VERSION ""

NS_ :

BS_:

BU_: GW BMS PDU EDS_F VCU EAC EVCC
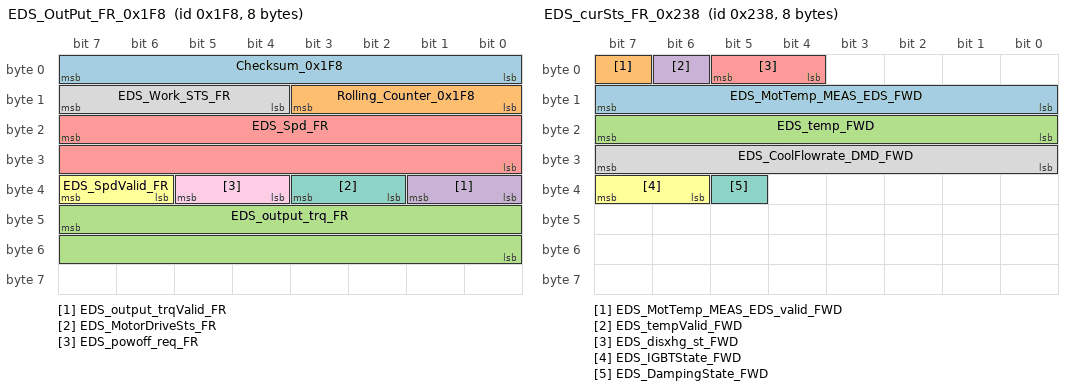
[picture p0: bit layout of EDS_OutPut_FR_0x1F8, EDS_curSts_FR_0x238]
BO_ 504 EDS_OutPut_FR_0x1F8: 8 EDS_F
 SG_ Checksum_0x1F8 : 7|8@0+ (1,0) [0|255] "" GW,BMS,VCU
 SG_ Rolling_Counter_0x1F8 : 11|4@0+ (1,0) [0|15] "" GW,BMS,VCU
 SG_ EDS_output_trq_FR : 47|16@0+ (1,-2000) [-2000|2000] "Nm" GW,BMS,VCU
 SG_ EDS_output_trqValid_FR : 33|2@0+ (1,0) [0|1] "" GW,BMS,VCU
 SG_ EDS_Spd_FR : 23|16@0+ (1,-20000) [-20000|20000] "rpm" GW,BMS,VCU
 SG_ EDS_SpdValid_FR : 39|2@0+ (1,0) [0|1] "" GW,BMS,VCU
 SG_ EDS_MotorDriveSts_FR : 35|2@0+ (1,0) [0|3] "" GW,BMS,VCU
 SG_ EDS_Work_STS_FR : 15|4@0+ (1,0) [0|15] "" GW,BMS,VCU
 SG_ EDS_powoff_req_FR : 37|2@0+ (1,0) [0|1] "" GW,BMS,VCU

BO_ 680 EDS_Power_FR_0x2A8: 8 EDS_F
 SG_ Checksum_0x2A8 : 7|8@0+ (1,0) [0|255] "" VCU
 SG_ Rolling_Counter_0x2A8 : 11|4@0+ (1,0) [0|15] "" VCU
 SG_ EDS_MotorSerialNum_FWD : 15|1@0+ (1,0) [0|1] "" VCU
 SG_ EDS_MinTrq_FWD : 39|16@0+ (1,-2000) [-2000|2000] "Nm" VCU
 SG_ EDS_MaxTrq_FWD : 23|16@0+ (1,-2000) [-2000|2000] "Nm" VCU

BO_ 568 EDS_curSts_FR_0x238: 8 EDS_F
 SG_ EDS_MotTemp_MEAS_EDS_FWD : 15|8@0+ (1,-40) [-40|215] "degree" VCU
 SG_ EDS_MotTemp_MEAS_EDS_valid_FWD : 7|1@0+ (1,0) [0|1] "" VCU
 SG_ EDS_temp_FWD : 23|8@0+ (1,-40) [-40|215] "degree" VCU
 SG_ EDS_tempValid_FWD : 6|1@0+ (1,0) [0|1] "" VCU
 SG_ EDS_disxhg_st_FWD : 5|2@0+ (1,0) [0|3] "" VCU
 SG_ EDS_IGBTState_FWD : 39|2@0+ (1,0) [0|3] "" VCU
 SG_ EDS_DampingState_FWD : 37|1@0+ (1,0) [0|1] "" VCU
 SG_ EDS_CoolFlowrate_DMD_FWD : 31|8@0+ (0.1,0) [0|25.4] "L/min" VCU

BO_ 1080 EDS_Error_FR_0x438: 8 EDS_F
 SG_ EDS_FailNum_ERR_FWD : 7|8@0+ (1,0) [0|255] "" BMS,VCU
 SG_ EDS_FailGrade_ERR_FWD : 10|3@0+ (1,0) [0|7] "" BMS,VCU
 SG_ EDS_MotOverTempAlarm_FWD : 11|1@0+ (1,0) [0|1] "" BMS,VCU
 SG_ EDS_MotOverTempFault_FWD : 12|1@0+ (1,0) [0|1] "" BMS,VCU
 SG_ EDS_MotTempSenFault_FWD : 13|1@0+ (1,0) [0|1] "" BMS,VCU
 SG_ EDS_EDSOverTempUFault_FWD : 14|1@0+ (1,0) [0|1] "" BMS,VCU
 SG_ EDS_EDSOverTempVFault_FWD : 15|1@0+ (1,0) [0|1] "" BMS,VCU
 SG_ EDS_EDSOverTempWFault_FWD : 16|1@0+ (1,0) [0|1] "" BMS,VCU
 SG_ EDS_EDSOverTempAlarm_FWD : 17|1@0+ (1,0) [0|1] "" BMS,VCU
 SG_ EDS_TCoolantOvHi_FWD : 18|1@0+ (1,0) [0|1] "" BMS,VCU
 SG_ EDS_EDSTempCmpAlarm_FWD : 19|1@0+ (1,0) [0|1] "" BMS,VCU
 SG_ EDS_EDSPhaOvCurentHWFault_FWD : 20|1@0+ (1,0) [0|1] "" BMS,VCU
 SG_ EDS_EDSphaOffCalFault_FWD : 21|1@0+ (1,0) [0|1] "" BMS,VCU
 SG_ EDS_EDSOverIdcLnkAlarm_FWD : 22|1@0+ (1,0) [0|1] "" BMS,VCU
 SG_ EDS_EDSHVOverVoltageAlarm_FWD : 23|1@0+ (1,0) [0|1] "" BMS,VCU
 SG_ EDS_EDSHVOverVoltageFault_FWD : 24|1@0+ (1,0) [0|1] "" BMS,VCU
 SG_ EDS_EDSHVUnderVoltageAlarm_FWD : 25|1@0+ (1,0) [0|1] "" BMS,VCU
 SG_ EDS_EDSHVUnderVoltageFault_FWD : 26|1@0+ (1,0) [0|1] "" BMS,VCU
 SG_ EDS_RunToDischaErr_FWD : 27|1@0+ (1,0) [0|1] "" BMS,VCU
 SG_ EDS_12VOverVoltageAlarm_FWD : 28|1@0+ (1,0) [0|1] "" BMS,VCU
 SG_ EDS_12VUnderVoltageAlarm_FWD : 29|1@0+ (1,0) [0|1] "" BMS,VCU
 SG_ EDS_MotOverAlarm_FWD : 30|1@0+ (1,0) [0|1] "" BMS,VCU
 SG_ EDS_MotOverFault_FWD : 31|1@0+ (1,0) [0|1] "" BMS,VCU
 SG_ EDS_iDcLnkOvCLimFail_FWD : 32|1@0+ (1,0) [0|1] "" BMS,VCU
 SG_ EDS_MotBlockedFault_FWD : 33|1@0+ (1,0) [0|1] "" BMS,VCU
 SG_ EDS_RSLErr_FWD : 34|1@0+ (1,0) [0|1] "" BMS,VCU
 SG_ EDS_MotTrqLimFault_FWD : 35|1@0+ (1,0) [0|1] "" BMS,VCU
 SG_ EDS_ResolverOffsetAngle_FWD : 36|1@0+ (1,0) [0|1] "" BMS,VCU
 SG_ EDS_EDSDisChgFault_FWD : 37|1@0+ (1,0) [0|1] "" BMS,VCU
 SG_ EDS_IGBTFault_FWD : 38|1@0+ (1,0) [0|1] "" BMS,VCU
 SG_ EDS_CANBusoffFault_FWD : 39|1@0+ (1,0) [0|1] "" BMS,VCU
 SG_ EDS_TDrvBoardOvHiWarn_FWD : 40|1@0+ (1,0) [0|1] "" BMS,VCU
 SG_ EDS_TIGBTOvHiFault_FWD : 41|1@0+ (1,0) [0|1] "" BMS,VCU
 SG_ EDS_TIGBTOvHiWarn_FWD : 42|1@0+ (1,0) [0|1] "" BMS,VCU
 SG_ EDS_IOHWABSampFail_FWD : 43|1@0+ (1,0) [0|1] "" BMS,VCU
 SG_ EDS_EDSOpenFault_FWD : 44|1@0+ (1,0) [0|1] "" BMS,VCU
 SG_ EDS_MotorOpenFault_FWD : 45|1@0+ (1,0) [0|1] "" BMS,VCU
 SG_ EDS_EmacBlkdWarn_FWD : 47|1@0+ (1,0) [0|1] "" BMS,VCU
 SG_ EDS_VerMatchFailureErr_FWD : 48|1@0+ (1,0) [0|1] "" BMS,VCU
 SG_ EDS_DiashCirNoPsblErr_FWD : 49|1@0+ (1,0) [0|1] "" BMS,VCU
 SG_ EDS_OperOutdRngErr_FWD : 50|1@0+ (1,0) [0|1] "" BMS,VCU
 SG_ EDS_PhaseLossFaultErr_FWD : 51|1@0+ (1,0) [0|1] "" BMS,VCU
 SG_ EDS_CPLDFault_FWD : 52|1@0+ (1,0) [0|1] "" BMS,VCU
 SG_ EDS_CPLDFaultBaseSpd_FWD : 53|1@0+ (1,0) [0|1] "" BMS,VCU
 SG_ EDS_IOHWABNen33Fail_FWD : 54|1@0+ (1,0) [0|1] "" BMS,VCU
 SG_ EDS_HvMcuSlightFault_RWD : 55|1@0+ (1,0) [0|1] "" BMS,VCU
 SG_ EDS_HvMcuSevFault_FWD : 56|1@0+ (1,0) [0|1] "" BMS,VCU
 SG_ EDS_EDSPhaSampHWFault_FWD : 57|1@0+ (1,0) [0|1] "" BMS,VCU
 SG_ EDS_IsOvHiErr_FWD : 58|1@0+ (1,0) [0|1] "" BMS,VCU
 SG_ EDS_CanRollingCounterErr_FWD : 59|1@0+ (1,0) [0|1] "" BMS,VCU
 SG_ EDS_CanTimeoutErr_FWD : 60|1@0+ (1,0) [0|1] "" BMS,VCU
 SG_ EDS_CrashFault_FWD : 61|1@0+ (1,0) [0|1] "" BMS,VCU

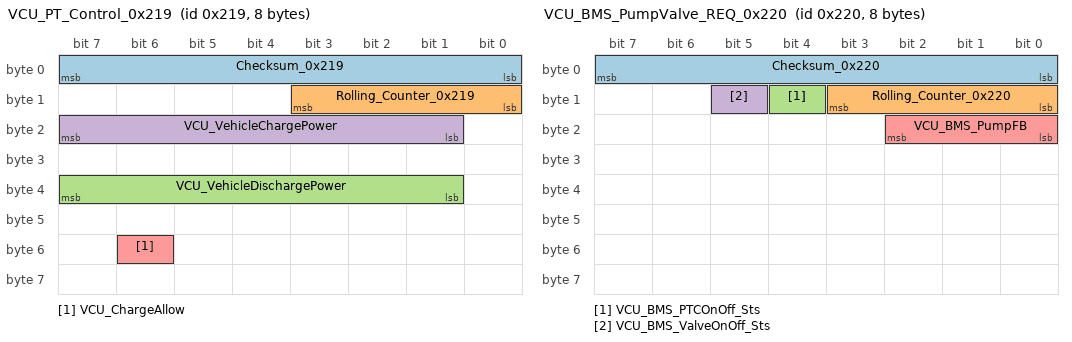
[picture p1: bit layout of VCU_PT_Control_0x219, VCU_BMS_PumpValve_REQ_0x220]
BO_ 537 VCU_PT_Control_0x219: 8 VCU
 SG_ Checksum_0x219 : 7|8@0+ (1,0) [0|255] "" GW,BMS
 SG_ Rolling_Counter_0x219 : 11|4@0+ (1,0) [0|15] "" GW,BMS
 SG_ VCU_VehicleDischargePower : 39|7@0+ (1,0) [0|100] "%" GW
 SG_ VCU_VehicleChargePower : 23|7@0+ (1,0) [0|100] "%" GW
 SG_ VCU_ChargeAllow : 54|1@0+ (1,0) [0|1] "" BMS

BO_ 544 VCU_BMS_PumpValve_REQ_0x220: 8 VCU
 SG_ Checksum_0x220 : 7|8@0+ (1,0) [0|255] "" BMS
 SG_ Rolling_Counter_0x220 : 11|4@0+ (1,0) [0|15] "" BMS
 SG_ VCU_BMS_PTCOnOff_Sts : 12|1@0+ (1,0) [0|1] "" BMS
 SG_ VCU_BMS_ValveOnOff_Sts : 13|1@0+ (1,0) [0|1] "" BMS
 SG_ VCU_BMS_PumpFB : 18|3@0+ (1,0) [0|7] "" BMS

BO_ 757 VCU_Chgcontrol_0x2F5: 8 VCU
 SG_ VCU_Charge_Control : 23|2@0+ (1,0) [0|3] "" BMS,PDU,EVCC
 SG_ VCU_AC_chargeSock_temp1 : 18|11@0+ (0.1,-50) [-50|100] "degree" BMS,EVCC
 SG_ VCU_DC_chargeSock_temp1 : 34|11@0+ (0.1,-50) [-50|100] "degree" BMS,EVCC
 SG_ VCU_DC_chargeSock_temp2 : 50|11@0+ (0.1,-50) [-50|100] "degree" BMS,EVCC

BO_ 725 VCU_DCDCcontrol_0x2D5: 8 VCU
 SG_ VCU_DCDC_Output_REQ : 55|1@0+ (1,0) [0|1] "" GW,PDU
 SG_ VCU_DCDC_OutVoltage_REQ : 32|9@0+ (0.1,0) [0|50] "V" GW,PDU
 SG_ VCU_DCDCAllowedPower : 16|9@0+ (0.1,0) [0|50] "KW" GW,PDU

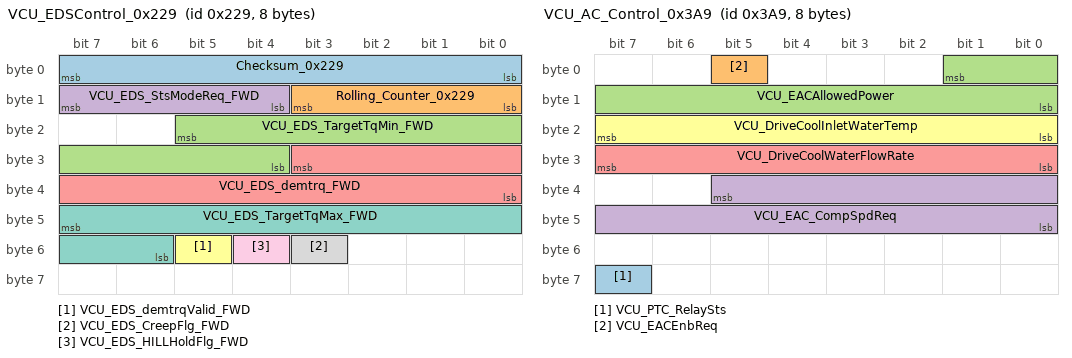
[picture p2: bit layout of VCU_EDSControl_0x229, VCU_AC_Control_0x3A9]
BO_ 553 VCU_EDSControl_0x229: 8 VCU
 SG_ Checksum_0x229 : 7|8@0+ (1,0) [0|255] "" EDS_F
 SG_ Rolling_Counter_0x229 : 11|4@0+ (1,0) [0|15] "" EDS_F
 SG_ VCU_EDS_TargetTqMin_FWD : 21|10@0+ (1,-500) [-500|0] "Nm" EDS_F
 SG_ VCU_EDS_StsModeReq_FWD : 15|4@0+ (1,0) [0|15] "" EDS_F
 SG_ VCU_EDS_demtrq_FWD : 27|12@0+ (0.5,-500) [-500|500] "Nm" EDS_F
 SG_ VCU_EDS_demtrqValid_FWD : 53|1@0+ (1,0) [0|1] "" EDS_F
 SG_ VCU_EDS_TargetTqMax_FWD : 47|10@0+ (1,0) [0|500] "Nm" EDS_F
 SG_ VCU_EDS_CreepFlg_FWD : 51|1@0+ (1,0) [0|1] "" Vector__XXX
 SG_ VCU_EDS_HILLHoldFlg_FWD : 52|1@0+ (1,0) [0|1] "" Vector__XXX

BO_ 937 VCU_AC_Control_0x3A9: 8 VCU
 SG_ VCU_PTC_RelaySts : 63|1@0+ (1,0) [0|1] "" GW,BMS,EAC
 SG_ VCU_EACEnbReq : 5|1@0+ (1,0) [0|1] "" GW,EAC
 SG_ VCU_EACAllowedPower : 1|10@0+ (0.1,0) [0|100] "KW" GW,EAC
 SG_ VCU_EAC_CompSpdReq : 37|14@0+ (1,0) [0|16383] "rpm" GW,EAC
 SG_ VCU_DriveCoolWaterFlowRate : 31|8@0+ (0.1,0) [0|25.4] "L/min" GW,EDS_F,EAC
 SG_ VCU_DriveCoolInletWaterTemp : 23|8@0+ (1,-40) [-40|215] "degree" GW,EDS_F,EAC

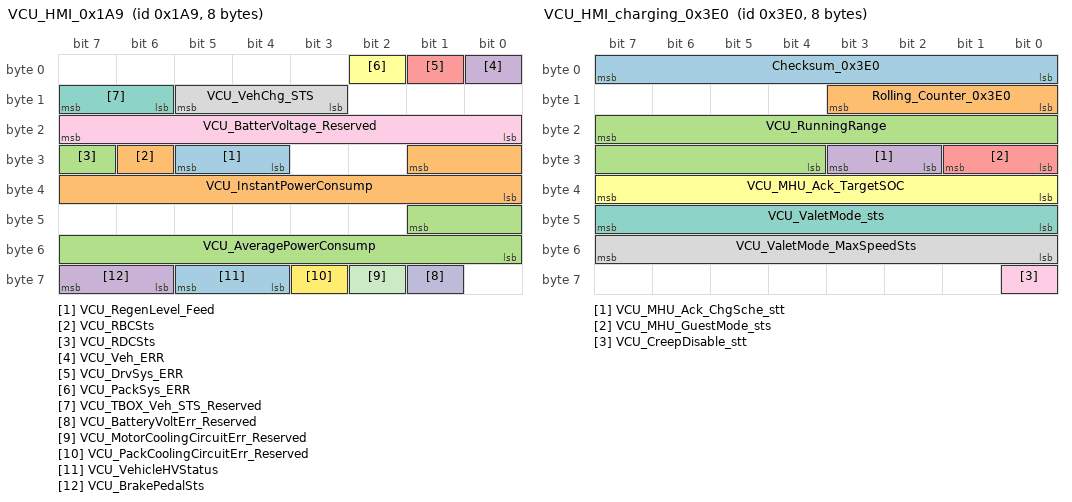
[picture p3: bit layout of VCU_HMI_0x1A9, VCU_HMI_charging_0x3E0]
BO_ 425 VCU_HMI_0x1A9: 8 VCU
 SG_ VCU_RegenLevel_Feed : 29|2@0+ (1,0) [0|3] "" GW
 SG_ VCU_RBCSts : 30|1@0+ (1,0) [0|1] "" GW
 SG_ VCU_RDCSts : 31|1@0+ (1,0) [0|1] "" GW
 SG_ VCU_Veh_ERR : 0|1@0+ (1,0) [0|1] "" GW,BMS
 SG_ VCU_DrvSys_ERR : 1|1@0+ (1,0) [0|1] "" GW,BMS
 SG_ VCU_PackSys_ERR : 2|1@0+ (1,0) [0|1] "" GW,BMS
 SG_ VCU_TBOX_Veh_STS_Reserved : 15|2@0+ (1,0) [0|3] "" GW,BMS
 SG_ VCU_VehChg_STS : 13|3@0+ (1,0) [0|7] "" GW,BMS
 SG_ VCU_BatterVoltage_Reserved : 23|8@0+ (0.07,0) [0|17.85] "V" GW,BMS
 SG_ VCU_BatteryVoltErr_Reserved : 57|1@0+ (1,0) [0|1] "" GW,BMS
 SG_ VCU_MotorCoolingCircuitErr_Reserved : 58|1@0+ (1,0) [0|1] "" GW,BMS
 SG_ VCU_PackCoolingCircuitErr_Reserved : 59|1@0+ (1,0) [0|1] "" GW,BMS
 SG_ VCU_VehicleHVStatus : 61|2@0+ (1,0) [0|3] "" GW,BMS,EVCC
 SG_ VCU_InstantPowerConsump : 25|10@0+ (0.1,0) [0|100] "kwh/100km" GW,BMS
 SG_ VCU_AveragePowerConsump : 41|10@0+ (0.1,0) [0|100] "kwh/100km" GW,BMS
 SG_ VCU_BrakePedalSts : 63|2@0+ (1,0) [0|3] "" GW,BMS

BO_ 441 VCU_HMI2_0x1B9: 8 VCU
 SG_ VCU_MCUConsumepower : 15|9@0+ (0.1,0) [0|50] "kw" GW
 SG_ VCU_EACConsumepower : 16|9@0+ (0.1,0) [0|50] "kw" GW
 SG_ VCU_DCDCConsumepower : 32|9@0+ (0.1,0) [0|50] "kw" GW
 SG_ VCU_PTCConsumepower : 48|9@0+ (0.1,0) [0|50] "kw" GW

BO_ 992 VCU_HMI_charging_0x3E0: 8 VCU
 SG_ Checksum_0x3E0 : 7|8@0+ (1,0) [0|255] "" GW
 SG_ Rolling_Counter_0x3E0 : 11|4@0+ (1,0) [0|15] "" GW
 SG_ VCU_RunningRange : 23|12@0+ (0.5,0) [0|2047] "km" GW
 SG_ VCU_MHU_Ack_ChgSche_stt : 27|2@0+ (1,0) [0|3] "" GW
 SG_ VCU_MHU_GuestMode_sts : 25|2@0+ (1,0) [0|3] "" GW
 SG_ VCU_MHU_Ack_TargetSOC : 39|8@0+ (1,0) [0|100] "%" GW,BMS
 SG_ VCU_ValetMode_sts : 47|8@0+ (1,0) [0|255] "" GW
 SG_ VCU_ValetMode_MaxSpeedSts : 55|8@0+ (1,0) [0|255] "kph" GW
 SG_ VCU_CreepDisable_stt : 56|1@0+ (1,0) [0|1] "" GW

BO_ 409 VCU_Sts_0x199: 8 VCU
 SG_ Checksum_0x199 : 7|8@0+ (1,0) [0|255] "" BMS,EVCC
 SG_ Rolling_Counter_0x199 : 11|4@0+ (1,0) [0|15] "" BMS,EVCC
 SG_ VCU_VehFailGrade_ERR : 22|3@0+ (1,0) [0|7] "" Vector__XXX
 SG_ VCU_BMS_HVOnOff_REQ : 19|2@0+ (1,0) [0|1] "" BMS,EVCC
 SG_ VCU_Vehicle_Mode : 31|4@0+ (1,0) [0|15] "" BMS,EVCC

BO_ 889 VCU_Sts2_0x379: 8 VCU
 SG_ VCU_DriveCoolWaterPumpSts : 2|3@0+ (1,0) [0|5] "" GW
 SG_ VCU_DriveCoolWaterDuty : 14|7@0+ (1,0) [0|100] "%" GW
 SG_ VCU_BatteryWaterPumpSts_reserved : 30|3@0+ (1,0) [0|7] "" GW
 SG_ VCU_BatteryWaterPumpDuty_reserved : 22|7@0+ (1,0) [0|100] "%" GW
 SG_ VCU_DriveMode : 5|3@0+ (1,0) [0|7] "" GW
 SG_ VCU_ActualGear : 26|3@0+ (1,0) [0|7] "" GW
 SG_ VCU_ACTGearValid : 27|1@0+ (1,0) [0|1] "" GW
 SG_ VCU_AccPedal1OutRange : 31|1@0+ (1,0) [0|1] "" GW
 SG_ VCU_AccPedal2OutRange : 33|1@0+ (1,0) [0|1] "" GW
 SG_ VCU_BrkPedal1OutRange : 35|1@0+ (1,0) [0|1] "" GW
 SG_ VCU_BrkPedal2OutRange : 37|1@0+ (1,0) [0|1] "" GW
 SG_ VCU_BrkPedalPct : 47|8@0+ (0.4,0) [0|100] "%" GW
 SG_ VCU_AccPedalPosition : 55|8@0+ (0.4,0) [0|100] "%" GW
 SG_ VCU_AccPedalPositionValid : 63|1@0+ (1,0) [0|1] "" GW
 SG_ VCU_SocDisplay_EST : 62|7@0+ (1,0) [0|100] "%" GW,EVCC
 SG_ VCU_PowerLimit : 15|1@0+ (1,0) [0|1] "" GW
 SG_ VCU_CruiseCtrlSts : 39|2@0+ (1,0) [0|3] "" GW
 SG_ VCU_LowSOC_ERR : 23|1@0+ (1,0) [0|1] "" GW

BO_ 905 VCU_Sts3_0x389: 8 VCU
 SG_ VCU_FanControl_Sts : 1|2@0+ (1,0) [0|3] "" GW
 SG_ VCU_HVACInletWateTemp : 55|8@0+ (1,-40) [-40|215] "degree" GW
 SG_ VCU_IMMO_Sts : 35|2@0+ (1,0) [0|2] "" GW
 SG_ VCU_VacuumSts_reserved : 39|2@0+ (1,0) [0|3] "" GW
 SG_ VCU_VacuumPresWrn : 37|2@0+ (1,0) [0|3] "" GW

BO_ 273 VCU_Sts4_0x111: 8 VCU
 SG_ VCU_Sts : 7|8@0+ (1,0) [0|254] "" Vector__XXX

BO_ 1145 VCU_Error_0x479: 8 VCU
 SG_ VCU_OtherFaultNum_Reserved : 7|8@0+ (1,0) [0|255] "" Vector__XXX
 SG_ VCU_EDSCAN_ERR : 32|1@0+ (1,0) [0|1] "" Vector__XXX
 SG_ VCU_BmsCAN_ERR : 33|1@0+ (1,0) [0|1] "" Vector__XXX
 SG_ VCU_DcdcCAN_ERR : 34|1@0+ (1,0) [0|1] "" Vector__XXX
 SG_ VCU_AbsCAN_ERR : 35|1@0+ (1,0) [0|1] "" Vector__XXX
 SG_ VCU_AcmCAN_ERR : 36|1@0+ (1,0) [0|1] "" Vector__XXX
 SG_ VCU_XgwCAN_ERR : 37|1@0+ (1,0) [0|1] "" Vector__XXX
 SG_ VCU_ObcCAN_ERR : 38|1@0+ (1,0) [0|1] "" Vector__XXX
 SG_ VCU_BcmCAN_ERR_reserved : 39|1@0+ (1,0) [0|1] "" Vector__XXX
 SG_ VCU_WaterPump_ERR : 40|1@0+ (1,0) [0|1] "" Vector__XXX
 SG_ VCU_BrakeSys_Err : 41|1@0+ (1,0) [0|1] "" Vector__XXX
 SG_ VCU_PreChgFail_ERR_Reserved : 42|1@0+ (1,0) [0|1] "" Vector__XXX
 SG_ VCU_LowBattery_ERR : 43|1@0+ (1,0) [0|1] "" Vector__XXX
 SG_ VCU_AccPed_ERR : 44|1@0+ (1,0) [0|1] "" Vector__XXX
 SG_ VCU_BrkPed_ERR : 45|1@0+ (1,0) [0|1] "" Vector__XXX
 SG_ VCU_EPSCAN_ERR : 46|1@0+ (1,0) [0|1] "" Vector__XXX
 SG_ VCU_PtcModu_ERR_Reserved : 47|1@0+ (1,0) [0|1] "" Vector__XXX
 SG_ VCU_Shift_ERR : 48|1@0+ (1,0) [0|1] "" GW
 SG_ VCU_FlgHVIL_ERR : 49|1@0+ (1,0) [0|1] "" Vector__XXX
 SG_ VCU_EKSCAN_ERR : 50|1@0+ (1,0) [0|1] "" Vector__XXX
 SG_ VCU_VehLvInit_ERR_Reserved : 51|1@0+ (1,0) [0|1] "" Vector__XXX
 SG_ VCU_EacCAN_ERR : 52|1@0+ (1,0) [0|1] "" Vector__XXX
 SG_ VCU_EAC_CompFltStat_ERR : 53|1@0+ (1,0) [0|1] "" Vector__XXX

BO_ 745 VCU_Mileage_0x2E9: 8 VCU
 SG_ Checksum_0x2E9 : 7|8@0+ (1,0) [0|255] "" GW
 SG_ Rolling_Counter_0x2E9 : 11|4@0+ (1,0) [0|15] "" GW
 SG_ VCU_RemainingMileage : 23|32@0+ (0.1,0) [0|1000] "KM" GW
 SG_ VCU_SetCruiseSpd : 55|8@0+ (1,0) [0|200] "km/h" GW

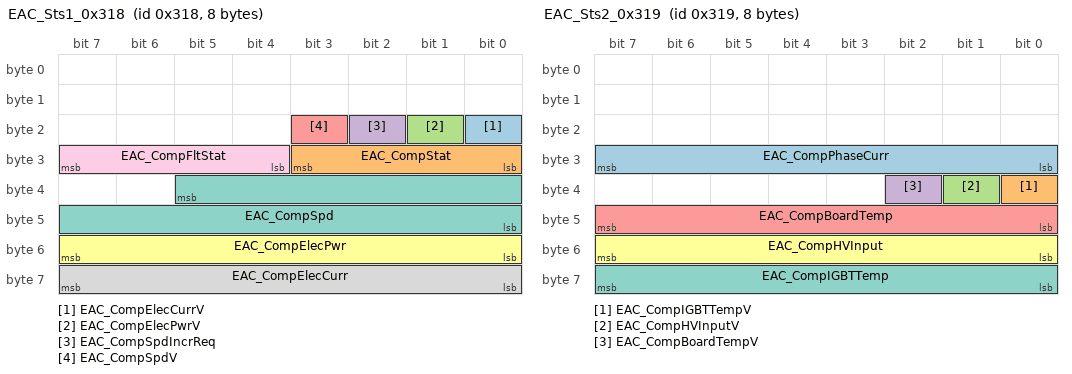
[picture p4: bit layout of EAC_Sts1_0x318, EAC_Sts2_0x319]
BO_ 792 EAC_Sts1_0x318: 8 EAC
 SG_ EAC_CompElecCurrV : 16|1@0+ (1,0) [0|1] "" GW,BMS,VCU
 SG_ EAC_CompStat : 27|4@0+ (1,0) [0|15] "" GW,VCU
 SG_ EAC_CompElecPwrV : 17|1@0+ (1,0) [0|1] "" GW,BMS,VCU
 SG_ EAC_CompSpdIncrReq : 18|1@0+ (1,0) [0|1] "" GW,VCU
 SG_ EAC_CompSpdV : 19|1@0+ (1,0) [0|1] "" GW,VCU
 SG_ EAC_CompElecPwr : 55|8@0+ (40,0) [0|10200] "W" GW,BMS,VCU
 SG_ EAC_CompSpd : 37|14@0+ (1,0) [0|16383] "rpm" GW,VCU
 SG_ EAC_CompElecCurr : 63|8@0+ (0.2,0) [0|51] "A" GW,VCU
 SG_ EAC_CompFltStat : 31|4@0+ (1,0) [0|15] "" GW,VCU

BO_ 793 EAC_Sts2_0x319: 8 EAC
 SG_ EAC_CompPhaseCurr : 31|8@0+ (0.2,0) [0|51] "A" Vector__XXX
 SG_ EAC_CompIGBTTempV : 32|1@0+ (1,0) [0|1] "" VCU
 SG_ EAC_CompHVInputV : 33|1@0+ (1,0) [0|1] "" VCU
 SG_ EAC_CompBoardTempV : 34|1@0+ (1,0) [0|1] "" VCU
 SG_ EAC_CompBoardTemp : 47|8@0+ (1,-40) [-40|215] "deg C" VCU
 SG_ EAC_CompHVInput : 55|8@0+ (4,0) [0|1020] "V" VCU
 SG_ EAC_CompIGBTTemp : 63|8@0+ (1,-40) [-40|215] "deg C" VCU

BO_ 524 GW_IPC_ODO_0x20C: 8 GW
 SG_ Checksum_0x20C : 7|8@0+ (1,0) [0|255] "" BMS,PDU,EDS_F,VCU,EAC,EVCC
 SG_ Rolling_Counter_0x20C : 11|4@0+ (1,0) [0|15] "" BMS,PDU,EDS_F,VCU,EAC,EVCC
 SG_ IPC_ODO : 31|20@0+ (1,0) [0|999999] "km" BMS,PDU,EDS_F,VCU,EAC,EVCC

BO_ 703 GW_IPC_Information_0x2BF: 8 GW
 SG_ IPC_TripA : 7|16@0+ (0.1,0) [0|999.9] "km" Vector__XXX
 SG_ IPC_AverageSpeedTripA : 27|12@0+ (0.0625,0) [0|250] "km/h" Vector__XXX
 SG_ IPC_AverageConsumptionTripA : 23|10@0+ (0.1,0) [0|100] "kwh/100km" Vector__XXX
 SG_ IPC_ParkBrakeSts : 29|2@0+ (1,0) [0|3] "" VCU,EVCC
 SG_ IPC_VehSpd : 54|15@0+ (0.01,0) [0|327.66] "kph" BMS,PDU,EDS_F,VCU,EAC,EVCC

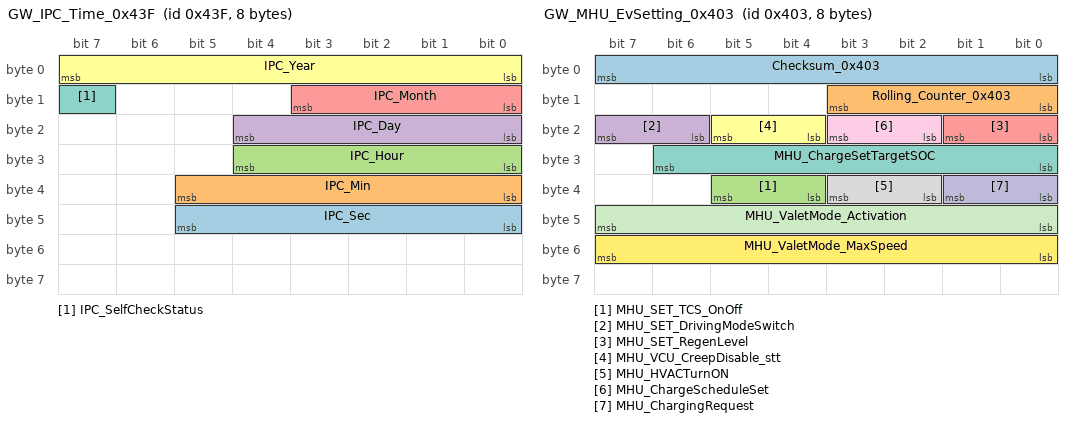
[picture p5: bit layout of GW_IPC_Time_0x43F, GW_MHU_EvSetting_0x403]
BO_ 1087 GW_IPC_Time_0x43F: 8 GW
 SG_ IPC_Sec : 45|6@0+ (1,0) [0|59] "second" BMS,PDU,EDS_F,VCU,EAC,EVCC
 SG_ IPC_Min : 37|6@0+ (1,0) [0|59] "min" BMS,PDU,EDS_F,VCU,EAC,EVCC
 SG_ IPC_Hour : 28|5@0+ (1,0) [0|23] "hour" BMS,PDU,EDS_F,VCU,EAC,EVCC
 SG_ IPC_Day : 20|5@0+ (1,0) [1|31] "" BMS,PDU,EDS_F,VCU,EAC,EVCC
 SG_ IPC_Month : 11|4@0+ (1,0) [1|12] "" BMS,PDU,EDS_F,VCU,EAC,EVCC
 SG_ IPC_Year : 7|8@0+ (1,2000) [2000|2255] "" BMS,PDU,EDS_F,VCU,EAC,EVCC
 SG_ IPC_SelfCheckStatus : 15|1@0+ (1,0) [0|1] "" BMS,PDU,EDS_F,VCU,EAC,EVCC

BO_ 1074 GW_TELEMATICS_SERVICES_0x432: 8 GW
 SG_ Checksum_0x432 : 7|8@0+ (1,0) [0|255] "" BMS,PDU,EDS_F,VCU,EAC
 SG_ Rolling_Counter_0x432 : 11|4@0+ (1,0) [0|14] "" BMS,PDU,EDS_F,VCU,EAC
 SG_ MHU_FOTA_State : 15|4@0+ (1,0) [0|14] "" BMS,PDU,EDS_F,VCU,EAC
 SG_ MHU_FOTA_Error_Code : 23|8@0+ (1,0) [0|255] "" BMS,PDU,EDS_F,VCU,EAC

BO_ 1027 GW_MHU_EvSetting_0x403: 8 GW
 SG_ Checksum_0x403 : 7|8@0+ (1,0) [0|255] "" BMS,VCU,EVCC
 SG_ Rolling_Counter_0x403 : 11|4@0+ (1,0) [0|15] "" BMS,VCU,EVCC
 SG_ MHU_SET_TCS_OnOff : 37|2@0+ (1,0) [0|3] "" BMS,VCU
 SG_ MHU_SET_DrivingModeSwitch : 23|2@0+ (1,0) [0|3] "" BMS,VCU
 SG_ MHU_SET_RegenLevel : 17|2@0+ (1,0) [0|3] "" BMS,VCU
 SG_ MHU_VCU_CreepDisable_stt : 21|2@0+ (1,0) [0|3] "" BMS,VCU
 SG_ MHU_ChargeSetTargetSOC : 30|7@0+ (1,0) [10|100] "Percentage" BMS,VCU,EVCC
 SG_ MHU_HVACTurnON : 35|2@0+ (1,0) [0|3] "" BMS,VCU
 SG_ MHU_ChargeScheduleSet : 19|2@0+ (1,0) [0|3] "" BMS,VCU,EVCC
 SG_ MHU_ChargingRequest : 33|2@0+ (1,0) [0|3] "" BMS,VCU,EVCC
 SG_ MHU_ValetMode_Activation : 47|8@0+ (1,0) [0|254] "" BMS,VCU
 SG_ MHU_ValetMode_MaxSpeed : 55|8@0+ (1,0) [0|254] "kph" BMS,VCU

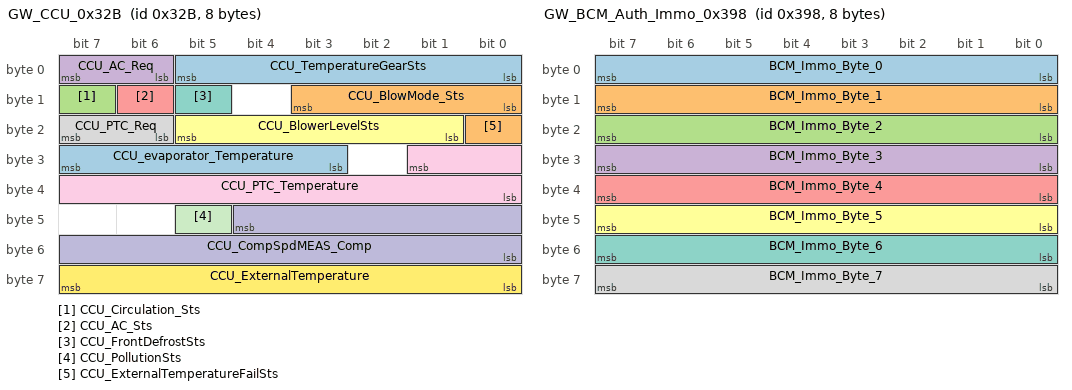
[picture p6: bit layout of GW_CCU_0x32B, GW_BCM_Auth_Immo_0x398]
BO_ 811 GW_CCU_0x32B: 8 GW
 SG_ CCU_TemperatureGearSts : 5|6@0+ (1,0) [0|63] "" VCU
 SG_ CCU_BlowMode_Sts : 11|4@0+ (1,0) [0|15] "" VCU
 SG_ CCU_Circulation_Sts : 15|1@0+ (1,0) [0|1] "" VCU
 SG_ CCU_AC_Req : 7|2@0+ (1,0) [0|3] "" VCU
 SG_ CCU_AC_Sts : 14|1@0+ (1,0) [0|1] "" VCU
 SG_ CCU_BlowerLevelSts : 21|5@0+ (1,0) [0|9] "" VCU
 SG_ CCU_FrontDefrostSts : 13|1@0+ (1,0) [0|1] "" VCU
 SG_ CCU_PTC_Req : 23|2@0+ (1,0) [0|3] "" VCU
 SG_ CCU_PTC_Temperature : 25|10@0+ (0.1,0) [0|100] "°C" VCU
 SG_ CCU_CompSpdMEAS_Comp : 44|13@0+ (1,0) [0|8191] "rpm" VCU
 SG_ CCU_PollutionSts : 45|1@0+ (1,0) [0|1] "" VCU
 SG_ CCU_ExternalTemperature : 63|8@0+ (0.5,-40) [-40|87] "°C" BMS,PDU,EDS_F,VCU,EAC,EVCC
 SG_ CCU_evaporator_Temperature : 31|5@0+ (1,-10) [-10|20] "°C" Vector__XXX
 SG_ CCU_ExternalTemperatureFailSts : 16|1@0+ (1,0) [0|1] "" BMS,PDU,EDS_F,VCU,EAC,EVCC

BO_ 1015 GW_MFS_Control_Button_0x3F7: 8 GW
 SG_ MFS_OK_Control : 7|3@0+ (1,0) [0|7] "Bit" Vector__XXX
 SG_ MFS_SourseControl : 4|3@0+ (1,0) [0|7] "Bit" Vector__XXX
 SG_ MFS_VoiceRecognitionOn_Off : 15|3@0+ (1,0) [0|7] "Bit" Vector__XXX
 SG_ MFS_TelephoneCall_EndCall : 12|3@0+ (1,0) [0|7] "Bit" Vector__XXX
 SG_ MFS_DownControl : 23|3@0+ (1,0) [0|7] "Bit" Vector__XXX
 SG_ MFS_UpControl : 20|3@0+ (1,0) [0|7] "Bit" Vector__XXX
 SG_ MFS_RightControl : 31|3@0+ (1,0) [0|7] "Bit" Vector__XXX
 SG_ MFS_LeftControl : 28|3@0+ (1,0) [0|7] "Bit" Vector__XXX
 SG_ MFS_CruiseOn_Off : 39|3@0+ (1,0) [0|7] "Bit" VCU
 SG_ MFS_Failure : 36|1@0+ (1,0) [0|1] "Bit" Vector__XXX
 SG_ MFS_ISAControl : 35|2@0+ (1,0) [0|3] "Bit" Vector__XXX
 SG_ MFS_LKAControl : 33|2@0+ (1,0) [0|3] "Bit" Vector__XXX
 SG_ MFS_CruiseGapDecrease : 47|3@0+ (1,0) [0|7] "Bit" VCU
 SG_ MFS_CruiseSpeedDecrease : 44|3@0+ (1,0) [0|7] "Bit" VCU
 SG_ MFS_CruiseSpeedIncrease : 55|3@0+ (1,0) [0|7] "Bit" VCU
 SG_ MFS_CruiseCancel : 52|2@0+ (1,0) [0|3] "Bit" VCU
 SG_ MFS_CruiseGapIncrease : 50|3@0+ (1,0) [0|7] "Bit" VCU

BO_ 920 GW_BCM_Auth_Immo_0x398: 8 GW
 SG_ BCM_Immo_Byte_0 : 7|8@0+ (1,0) [0|255] "" VCU
 SG_ BCM_Immo_Byte_1 : 15|8@0+ (1,0) [0|255] "" VCU
 SG_ BCM_Immo_Byte_2 : 23|8@0+ (1,0) [0|255] "" VCU
 SG_ BCM_Immo_Byte_3 : 31|8@0+ (1,0) [0|255] "" VCU
 SG_ BCM_Immo_Byte_4 : 39|8@0+ (1,0) [0|255] "" VCU
 SG_ BCM_Immo_Byte_5 : 47|8@0+ (1,0) [0|255] "" VCU
 SG_ BCM_Immo_Byte_6 : 55|8@0+ (1,0) [0|255] "" VCU
 SG_ BCM_Immo_Byte_7 : 63|8@0+ (1,0) [0|255] "" VCU

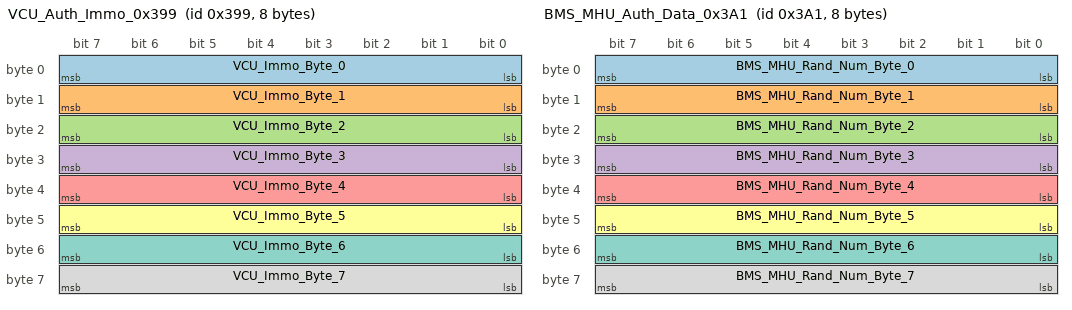
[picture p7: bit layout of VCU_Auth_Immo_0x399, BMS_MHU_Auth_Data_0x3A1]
BO_ 921 VCU_Auth_Immo_0x399: 8 VCU
 SG_ VCU_Immo_Byte_0 : 7|8@0+ (1,0) [0|255] "" GW
 SG_ VCU_Immo_Byte_1 : 15|8@0+ (1,0) [0|255] "" GW
 SG_ VCU_Immo_Byte_2 : 23|8@0+ (1,0) [0|255] "" GW
 SG_ VCU_Immo_Byte_3 : 31|8@0+ (1,0) [0|255] "" GW
 SG_ VCU_Immo_Byte_4 : 39|8@0+ (1,0) [0|255] "" GW
 SG_ VCU_Immo_Byte_5 : 47|8@0+ (1,0) [0|255] "" GW
 SG_ VCU_Immo_Byte_6 : 55|8@0+ (1,0) [0|255] "" GW
 SG_ VCU_Immo_Byte_7 : 63|8@0+ (1,0) [0|255] "" GW

BO_ 929  BMS_MHU_Auth_Data_0x3A1: 8 BMS
 SG_ BMS_MHU_Rand_Num_Byte_0 : 7|8@0+ (1,0) [0|255] "" GW
 SG_ BMS_MHU_Rand_Num_Byte_1 : 15|8@0+ (1,0) [0|255] "" GW
 SG_ BMS_MHU_Rand_Num_Byte_2 : 23|8@0+ (1,0) [0|255] "" GW
 SG_ BMS_MHU_Rand_Num_Byte_3 : 31|8@0+ (1,0) [0|255] "" GW
 SG_ BMS_MHU_Rand_Num_Byte_4 : 39|8@0+ (1,0) [0|255] "" GW
 SG_ BMS_MHU_Rand_Num_Byte_5 : 47|8@0+ (1,0) [0|255] "" GW
 SG_ BMS_MHU_Rand_Num_Byte_6 : 55|8@0+ (1,0) [0|255] "" GW
 SG_ BMS_MHU_Rand_Num_Byte_7 : 63|8@0+ (1,0) [0|255] "" GW

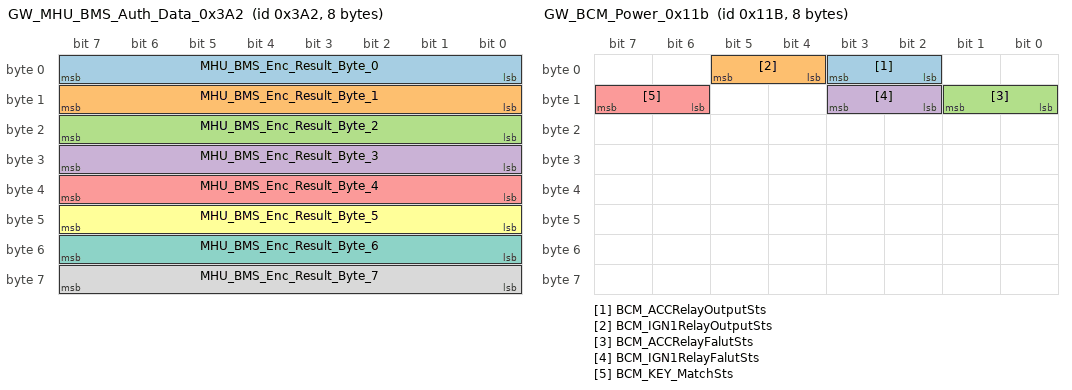
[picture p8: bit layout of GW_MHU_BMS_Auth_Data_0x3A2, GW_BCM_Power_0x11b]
BO_ 930 GW_MHU_BMS_Auth_Data_0x3A2: 8 GW
 SG_ MHU_BMS_Enc_Result_Byte_0 : 7|8@0+ (1,0) [0|255] "" BMS
 SG_ MHU_BMS_Enc_Result_Byte_1 : 15|8@0+ (1,0) [0|255] "" BMS
 SG_ MHU_BMS_Enc_Result_Byte_2 : 23|8@0+ (1,0) [0|255] "" BMS
 SG_ MHU_BMS_Enc_Result_Byte_3 : 31|8@0+ (1,0) [0|255] "" BMS
 SG_ MHU_BMS_Enc_Result_Byte_4 : 39|8@0+ (1,0) [0|255] "" BMS
 SG_ MHU_BMS_Enc_Result_Byte_5 : 47|8@0+ (1,0) [0|255] "" BMS
 SG_ MHU_BMS_Enc_Result_Byte_6 : 55|8@0+ (1,0) [0|255] "" BMS
 SG_ MHU_BMS_Enc_Result_Byte_7 : 63|8@0+ (1,0) [0|255] "" BMS

BO_ 274 GW_BCM_CLAMP_STAT_0x112: 8 GW
 SG_ Checksum_0x112 : 7|8@0+ (1,0) [0|255] "" BMS,PDU,EDS_F,VCU,EAC,EVCC
 SG_ Rolling_Counter_0x112 : 11|4@0+ (1,0) [0|15] "" BMS,PDU,EDS_F,VCU,EAC,EVCC
 SG_ STAT_Terminal : 34|3@0+ (1,0) [0|7] "Bit" BMS,PDU,EDS_F,VCU,EAC,EVCC
 SG_ STAT_CL30s_L_Reserved : 41|2@0+ (1,0) [0|3] "Bit" VCU

BO_ 976 GW_BCM_DoorSts_0x3D0: 8 GW
 SG_ BCM_STAT_DoorAjarDriver : 11|2@0+ (1,0) [0|3] "Bit" VCU,EVCC
 SG_ STAT_DoorLockDriver : 23|2@0+ (1,0) [0|3] "Bit" VCU,EVCC

BO_ 283 GW_BCM_Power_0x11b: 8 GW
 SG_ BCM_ACCRelayOutputSts : 3|2@0+ (1,0) [0|3] "" VCU
 SG_ BCM_IGN1RelayOutputSts : 5|2@0+ (1,0) [0|3] "" VCU
 SG_ BCM_ACCRelayFalutSts : 9|2@0+ (1,0) [0|3] "" VCU
 SG_ BCM_IGN1RelayFalutSts : 11|2@0+ (1,0) [0|3] "" VCU
 SG_ BCM_KEY_MatchSts : 15|2@0+ (1,0) [0|3] "" VCU

BO_ 266 GW_BCM_VOLTAGE_0x10a: 8 GW
 SG_ Checksum_0x10a : 7|8@0+ (1,0) [0|255] "" BMS,PDU,EDS_F,VCU,EAC,EVCC
 SG_ Rolling_Counter_0x10a : 11|4@0+ (1,0) [0|15] "" BMS,PDU,EDS_F,VCU,EAC,EVCC
 SG_ BCM_LVTop_up : 24|1@0+ (1,0) [0|1] "" VCU
 SG_ Ubatt_Reserved : 23|14@0+ (0.001,3) [3|18] "V" BMS,PDU,EDS_F,VCU,EAC,EVCC

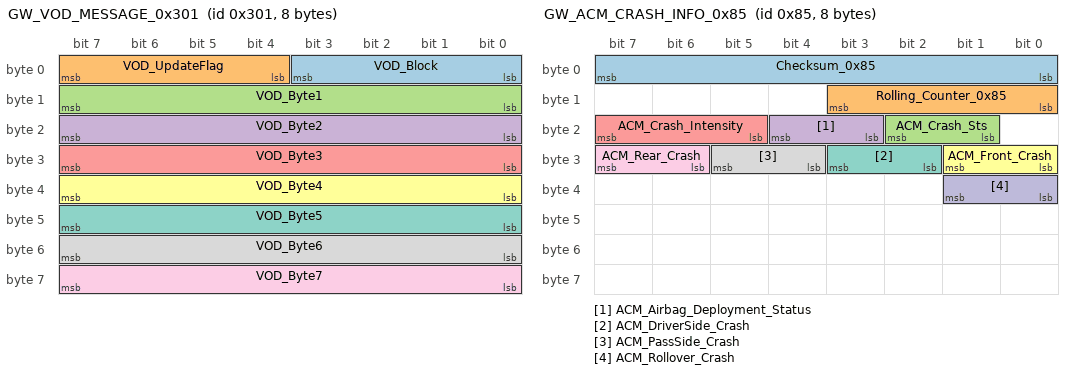
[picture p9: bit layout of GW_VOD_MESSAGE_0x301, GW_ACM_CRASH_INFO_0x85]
BO_ 769 GW_VOD_MESSAGE_0x301: 8 GW
 SG_ VOD_Block : 3|4@0+ (1,0) [0|7] "" VCU
 SG_ VOD_UpdateFlag : 7|4@0+ (1,0) [0|7] "" VCU
 SG_ VOD_Byte1 : 15|8@0+ (1,0) [0|255] "" VCU
 SG_ VOD_Byte2 : 23|8@0+ (1,0) [0|255] "" VCU
 SG_ VOD_Byte3 : 31|8@0+ (1,0) [0|255] "" VCU
 SG_ VOD_Byte4 : 39|8@0+ (1,0) [0|255] "" VCU
 SG_ VOD_Byte5 : 47|8@0+ (1,0) [0|255] "" VCU
 SG_ VOD_Byte6 : 55|8@0+ (1,0) [0|255] "" VCU
 SG_ VOD_Byte7 : 63|8@0+ (1,0) [0|255] "" VCU

BO_ 133 GW_ACM_CRASH_INFO_0x85: 8 GW
 SG_ Checksum_0x85 : 7|8@0+ (1,0) [0|255] "" BMS,EDS_F
 SG_ Rolling_Counter_0x85 : 11|4@0+ (1,0) [0|15] "" BMS,EDS_F
 SG_ ACM_Crash_Sts : 18|2@0+ (1,0) [0|3] "" BMS,EDS_F
 SG_ ACM_Airbag_Deployment_Status : 20|2@0+ (1,0) [0|3] "" Vector__XXX
 SG_ ACM_Crash_Intensity : 23|3@0+ (1,0) [0|7] "" BMS,EDS_F
 SG_ ACM_Front_Crash : 25|2@0+ (1,0) [0|3] "" Vector__XXX
 SG_ ACM_DriverSide_Crash : 27|2@0+ (1,0) [0|3] "" Vector__XXX
 SG_ ACM_PassSide_Crash : 29|2@0+ (1,0) [0|3] "" Vector__XXX
 SG_ ACM_Rear_Crash : 31|2@0+ (1,0) [0|3] "" Vector__XXX
 SG_ ACM_Rollover_Crash : 33|2@0+ (1,0) [0|3] "" Vector__XXX

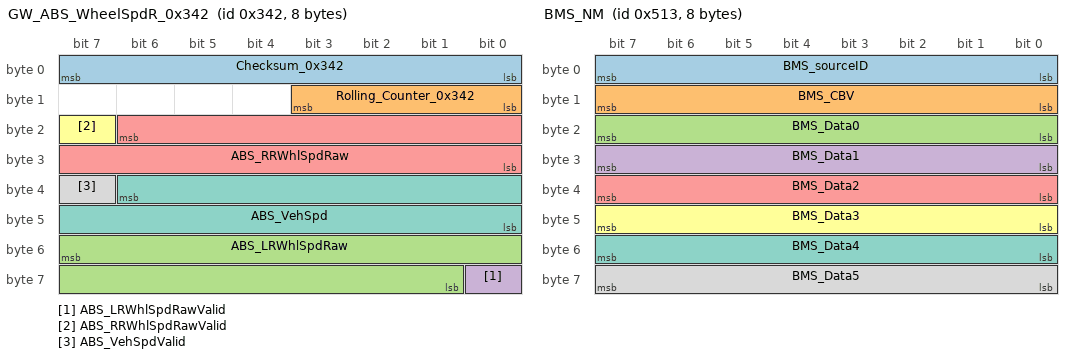
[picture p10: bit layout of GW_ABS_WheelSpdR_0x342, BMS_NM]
BO_ 834 GW_ABS_WheelSpdR_0x342: 8 GW
 SG_ Checksum_0x342 : 7|8@0+ (1,0) [0|255] "" BMS,PDU,EDS_F,EAC,EVCC
 SG_ Rolling_Counter_0x342 : 11|4@0+ (1,0) [0|15] "" BMS,PDU,EDS_F,EAC,EVCC
 SG_ ABS_LRWhlSpdRaw : 55|15@0+ (0.01,0) [0|327.66] "kph" EVCC
 SG_ ABS_LRWhlSpdRawValid : 56|1@0+ (1,0) [0|1] "" EVCC
 SG_ ABS_RRWhlSpdRaw : 22|15@0+ (0.01,0) [0|327.66] "kph" EVCC
 SG_ ABS_RRWhlSpdRawValid : 23|1@0+ (1,0) [0|1] "" EVCC
 SG_ ABS_VehSpd : 38|15@0+ (0.01,0) [0|327.66] "kph" BMS,PDU,EDS_F,EAC,EVCC
 SG_ ABS_VehSpdValid : 39|1@0+ (1,0) [0|1] "" BMS,PDU,EDS_F,EAC,EVCC

BO_ 149 GW_ABS_ASR_0x95: 8 GW
 SG_ Checksum_0x95 : 7|8@0+ (1,0) [0|255] "" EDS_F
 SG_ RollingCounter_0x95 : 11|4@0+ (1,0) [0|14] "" EDS_F
 SG_ ABS_Active : 15|2@0+ (1,0) [0|3] "" EDS_F
 SG_ ASR_Active : 19|2@0+ (1,0) [0|3] "" EDS_F

BO_ 1299 BMS_NM: 8 BMS
 SG_ BMS_sourceID : 7|8@0+ (1,0) [0|255] "" GW,PDU,EDS_F,VCU,EAC,EVCC
 SG_ BMS_CBV : 15|8@0+ (1,0) [0|255] "" GW,PDU,EDS_F,VCU,EAC,EVCC
 SG_ BMS_Data0 : 23|8@0+ (1,0) [0|255] "" GW,PDU,EDS_F,VCU,EAC,EVCC
 SG_ BMS_Data1 : 31|8@0+ (1,0) [0|255] "" GW,PDU,EDS_F,VCU,EAC,EVCC
 SG_ BMS_Data2 : 39|8@0+ (1,0) [0|255] "" GW,PDU,EDS_F,VCU,EAC,EVCC
 SG_ BMS_Data3 : 47|8@0+ (1,0) [0|255] "" GW,PDU,EDS_F,VCU,EAC,EVCC
 SG_ BMS_Data4 : 55|8@0+ (1,0) [0|255] "" GW,PDU,EDS_F,VCU,EAC,EVCC
 SG_ BMS_Data5 : 63|8@0+ (1,0) [0|255] "" GW,PDU,EDS_F,VCU,EAC,EVCC

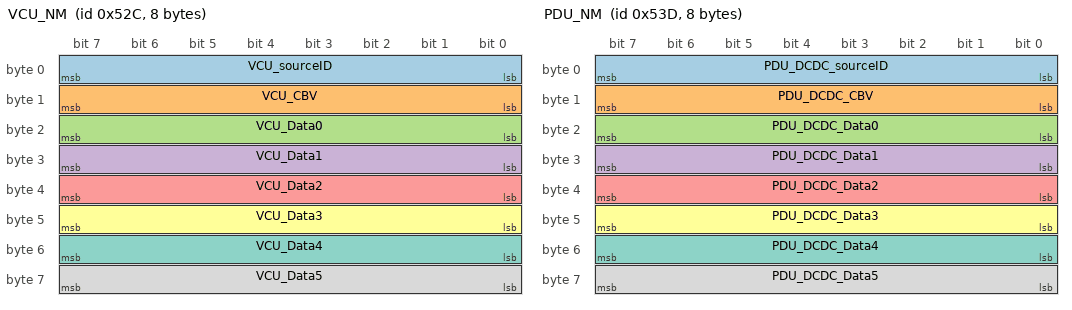
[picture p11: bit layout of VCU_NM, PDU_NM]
BO_ 1324 VCU_NM: 8 VCU
 SG_ VCU_sourceID : 7|8@0+ (1,0) [0|255] "" GW,BMS,PDU,EDS_F,EAC,EVCC
 SG_ VCU_CBV : 15|8@0+ (1,0) [0|255] "" GW,BMS,PDU,EDS_F,EAC,EVCC
 SG_ VCU_Data0 : 23|8@0+ (1,0) [0|255] "" GW,BMS,PDU,EDS_F,EAC,EVCC
 SG_ VCU_Data1 : 31|8@0+ (1,0) [0|255] "" GW,BMS,PDU,EDS_F,EAC,EVCC
 SG_ VCU_Data2 : 39|8@0+ (1,0) [0|255] "" GW,BMS,PDU,EDS_F,EAC,EVCC
 SG_ VCU_Data3 : 47|8@0+ (1,0) [0|255] "" GW,BMS,PDU,EDS_F,EAC,EVCC
 SG_ VCU_Data4 : 55|8@0+ (1,0) [0|255] "" GW,BMS,PDU,EDS_F,EAC,EVCC
 SG_ VCU_Data5 : 63|8@0+ (1,0) [0|255] "" GW,BMS,PDU,EDS_F,EAC,EVCC

BO_ 1341 PDU_NM: 8 PDU
 SG_ PDU_DCDC_sourceID : 7|8@0+ (1,0) [0|255] "" GW,BMS,EDS_F,VCU,EAC,EVCC
 SG_ PDU_DCDC_CBV : 15|8@0+ (1,0) [0|255] "" GW,BMS,EDS_F,VCU,EAC,EVCC
 SG_ PDU_DCDC_Data0 : 23|8@0+ (1,0) [0|255] "" GW,BMS,EDS_F,VCU,EAC,EVCC
 SG_ PDU_DCDC_Data1 : 31|8@0+ (1,0) [0|255] "" GW,BMS,EDS_F,VCU,EAC,EVCC
 SG_ PDU_DCDC_Data2 : 39|8@0+ (1,0) [0|255] "" GW,BMS,EDS_F,VCU,EAC,EVCC
 SG_ PDU_DCDC_Data3 : 47|8@0+ (1,0) [0|255] "" GW,BMS,EDS_F,VCU,EAC,EVCC
 SG_ PDU_DCDC_Data4 : 55|8@0+ (1,0) [0|255] "" GW,BMS,EDS_F,VCU,EAC,EVCC
 SG_ PDU_DCDC_Data5 : 63|8@0+ (1,0) [0|255] "" GW,BMS,EDS_F,VCU,EAC,EVCC

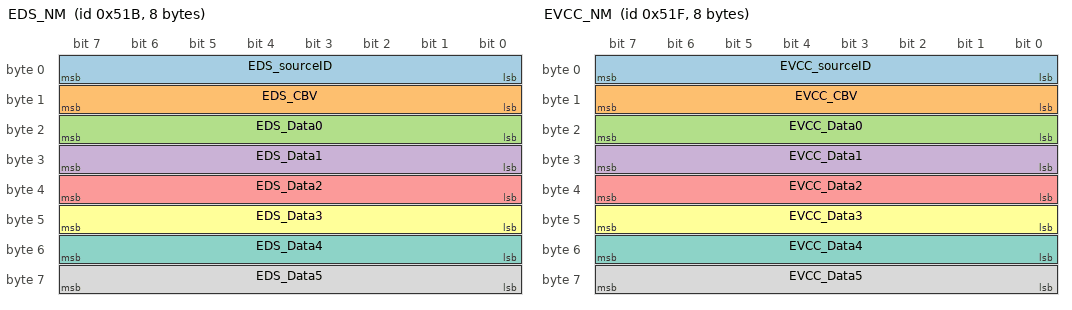
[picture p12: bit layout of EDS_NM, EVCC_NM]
BO_ 1307 EDS_NM: 8 EDS_F
 SG_ EDS_sourceID : 7|8@0+ (1,0) [0|255] "" GW,BMS,PDU,VCU,EAC,EVCC
 SG_ EDS_CBV : 15|8@0+ (1,0) [0|255] "" GW,BMS,PDU,VCU,EAC,EVCC
 SG_ EDS_Data0 : 23|8@0+ (1,0) [0|255] "" GW,BMS,PDU,VCU,EAC,EVCC
 SG_ EDS_Data1 : 31|8@0+ (1,0) [0|255] "" GW,BMS,PDU,VCU,EAC,EVCC
 SG_ EDS_Data2 : 39|8@0+ (1,0) [0|255] "" GW,BMS,PDU,VCU,EAC,EVCC
 SG_ EDS_Data3 : 47|8@0+ (1,0) [0|255] "" GW,BMS,PDU,VCU,EAC,EVCC
 SG_ EDS_Data4 : 55|8@0+ (1,0) [0|255] "" GW,BMS,PDU,VCU,EAC,EVCC
 SG_ EDS_Data5 : 63|8@0+ (1,0) [0|255] "" GW,BMS,PDU,VCU,EAC,EVCC

BO_ 1311 EVCC_NM: 8 EVCC
 SG_ EVCC_sourceID : 7|8@0+ (1,0) [0|255] "" GW,BMS,PDU,EDS_F,VCU,EAC
 SG_ EVCC_CBV : 15|8@0+ (1,0) [0|255] "" GW,BMS,PDU,EDS_F,VCU,EAC
 SG_ EVCC_Data0 : 23|8@0+ (1,0) [0|255] "" GW,BMS,PDU,EDS_F,VCU,EAC
 SG_ EVCC_Data1 : 31|8@0+ (1,0) [0|255] "" GW,BMS,PDU,EDS_F,VCU,EAC
 SG_ EVCC_Data2 : 39|8@0+ (1,0) [0|255] "" GW,BMS,PDU,EDS_F,VCU,EAC
 SG_ EVCC_Data3 : 47|8@0+ (1,0) [0|255] "" GW,BMS,PDU,EDS_F,VCU,EAC
 SG_ EVCC_Data4 : 55|8@0+ (1,0) [0|255] "" GW,BMS,PDU,EDS_F,VCU,EAC
 SG_ EVCC_Data5 : 63|8@0+ (1,0) [0|255] "" GW,BMS,PDU,EDS_F,VCU,EAC

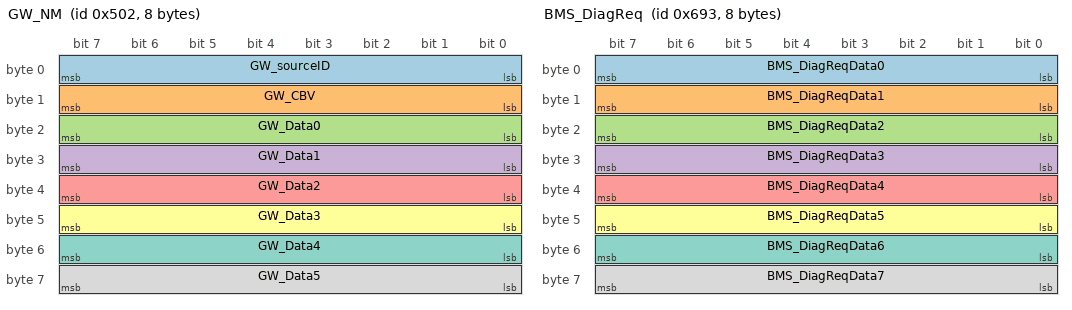
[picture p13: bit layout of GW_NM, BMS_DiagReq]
BO_ 1282 GW_NM: 8 GW
 SG_ GW_sourceID : 7|8@0+ (1,0) [0|255] "" BMS,PDU,EDS_F,VCU,EAC,EVCC
 SG_ GW_CBV : 15|8@0+ (1,0) [0|255] "" BMS,PDU,EDS_F,VCU,EAC,EVCC
 SG_ GW_Data0 : 23|8@0+ (1,0) [0|255] "" BMS,PDU,EDS_F,VCU,EAC,EVCC
 SG_ GW_Data1 : 31|8@0+ (1,0) [0|255] "" BMS,PDU,EDS_F,VCU,EAC,EVCC
 SG_ GW_Data2 : 39|8@0+ (1,0) [0|255] "" BMS,PDU,EDS_F,VCU,EAC,EVCC
 SG_ GW_Data3 : 47|8@0+ (1,0) [0|255] "" BMS,PDU,EDS_F,VCU,EAC,EVCC
 SG_ GW_Data4 : 55|8@0+ (1,0) [0|255] "" BMS,PDU,EDS_F,VCU,EAC,EVCC
 SG_ GW_Data5 : 63|8@0+ (1,0) [0|255] "" BMS,PDU,EDS_F,VCU,EAC,EVCC

BO_ 1683 BMS_DiagReq: 8 GW
 SG_ BMS_DiagReqData0 : 7|8@0+ (1,0) [0|255] "" BMS
 SG_ BMS_DiagReqData1 : 15|8@0+ (1,0) [0|255] "" BMS
 SG_ BMS_DiagReqData2 : 23|8@0+ (1,0) [0|255] "" BMS
 SG_ BMS_DiagReqData3 : 31|8@0+ (1,0) [0|255] "" BMS
 SG_ BMS_DiagReqData4 : 39|8@0+ (1,0) [0|255] "" BMS
 SG_ BMS_DiagReqData5 : 47|8@0+ (1,0) [0|255] "" BMS
 SG_ BMS_DiagReqData6 : 55|8@0+ (1,0) [0|255] "" BMS
 SG_ BMS_DiagReqData7 : 63|8@0+ (1,0) [0|255] "" BMS

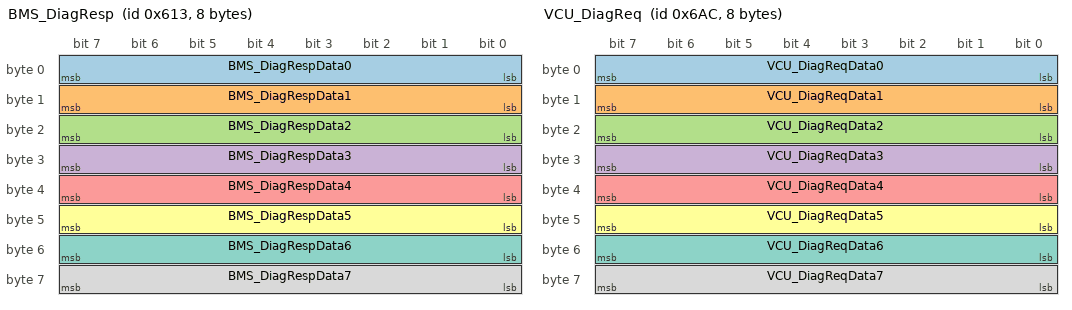
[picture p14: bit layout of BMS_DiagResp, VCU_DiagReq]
BO_ 1555 BMS_DiagResp: 8 BMS
 SG_ BMS_DiagRespData0 : 7|8@0+ (1,0) [0|255] "" GW
 SG_ BMS_DiagRespData1 : 15|8@0+ (1,0) [0|255] "" GW
 SG_ BMS_DiagRespData2 : 23|8@0+ (1,0) [0|255] "" GW
 SG_ BMS_DiagRespData3 : 31|8@0+ (1,0) [0|255] "" GW
 SG_ BMS_DiagRespData4 : 39|8@0+ (1,0) [0|255] "" GW
 SG_ BMS_DiagRespData5 : 47|8@0+ (1,0) [0|255] "" GW
 SG_ BMS_DiagRespData6 : 55|8@0+ (1,0) [0|255] "" GW
 SG_ BMS_DiagRespData7 : 63|8@0+ (1,0) [0|255] "" GW

BO_ 1708 VCU_DiagReq: 8 GW
 SG_ VCU_DiagReqData0 : 7|8@0+ (1,0) [0|255] "" VCU
 SG_ VCU_DiagReqData1 : 15|8@0+ (1,0) [0|255] "" VCU
 SG_ VCU_DiagReqData2 : 23|8@0+ (1,0) [0|255] "" VCU
 SG_ VCU_DiagReqData3 : 31|8@0+ (1,0) [0|255] "" VCU
 SG_ VCU_DiagReqData4 : 39|8@0+ (1,0) [0|255] "" VCU
 SG_ VCU_DiagReqData5 : 47|8@0+ (1,0) [0|255] "" VCU
 SG_ VCU_DiagReqData6 : 55|8@0+ (1,0) [0|255] "" VCU
 SG_ VCU_DiagReqData7 : 63|8@0+ (1,0) [0|255] "" VCU

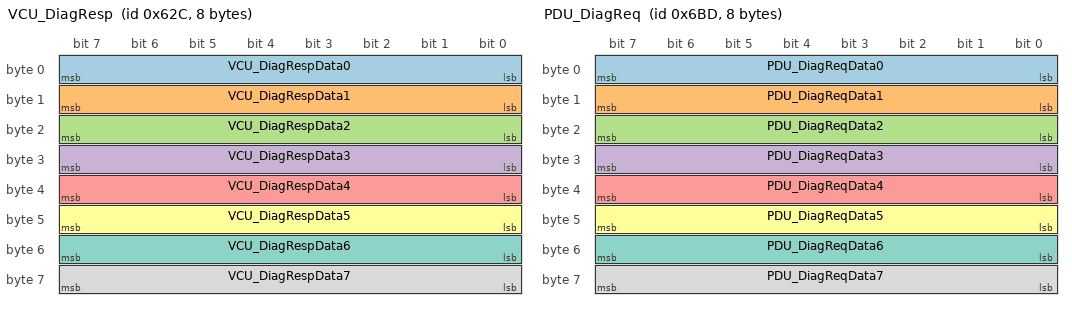
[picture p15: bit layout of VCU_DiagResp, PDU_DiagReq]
BO_ 1580 VCU_DiagResp: 8 VCU
 SG_ VCU_DiagRespData0 : 7|8@0+ (1,0) [0|255] "" GW
 SG_ VCU_DiagRespData1 : 15|8@0+ (1,0) [0|255] "" GW
 SG_ VCU_DiagRespData2 : 23|8@0+ (1,0) [0|255] "" GW
 SG_ VCU_DiagRespData3 : 31|8@0+ (1,0) [0|255] "" GW
 SG_ VCU_DiagRespData4 : 39|8@0+ (1,0) [0|255] "" GW
 SG_ VCU_DiagRespData5 : 47|8@0+ (1,0) [0|255] "" GW
 SG_ VCU_DiagRespData6 : 55|8@0+ (1,0) [0|255] "" GW
 SG_ VCU_DiagRespData7 : 63|8@0+ (1,0) [0|255] "" GW

BO_ 1725 PDU_DiagReq: 8 GW
 SG_ PDU_DiagReqData0 : 7|8@0+ (1,0) [0|255] "" PDU
 SG_ PDU_DiagReqData1 : 15|8@0+ (1,0) [0|255] "" PDU
 SG_ PDU_DiagReqData2 : 23|8@0+ (1,0) [0|255] "" PDU
 SG_ PDU_DiagReqData3 : 31|8@0+ (1,0) [0|255] "" PDU
 SG_ PDU_DiagReqData4 : 39|8@0+ (1,0) [0|255] "" PDU
 SG_ PDU_DiagReqData5 : 47|8@0+ (1,0) [0|255] "" PDU
 SG_ PDU_DiagReqData6 : 55|8@0+ (1,0) [0|255] "" PDU
 SG_ PDU_DiagReqData7 : 63|8@0+ (1,0) [0|255] "" PDU

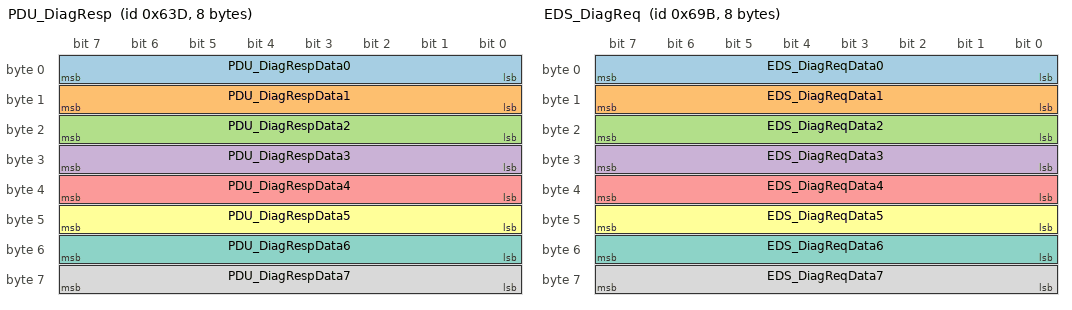
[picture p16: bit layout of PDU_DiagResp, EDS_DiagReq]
BO_ 1597 PDU_DiagResp: 8 PDU
 SG_ PDU_DiagRespData0 : 7|8@0+ (1,0) [0|255] "" GW
 SG_ PDU_DiagRespData1 : 15|8@0+ (1,0) [0|255] "" GW
 SG_ PDU_DiagRespData2 : 23|8@0+ (1,0) [0|255] "" GW
 SG_ PDU_DiagRespData3 : 31|8@0+ (1,0) [0|255] "" GW
 SG_ PDU_DiagRespData4 : 39|8@0+ (1,0) [0|255] "" GW
 SG_ PDU_DiagRespData5 : 47|8@0+ (1,0) [0|255] "" GW
 SG_ PDU_DiagRespData6 : 55|8@0+ (1,0) [0|255] "" GW
 SG_ PDU_DiagRespData7 : 63|8@0+ (1,0) [0|255] "" GW

BO_ 1691 EDS_DiagReq: 8 GW
 SG_ EDS_DiagReqData0 : 7|8@0+ (1,0) [0|255] "" EDS_F
 SG_ EDS_DiagReqData1 : 15|8@0+ (1,0) [0|255] "" EDS_F
 SG_ EDS_DiagReqData2 : 23|8@0+ (1,0) [0|255] "" EDS_F
 SG_ EDS_DiagReqData3 : 31|8@0+ (1,0) [0|255] "" EDS_F
 SG_ EDS_DiagReqData4 : 39|8@0+ (1,0) [0|255] "" EDS_F
 SG_ EDS_DiagReqData5 : 47|8@0+ (1,0) [0|255] "" EDS_F
 SG_ EDS_DiagReqData6 : 55|8@0+ (1,0) [0|255] "" EDS_F
 SG_ EDS_DiagReqData7 : 63|8@0+ (1,0) [0|255] "" EDS_F

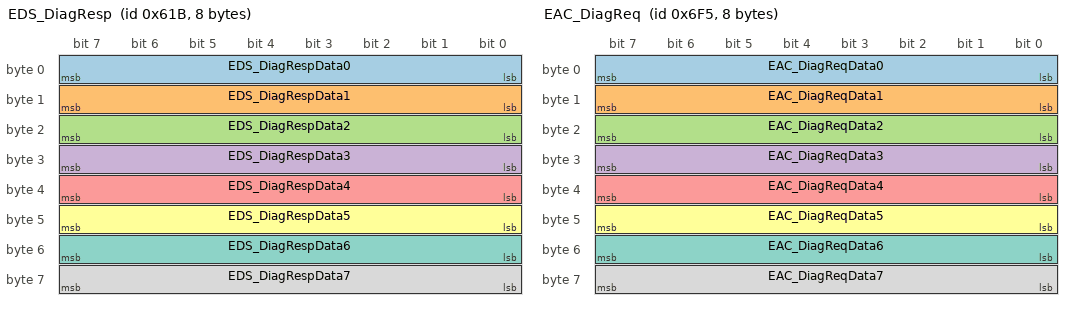
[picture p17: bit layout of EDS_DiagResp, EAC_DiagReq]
BO_ 1563 EDS_DiagResp: 8 EDS_F
 SG_ EDS_DiagRespData0 : 7|8@0+ (1,0) [0|255] "" GW
 SG_ EDS_DiagRespData1 : 15|8@0+ (1,0) [0|255] "" GW
 SG_ EDS_DiagRespData2 : 23|8@0+ (1,0) [0|255] "" GW
 SG_ EDS_DiagRespData3 : 31|8@0+ (1,0) [0|255] "" GW
 SG_ EDS_DiagRespData4 : 39|8@0+ (1,0) [0|255] "" GW
 SG_ EDS_DiagRespData5 : 47|8@0+ (1,0) [0|255] "" GW
 SG_ EDS_DiagRespData6 : 55|8@0+ (1,0) [0|255] "" GW
 SG_ EDS_DiagRespData7 : 63|8@0+ (1,0) [0|255] "" GW

BO_ 1781 EAC_DiagReq: 8 GW
 SG_ EAC_DiagReqData0 : 7|8@0+ (1,0) [0|255] "" EAC
 SG_ EAC_DiagReqData1 : 15|8@0+ (1,0) [0|255] "" EAC
 SG_ EAC_DiagReqData2 : 23|8@0+ (1,0) [0|255] "" EAC
 SG_ EAC_DiagReqData3 : 31|8@0+ (1,0) [0|255] "" EAC
 SG_ EAC_DiagReqData4 : 39|8@0+ (1,0) [0|255] "" EAC
 SG_ EAC_DiagReqData5 : 47|8@0+ (1,0) [0|255] "" EAC
 SG_ EAC_DiagReqData6 : 55|8@0+ (1,0) [0|255] "" EAC
 SG_ EAC_DiagReqData7 : 63|8@0+ (1,0) [0|255] "" EAC

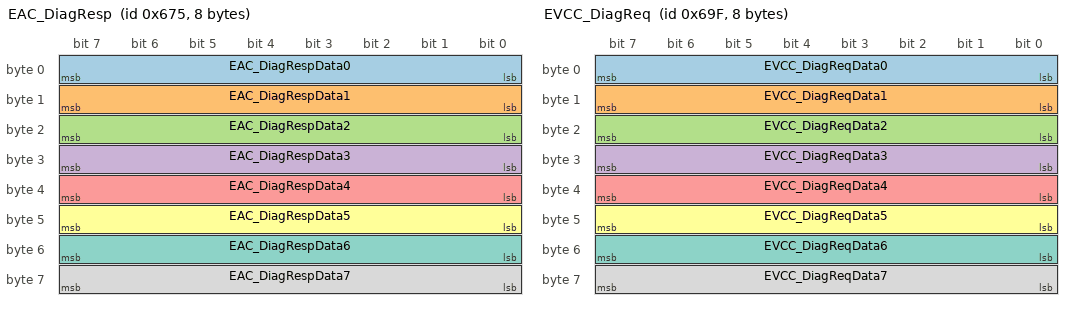
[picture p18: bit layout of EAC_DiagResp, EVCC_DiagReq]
BO_ 1653 EAC_DiagResp: 8 EAC
 SG_ EAC_DiagRespData0 : 7|8@0+ (1,0) [0|255] "" GW
 SG_ EAC_DiagRespData1 : 15|8@0+ (1,0) [0|255] "" GW
 SG_ EAC_DiagRespData2 : 23|8@0+ (1,0) [0|255] "" GW
 SG_ EAC_DiagRespData3 : 31|8@0+ (1,0) [0|255] "" GW
 SG_ EAC_DiagRespData4 : 39|8@0+ (1,0) [0|255] "" GW
 SG_ EAC_DiagRespData5 : 47|8@0+ (1,0) [0|255] "" GW
 SG_ EAC_DiagRespData6 : 55|8@0+ (1,0) [0|255] "" GW
 SG_ EAC_DiagRespData7 : 63|8@0+ (1,0) [0|255] "" GW

BO_ 1695 EVCC_DiagReq: 8 GW
 SG_ EVCC_DiagReqData0 : 7|8@0+ (1,0) [0|255] "" EVCC
 SG_ EVCC_DiagReqData1 : 15|8@0+ (1,0) [0|255] "" EVCC
 SG_ EVCC_DiagReqData2 : 23|8@0+ (1,0) [0|255] "" EVCC
 SG_ EVCC_DiagReqData3 : 31|8@0+ (1,0) [0|255] "" EVCC
 SG_ EVCC_DiagReqData4 : 39|8@0+ (1,0) [0|255] "" EVCC
 SG_ EVCC_DiagReqData5 : 47|8@0+ (1,0) [0|255] "" EVCC
 SG_ EVCC_DiagReqData6 : 55|8@0+ (1,0) [0|255] "" EVCC
 SG_ EVCC_DiagReqData7 : 63|8@0+ (1,0) [0|255] "" EVCC

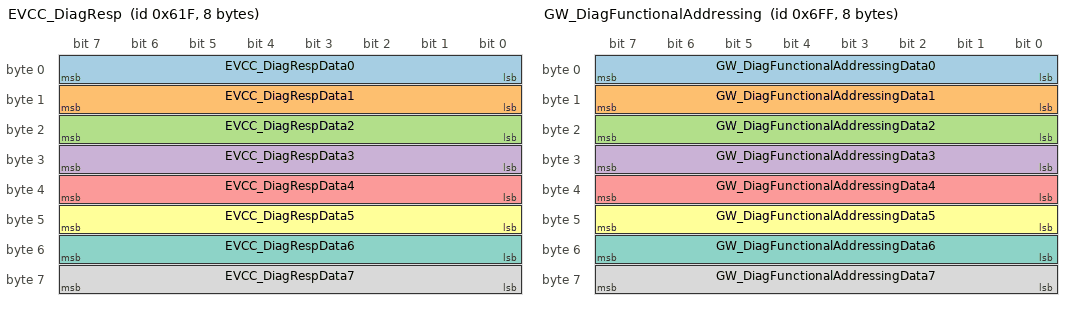
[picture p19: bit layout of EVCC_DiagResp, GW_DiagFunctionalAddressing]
BO_ 1567 EVCC_DiagResp: 8 EVCC
 SG_ EVCC_DiagRespData0 : 7|8@0+ (1,0) [0|255] "" GW
 SG_ EVCC_DiagRespData1 : 15|8@0+ (1,0) [0|255] "" GW
 SG_ EVCC_DiagRespData2 : 23|8@0+ (1,0) [0|255] "" GW
 SG_ EVCC_DiagRespData3 : 31|8@0+ (1,0) [0|255] "" GW
 SG_ EVCC_DiagRespData4 : 39|8@0+ (1,0) [0|255] "" GW
 SG_ EVCC_DiagRespData5 : 47|8@0+ (1,0) [0|255] "" GW
 SG_ EVCC_DiagRespData6 : 55|8@0+ (1,0) [0|255] "" GW
 SG_ EVCC_DiagRespData7 : 63|8@0+ (1,0) [0|255] "" GW

BO_ 1791 GW_DiagFunctionalAddressing: 8 GW
 SG_ GW_DiagFunctionalAddressingData0 : 7|8@0+ (1,0) [0|255] "" BMS,PDU,EDS_F,VCU,EAC,EVCC
 SG_ GW_DiagFunctionalAddressingData1 : 15|8@0+ (1,0) [0|255] "" BMS,PDU,EDS_F,VCU,EAC,EVCC
 SG_ GW_DiagFunctionalAddressingData2 : 23|8@0+ (1,0) [0|255] "" BMS,PDU,EDS_F,VCU,EAC,EVCC
 SG_ GW_DiagFunctionalAddressingData3 : 31|8@0+ (1,0) [0|255] "" BMS,PDU,EDS_F,VCU,EAC,EVCC
 SG_ GW_DiagFunctionalAddressingData4 : 39|8@0+ (1,0) [0|255] "" BMS,PDU,EDS_F,VCU,EAC,EVCC
 SG_ GW_DiagFunctionalAddressingData5 : 47|8@0+ (1,0) [0|255] "" BMS,PDU,EDS_F,VCU,EAC,EVCC
 SG_ GW_DiagFunctionalAddressingData6 : 55|8@0+ (1,0) [0|255] "" BMS,PDU,EDS_F,VCU,EAC,EVCC
 SG_ GW_DiagFunctionalAddressingData7 : 63|8@0+ (1,0) [0|255] "" BMS,PDU,EDS_F,VCU,EAC,EVCC

CM_ SG_ 504 Checksum_0x1F8 "Check sum";
CM_ SG_ 504 Rolling_Counter_0x1F8 "Rolling counter";
CM_ SG_ 504 EDS_output_trq_FR "Actual output torque of current EDS";
CM_ SG_ 504 EDS_output_trqValid_FR "Indicate the valid flag of current motor torque";
CM_ SG_ 504 EDS_Spd_FR "current motor speed";
CM_ SG_ 504 EDS_SpdValid_FR "Indicate the valid flag of current motor speed";
CM_ SG_ 504 EDS_MotorDriveSts_FR "The drive state of EDS";
CM_ SG_ 504 EDS_Work_STS_FR "EDS Work status";
CM_ SG_ 504 EDS_powoff_req_FR "If there is a serious failure in the running process of EDS, the high voltage of VCU will be requested";
CM_ SG_ 680 Checksum_0x2A8 "Checksum";
CM_ SG_ 680 Rolling_Counter_0x2A8 "Rolling counter";
CM_ SG_ 680 EDS_MotorSerialNum_FWD "FrontMotorSerialNumber";
CM_ SG_ 680 EDS_MinTrq_FWD "AllowMinTorque(long time min torque available)";
CM_ SG_ 680 EDS_MaxTrq_FWD "AllowMaxTorque(long time max torque available)";
CM_ SG_ 568 EDS_MotTemp_MEAS_EDS_FWD "Motor Temperature";
CM_ SG_ 568 EDS_MotTemp_MEAS_EDS_valid_FWD "Indicate the valid flag of MotorTemperature";
CM_ SG_ 568 EDS_temp_FWD "EDS current temperature";
CM_ SG_ 568 EDS_tempValid_FWD "Indicate the valid flag of EDS current temperature";
CM_ SG_ 568 EDS_disxhg_st_FWD "State of active discharge of EDS";
CM_ SG_ 568 EDS_IGBTState_FWD "FWD EDS IGBT State";
CM_ SG_ 568 EDS_DampingState_FWD "FWD EDS Damping state";
CM_ SG_ 568 EDS_CoolFlowrate_DMD_FWD "Coolant Florate demand from FWD EDS";
CM_ SG_ 1080 EDS_FailNum_ERR_FWD "FaultNumber";
CM_ SG_ 1080 EDS_FailGrade_ERR_FWD "Fault level of EDS system";
CM_ SG_ 1080 EDS_MotOverTempAlarm_FWD "Motor over temperture alarm";
CM_ SG_ 1080 EDS_MotOverTempFault_FWD "Motor over temperture fault";
CM_ SG_ 1080 EDS_MotTempSenFault_FWD "Motor temperature sensor fault";
CM_ SG_ 1080 EDS_EDSOverTempUFault_FWD "EDS Upha Over temperature fault";
CM_ SG_ 1080 EDS_EDSOverTempVFault_FWD "EDS Vpha Over temperature fault";
CM_ SG_ 1080 EDS_EDSOverTempWFault_FWD "EDS Wpha Over temperature fault";
CM_ SG_ 1080 EDS_EDSOverTempAlarm_FWD "EDS over temperture alarm";
CM_ SG_ 1080 EDS_TCoolantOvHi_FWD "Alarm  when Cooling water temperature is too high";
CM_ SG_ 1080 EDS_EDSTempCmpAlarm_FWD "EDS temp offset checkout alarm";
CM_ SG_ 1080 EDS_EDSPhaOvCurentHWFault_FWD "Phase Current Overcurrent hardware fault";
CM_ SG_ 1080 EDS_EDSphaOffCalFault_FWD "EDS phase Current Offset Calibration Fault";
CM_ SG_ 1080 EDS_EDSOverIdcLnkAlarm_FWD "EDS IdcLnk Overcurrent alarm";
CM_ SG_ 1080 EDS_EDSHVOverVoltageAlarm_FWD "EDS high voltage over voltage alarm";
CM_ SG_ 1080 EDS_EDSHVOverVoltageFault_FWD "EDS high voltage over voltage fault";
CM_ SG_ 1080 EDS_EDSHVUnderVoltageAlarm_FWD "EDS high voltage under voltage alarm";
CM_ SG_ 1080 EDS_EDSHVUnderVoltageFault_FWD "EDS high voltage under voltage fault";
CM_ SG_ 1080 EDS_RunToDischaErr_FWD "Stateflow fail to enter avtive discharge";
CM_ SG_ 1080 EDS_12VOverVoltageAlarm_FWD "12V Power over voltage alarm";
CM_ SG_ 1080 EDS_12VUnderVoltageAlarm_FWD "12V Power under voltage alarm";
CM_ SG_ 1080 EDS_MotOverAlarm_FWD "Motor overspeed fault alarm";
CM_ SG_ 1080 EDS_MotOverFault_FWD "Motor overspeed fault fault";
CM_ SG_ 1080 EDS_iDcLnkOvCLimFail_FWD "Bus current over-current fault";
CM_ SG_ 1080 EDS_MotBlockedFault_FWD "Motor blocked fault";
CM_ SG_ 1080 EDS_RSLErr_FWD "Rotary transformer signal fault";
CM_ SG_ 1080 EDS_MotTrqLimFault_FWD "Motor torque limit fault";
CM_ SG_ 1080 EDS_ResolverOffsetAngle_FWD "EDS offset angle check fault";
CM_ SG_ 1080 EDS_EDSDisChgFault_FWD "EDS Active discharge fault";
CM_ SG_ 1080 EDS_IGBTFault_FWD "IGBT fault";
CM_ SG_ 1080 EDS_CANBusoffFault_FWD "CAN busoff fault";
CM_ SG_ 1080 EDS_TDrvBoardOvHiWarn_FWD "Alarm when drive plate temperature is too high";
CM_ SG_ 1080 EDS_TIGBTOvHiFault_FWD "IGBT junction temperature over temperature fault";
CM_ SG_ 1080 EDS_TIGBTOvHiWarn_FWD "IGBT junction temperature over temperature alarm";
CM_ SG_ 1080 EDS_IOHWABSampFail_FWD "Chip control power sampling failure";
CM_ SG_ 1080 EDS_EDSOpenFault_FWD "EDS open plate fault";
CM_ SG_ 1080 EDS_MotorOpenFault_FWD "Motor open plate fault";
CM_ SG_ 1080 EDS_EmacBlkdWarn_FWD "Motor locked rotor warning";
CM_ SG_ 1080 EDS_VerMatchFailureErr_FWD "EDS Software Version match Failure Fault";
CM_ SG_ 1080 EDS_DiashCirNoPsblErr_FWD "Unable to active short circuit fault";
CM_ SG_ 1080 EDS_OperOutdRngErr_FWD "Short circuit over temperature operation diagnosis";
CM_ SG_ 1080 EDS_PhaseLossFaultErr_FWD "Missing phase fault";
CM_ SG_ 1080 EDS_CPLDFault_FWD "CPLD Fault";
CM_ SG_ 1080 EDS_CPLDFaultBaseSpd_FWD "CPLD enter ASC fault based on motor speed";
CM_ SG_ 1080 EDS_IOHWABNen33Fail_FWD "Feedback NEN33 fault";
CM_ SG_ 1080 EDS_HvMcuSlightFault_RWD "HvMcu Slight fault";
CM_ SG_ 1080 EDS_HvMcuSevFault_FWD "HvMcu serious fault";
CM_ SG_ 1080 EDS_EDSPhaSampHWFault_FWD "UVW phase current monitoring sampling hard wire fault";
CM_ SG_ 1080 EDS_IsOvHiErr_FWD "Phase current overcurrent diagnosis";
CM_ SG_ 1080 EDS_CanRollingCounterErr_FWD "Receive count error";
CM_ SG_ 1080 EDS_CanTimeoutErr_FWD "Receive timeout error";
CM_ SG_ 1080 EDS_CrashFault_FWD "Crash signal fault";
CM_ SG_ 537 Checksum_0x219 "Checksum";
CM_ SG_ 537 Rolling_Counter_0x219 "Rolling Counter";
CM_ SG_ 537 VCU_VehicleDischargePower "Discharge Power";
CM_ SG_ 537 VCU_VehicleChargePower "Charge Power";
CM_ SG_ 537 VCU_ChargeAllow "The flag of VCU allows BMS charging";
CM_ SG_ 544 Checksum_0x220 "Checksum";
CM_ SG_ 544 Rolling_Counter_0x220 "Rolling Counter";
CM_ SG_ 544 VCU_BMS_PTCOnOff_Sts "VCU sends the status of the PTC Heater(for C-Car)";
CM_ SG_ 544 VCU_BMS_ValveOnOff_Sts "VCU sends the status of the valve";
CM_ SG_ 544 VCU_BMS_PumpFB "VCU sends the PUMP feedback";
CM_ SG_ 757 VCU_Charge_Control "Charging allow or forbid";
CM_ SG_ 757 VCU_AC_chargeSock_temp1 "AC Charge SOCK temp";
CM_ SG_ 757 VCU_DC_chargeSock_temp1 "DC charge SOCK temp1";
CM_ SG_ 757 VCU_DC_chargeSock_temp2 "DC charge SOCK temp2";
CM_ SG_ 725 VCU_DCDC_Output_REQ "Control DCDC Output AbleEnable";
CM_ SG_ 725 VCU_DCDC_OutVoltage_REQ "DCDC OutputVoltage";
CM_ SG_ 725 VCU_DCDCAllowedPower "DCDCAllowedPower";
CM_ SG_ 553 Checksum_0x229 "Checksum";
CM_ SG_ 553 Rolling_Counter_0x229 "Rolling counter";
CM_ SG_ 553 VCU_EDS_TargetTqMin_FWD "Min Target torque";
CM_ SG_ 553 VCU_EDS_StsModeReq_FWD "MCU Status Request";
CM_ SG_ 553 VCU_EDS_demtrq_FWD "Driving Requirements Torque from VCU to EDS";
CM_ SG_ 553 VCU_EDS_demtrqValid_FWD "Driving Requirements Torque from VCU to EDS";
CM_ SG_ 553 VCU_EDS_TargetTqMax_FWD "Max Target torque";
CM_ SG_ 553 VCU_EDS_CreepFlg_FWD "Enable  or Disable  Front-Wheel Drive Creep Function";
CM_ SG_ 553 VCU_EDS_HILLHoldFlg_FWD "Enable  or Disable  Front-Wheel Drive HILL Hold Calibration";
CM_ SG_ 937 VCU_PTC_RelaySts "PTC Relayopen or close state";
CM_ SG_ 937 VCU_EACEnbReq "The command of compressor,AC enable signal";
CM_ SG_ 937 VCU_EACAllowedPower "EAC Allowed Power";
CM_ SG_ 937 VCU_EAC_CompSpdReq "Compressor Speed Request";
CM_ SG_ 937 VCU_DriveCoolWaterFlowRate "Actual drive cool water flow rate";
CM_ SG_ 937 VCU_DriveCoolInletWaterTemp "The temperature of inlet radiator";
CM_ SG_ 425 VCU_RegenLevel_Feed "VCU current Feedback Set power regenerative level";
CM_ SG_ 425 VCU_RBCSts "Regenerative Braking";
CM_ SG_ 425 VCU_RDCSts "Regenerative coasted";
CM_ SG_ 425 VCU_Veh_ERR "Vehicle System Error";
CM_ SG_ 425 VCU_DrvSys_ERR "DriveSystemError";
CM_ SG_ 425 VCU_PackSys_ERR "StoredEnergySystemError";
CM_ SG_ 425 VCU_TBOX_Veh_STS_Reserved "Vehicle Status";
CM_ SG_ 425 VCU_VehChg_STS "Vehicle Charge Status";
CM_ SG_ 425 VCU_BatterVoltage_Reserved "BetteryVoltage";
CM_ SG_ 425 VCU_BatteryVoltErr_Reserved "Indicate the generator is warning when Mechanical flag or Electrical flag is active (Reserved)（）";
CM_ SG_ 425 VCU_MotorCoolingCircuitErr_Reserved "Motor cooling loop failure state (Reserved)";
CM_ SG_ 425 VCU_PackCoolingCircuitErr_Reserved "Battery pack cooling loop failure state (Reserved)";
CM_ SG_ 425 VCU_VehicleHVStatus "Vehicle High voltage Ready State(VCU_VehicleHVStatus to be received by all modules,Used as a flash programming pre-condition (replacement for engine running)";
CM_ SG_ 425 VCU_InstantPowerConsump "Instant power consumption";
CM_ SG_ 425 VCU_AveragePowerConsump "Average power comsumption";
CM_ SG_ 425 VCU_BrakePedalSts "Brake Pedal Sts";
CM_ SG_ 441 VCU_MCUConsumepower "MCU Consume power";
CM_ SG_ 441 VCU_EACConsumepower "EAC Consume power";
CM_ SG_ 441 VCU_DCDCConsumepower "DCDC Consume power";
CM_ SG_ 441 VCU_PTCConsumepower "PTC Consume power";
CM_ SG_ 992 Checksum_0x3E0 "Checksum";
CM_ SG_ 992 Rolling_Counter_0x3E0 "Rolling counter";
CM_ SG_ 992 VCU_RunningRange "Estimated running range ( at present )";
CM_ SG_ 992 VCU_MHU_Ack_ChgSche_stt "Status Enabled/ Disabled of Schedule Charging acknowledged by VCU base on request from MHU 0x403 MHU_ChargeScheduleSet.When this signal value = Enabled, VCU to follow 0x403 MHU_ChargingRequest = Start / Stop to start/ stop charging or stop charging when reach target SOC / battery full / chag.error.";
CM_ SG_ 992 VCU_MHU_GuestMode_sts "Feedback from VCU of Guest Mode ON/ OFF.Refer to Guest Mode definition document for more detail.";
CM_ SG_ 992 VCU_MHU_Ack_TargetSOC "Target SOC acknowledged by VCU base on request from MHU";
CM_ SG_ 992 VCU_ValetMode_sts "Status indicate valet mode is effected to VCU";
CM_ SG_ 992 VCU_ValetMode_MaxSpeedSts "Max speed setting of Valet mode";
CM_ SG_ 992 VCU_CreepDisable_stt "Feedback for Creep disable request";
CM_ SG_ 409 Checksum_0x199 "Checksum";
CM_ SG_ 409 Rolling_Counter_0x199 "Rolling Counter";
CM_ SG_ 409 VCU_VehFailGrade_ERR "VehicleFaultLevel";
CM_ SG_ 409 VCU_BMS_HVOnOff_REQ "BMS decides whether to close or disconnect the primary and negative relays by judging this command";
CM_ SG_ 409 VCU_Vehicle_Mode "Vehicle Mode of EV";
CM_ SG_ 889 VCU_DriveCoolWaterPumpSts "Motor electronic pump state";
CM_ SG_ 889 VCU_DriveCoolWaterDuty "Motor electronic pump occupancy";
CM_ SG_ 889 VCU_BatteryWaterPumpSts_reserved "Battery electronic pump state";
CM_ SG_ 889 VCU_BatteryWaterPumpDuty_reserved "Battery electronic pump occupancy";
CM_ SG_ 889 VCU_DriveMode "Vehicle drive mode";
CM_ SG_ 889 VCU_ActualGear "actual gear,Provide gear shift signal";
CM_ SG_ 889 VCU_ACTGearValid "Indicate the current gear position";
CM_ SG_ 889 VCU_AccPedal1OutRange "The state of accelerator pedal1";
CM_ SG_ 889 VCU_AccPedal2OutRange "The state of accelerator pedal2";
CM_ SG_ 889 VCU_BrkPedal1OutRange "The synchronization state of brake pedal1";
CM_ SG_ 889 VCU_BrkPedal2OutRange "The state of barke pedal2";
CM_ SG_ 889 VCU_BrkPedalPct "The percent of brake pedal";
CM_ SG_ 889 VCU_AccPedalPosition "Indicate the acceleraton pedal position";
CM_ SG_ 889 VCU_AccPedalPositionValid "Indicate the acceleration pedal position valid flag";
CM_ SG_ 889 VCU_SocDisplay_EST "Battery SOC";
CM_ SG_ 889 VCU_PowerLimit "Vehicle power limit";
CM_ SG_ 889 VCU_CruiseCtrlSts "Cruise state";
CM_ SG_ 889 VCU_LowSOC_ERR "Battery SOC low";
CM_ SG_ 905 VCU_FanControl_Sts "Fan Control status";
CM_ SG_ 905 VCU_HVACInletWateTemp "HVAC inlet water temperature";
CM_ SG_ 905 VCU_IMMO_Sts "IMMO staus";
CM_ SG_ 905 VCU_VacuumSts_reserved "Vacuum Pressure status";
CM_ SG_ 905 VCU_VacuumPresWrn "Vacuum Pressure warning";
CM_ SG_ 273 VCU_Sts "VCU status";
CM_ SG_ 1145 VCU_OtherFaultNum_Reserved "Other Fault Number (Reserved)";
CM_ SG_ 1145 VCU_EDSCAN_ERR "EDS CAN Communication Error(lost EDS node)";
CM_ SG_ 1145 VCU_BmsCAN_ERR "BMS CAN Communication(LossBMSNote)";
CM_ SG_ 1145 VCU_DcdcCAN_ERR "DCDC communication failure(lost DCDC node)";
CM_ SG_ 1145 VCU_AbsCAN_ERR "ABS communication failure(lost ABS node)";
CM_ SG_ 1145 VCU_AcmCAN_ERR "ACM communication failure(lost ACM node)";
CM_ SG_ 1145 VCU_XgwCAN_ERR "SCU communication failure(loss of SCU node)  (Reserved)";
CM_ SG_ 1145 VCU_ObcCAN_ERR "Charging communication failure alarm  0 normal  (Reserved)";
CM_ SG_ 1145 VCU_BcmCAN_ERR_reserved "BCM communication failure(lost BCM node)";
CM_ SG_ 1145 VCU_WaterPump_ERR "Water pump failure";
CM_ SG_ 1145 VCU_BrakeSys_Err "Brake system failure (Reserved)";
CM_ SG_ 1145 VCU_PreChgFail_ERR_Reserved "Pre-charge failure";
CM_ SG_ 1145 VCU_LowBattery_ERR "12V battery failure  (Reserved)";
CM_ SG_ 1145 VCU_AccPed_ERR "Throttle pedal malfunction";
CM_ SG_ 1145 VCU_BrkPed_ERR "Brake pedal failure";
CM_ SG_ 1145 VCU_EPSCAN_ERR "EPS Module Failure";
CM_ SG_ 1145 VCU_PtcModu_ERR_Reserved "PTC module failure";
CM_ SG_ 1145 VCU_Shift_ERR "SCU file signal failure";
CM_ SG_ 1145 VCU_FlgHVIL_ERR "High pressure interlock failure (Reserved)";
CM_ SG_ 1145 VCU_EKSCAN_ERR "EKS communication failure(lost EKS node)";
CM_ SG_ 1145 VCU_VehLvInit_ERR_Reserved "Low voltage system self-inspection failure (Reserved)";
CM_ SG_ 1145 VCU_EacCAN_ERR "EAC Module failure";
CM_ SG_ 1145 VCU_EAC_CompFltStat_ERR "EAC Compressor Fault Status failure";
CM_ SG_ 745 Checksum_0x2E9 "Checksum";
CM_ SG_ 745 Rolling_Counter_0x2E9 "Rolling counter";
CM_ SG_ 745 VCU_RemainingMileage "The remaining mileage";
CM_ SG_ 745 VCU_SetCruiseSpd "Set Cruise Speed";
CM_ SG_ 792 EAC_CompElecCurrV "Compressor Electrical Current Validity";
CM_ SG_ 792 EAC_CompStat "Compressor status";
CM_ SG_ 792 EAC_CompElecPwrV "Compressor Electrical Power Validity";
CM_ SG_ 792 EAC_CompSpdIncrReq "Compressor Speed Increasing Request";
CM_ SG_ 792 EAC_CompSpdV "Compressor Actual Speed Validity";
CM_ SG_ 792 EAC_CompElecPwr "Compressor Electrical Power";
CM_ SG_ 792 EAC_CompSpd "Compressor Actual Speed";
CM_ SG_ 792 EAC_CompElecCurr "Compressor Electrical Current";
CM_ SG_ 792 EAC_CompFltStat "Compressor Fault Status";
CM_ SG_ 793 EAC_CompPhaseCurr "Compressor Electrical Current";
CM_ SG_ 793 EAC_CompIGBTTempV "Compressor IGBT Temperature Validity";
CM_ SG_ 793 EAC_CompHVInputV "Compressor High Voltage Input Validity";
CM_ SG_ 793 EAC_CompBoardTempV "Compressor Board Temperature Validity";
CM_ SG_ 793 EAC_CompBoardTemp "Compressor Board Temperature";
CM_ SG_ 793 EAC_CompHVInput "Compressor High Voltage Input";
CM_ SG_ 793 EAC_CompIGBTTemp "Compressor IGBT Temperature";
CM_ SG_ 524 Checksum_0x20C "Checksum";
CM_ SG_ 524 Rolling_Counter_0x20C "Rolling_Counter";
CM_ SG_ 524 IPC_ODO "odograph";
CM_ SG_ 703 IPC_TripA "Set Trip A";
CM_ SG_ 703 IPC_AverageSpeedTripA "Average Speed of TripA";
CM_ SG_ 703 IPC_AverageConsumptionTripA "Average Consumption of TripA";
CM_ SG_ 703 IPC_ParkBrakeSts "Park Brake Status";
CM_ SG_ 703 IPC_VehSpd "Current Displayed Longitudinal Vehicle Speed";
CM_ SG_ 1087 IPC_Sec "Represents the current second.60 - 63 = Invalid";
CM_ SG_ 1087 IPC_Min "Represents the current minute. 60 - 63 = Invalid";
CM_ SG_ 1087 IPC_Hour "Represents the current hour, 24 - 30 = not used";
CM_ SG_ 1087 IPC_Day "Represents the current dayInvalid value = 0";
CM_ SG_ 1087 IPC_Month "Represents the current month.0, 13 to 15 = Invalid";
CM_ SG_ 1087 IPC_Year "Represents the current year.";
CM_ SG_ 1087 IPC_SelfCheckStatus "Power on self check status";
CM_ SG_ 1074 Checksum_0x432 "Checksum";
CM_ SG_ 1074 Rolling_Counter_0x432 "Rolling_Counter";
CM_ SG_ 1074 MHU_FOTA_State "FOTA global status";
CM_ SG_ 1074 MHU_FOTA_Error_Code "FOTA Error Code";
CM_ SG_ 1027 Checksum_0x403 "Checksum";
CM_ SG_ 1027 Rolling_Counter_0x403 "Rolling_Counter";
CM_ SG_ 1027 MHU_SET_TCS_OnOff "Change TCS mode ON/OFF";
CM_ SG_ 1027 MHU_SET_DrivingModeSwitch "Change vehicle driving mode";
CM_ SG_ 1027 MHU_SET_RegenLevel "Set power regenerative level";
CM_ SG_ 1027 MHU_VCU_CreepDisable_stt "Request for VCU to disable creep function";
CM_ SG_ 1027 MHU_ChargeSetTargetSOC "Request for VCU to set target HV SOC";
CM_ SG_ 1027 MHU_HVACTurnON "Turning ON HVAC remotely";
CM_ SG_ 1027 MHU_ChargeScheduleSet "Request for VCU to enable/disable Charging Scheduling";
CM_ SG_ 1027 MHU_ChargingRequest "Request for VCU to ON/OFF Charging when schedule is reached";
CM_ SG_ 1027 MHU_ValetMode_Activation "Activate Valet mode from MHU";
CM_ SG_ 1027 MHU_ValetMode_MaxSpeed "Setting of maximum allowable in valet mode";
CM_ SG_ 811 CCU_TemperatureGearSts "Temperature Gear Status";
CM_ SG_ 811 CCU_BlowMode_Sts "Blow Mode_Status";
CM_ SG_ 811 CCU_Circulation_Sts "CCU intake cycle state";
CM_ SG_ 811 CCU_AC_Req "Compressor request switch signal";
CM_ SG_ 811 CCU_AC_Sts "AC Status";
CM_ SG_ 811 CCU_BlowerLevelSts "Blower_Level";
CM_ SG_ 811 CCU_FrontDefrostSts "Defrost_Status";
CM_ SG_ 811 CCU_PTC_Req "CCU request VCU to enable or disable PTC";
CM_ SG_ 811 CCU_PTC_Temperature "PTC Temperature";
CM_ SG_ 811 CCU_CompSpdMEAS_Comp "Compressor speed signal";
CM_ SG_ 811 CCU_PollutionSts "Pollution mode state";
CM_ SG_ 811 CCU_ExternalTemperature "External Temperature";
CM_ SG_ 811 CCU_evaporator_Temperature "evaporator Temperature";
CM_ SG_ 811 CCU_ExternalTemperatureFailSts "External Temperature Fail Sts";
CM_ SG_ 1015 MFS_OK_Control "OK Control";
CM_ SG_ 1015 MFS_SourseControl "Resourse Control";
CM_ SG_ 1015 MFS_VoiceRecognitionOn_Off "VoiceRecognition control";
CM_ SG_ 1015 MFS_TelephoneCall_EndCall "Telephone Call funtionality control";
CM_ SG_ 1015 MFS_DownControl "Down Control";
CM_ SG_ 1015 MFS_UpControl "Up Control";
CM_ SG_ 1015 MFS_RightControl "Right Control";
CM_ SG_ 1015 MFS_LeftControl "Left Control";
CM_ SG_ 1015 MFS_CruiseOn_Off "Cruise control On Off";
CM_ SG_ 1015 MFS_Failure "Multi-Funtion Switch Failure";
CM_ SG_ 1015 MFS_ISAControl "ISA Control";
CM_ SG_ 1015 MFS_LKAControl "LKA Control";
CM_ SG_ 1015 MFS_CruiseGapDecrease "Cruise Gap Decrease";
CM_ SG_ 1015 MFS_CruiseSpeedDecrease "Cruise Speed Decrease";
CM_ SG_ 1015 MFS_CruiseSpeedIncrease "Cruise Speed Increase";
CM_ SG_ 1015 MFS_CruiseCancel "Cruise funtionality Cancel";
CM_ SG_ 1015 MFS_CruiseGapIncrease "Cruise Gap Increase";
CM_ SG_ 920 BCM_Immo_Byte_0 "BCM Authentication signal byte 0";
CM_ SG_ 920 BCM_Immo_Byte_1 "BCM Authentication signal byte 1";
CM_ SG_ 920 BCM_Immo_Byte_2 "BCM Authentication signal byte 2";
CM_ SG_ 920 BCM_Immo_Byte_3 "BCM Authentication signal byte 3";
CM_ SG_ 920 BCM_Immo_Byte_4 "BCM Authentication signal byte 4";
CM_ SG_ 920 BCM_Immo_Byte_5 "BCM Authentication signal byte 5";
CM_ SG_ 920 BCM_Immo_Byte_6 "BCM Authentication signal byte 6";
CM_ SG_ 920 BCM_Immo_Byte_7 "BCM Authentication signal byte 7";
CM_ SG_ 921 VCU_Immo_Byte_0 "VCU Authentication signal byte 0";
CM_ SG_ 921 VCU_Immo_Byte_1 "VCU Authentication signal byte 1";
CM_ SG_ 921 VCU_Immo_Byte_2 "VCU Authentication signal byte 2";
CM_ SG_ 921 VCU_Immo_Byte_3 "VCU Authentication signal byte 3";
CM_ SG_ 921 VCU_Immo_Byte_4 "VCU Authentication signal byte 4";
CM_ SG_ 921 VCU_Immo_Byte_5 "VCU Authentication signal byte 5";
CM_ SG_ 921 VCU_Immo_Byte_6 "VCU Authentication signal byte 6";
CM_ SG_ 921 VCU_Immo_Byte_7 "VCU Authentication signal byte 7";
CM_ SG_ 929 BMS_MHU_Rand_Num_Byte_0 "Random number sent by BMS";
CM_ SG_ 929 BMS_MHU_Rand_Num_Byte_1 "Random number sent by BMS";
CM_ SG_ 929 BMS_MHU_Rand_Num_Byte_2 "Random number sent by BMS";
CM_ SG_ 929 BMS_MHU_Rand_Num_Byte_3 "Random number sent by BMS";
CM_ SG_ 929 BMS_MHU_Rand_Num_Byte_4 "Random number sent by BMS";
CM_ SG_ 929 BMS_MHU_Rand_Num_Byte_5 "Random number sent by BMS";
CM_ SG_ 929 BMS_MHU_Rand_Num_Byte_6 "Random number sent by BMS";
CM_ SG_ 929 BMS_MHU_Rand_Num_Byte_7 "Random number sent by BMS";
CM_ SG_ 930 MHU_BMS_Enc_Result_Byte_0 "MHU Encryption result";
CM_ SG_ 930 MHU_BMS_Enc_Result_Byte_1 "MHU Encryption result";
CM_ SG_ 930 MHU_BMS_Enc_Result_Byte_2 "MHU Encryption result";
CM_ SG_ 930 MHU_BMS_Enc_Result_Byte_3 "MHU Encryption result";
CM_ SG_ 930 MHU_BMS_Enc_Result_Byte_4 "MHU Encryption result";
CM_ SG_ 930 MHU_BMS_Enc_Result_Byte_5 "MHU Encryption result";
CM_ SG_ 930 MHU_BMS_Enc_Result_Byte_6 "MHU Encryption result";
CM_ SG_ 930 MHU_BMS_Enc_Result_Byte_7 "MHU Encryption result";
CM_ SG_ 274 Checksum_0x112 "Checksum";
CM_ SG_ 274 Rolling_Counter_0x112 "Rolling_Counter";
CM_ SG_ 274 STAT_Terminal "Represent the status of physical terminal(STAT_Terminal to be received by all modules,Required for DTC snapshots and for FOTA)";
CM_ SG_ 274 STAT_CL30s_L_Reserved "Status Clamp 30s Logical ON/OFF";
CM_ SG_ 976 BCM_STAT_DoorAjarDriver "Ajar Door Driver Status";
CM_ SG_ 976 STAT_DoorLockDriver "Lock Status Driver Door used as central lock information(lock/unlock the vehicle by the fob/PESW/CentralLock button)";
CM_ SG_ 283 BCM_ACCRelayOutputSts "ACCRelays Output Status";
CM_ SG_ 283 BCM_IGN1RelayOutputSts "IG1 Relays Output Status";
CM_ SG_ 283 BCM_ACCRelayFalutSts "ACCRelays Fault Status";
CM_ SG_ 283 BCM_IGN1RelayFalutSts "IG1 Relays Fault Status";
CM_ SG_ 283 BCM_KEY_MatchSts "Match status with Key";
CM_ SG_ 266 Checksum_0x10a "Checksum";
CM_ SG_ 266 Rolling_Counter_0x10a "Rolling_Counter";
CM_ SG_ 266 BCM_LVTop_up "LV  battery top up requice signal";
CM_ SG_ 266 Ubatt_Reserved "Battery Voltage(UBatt to be received by all modules,Required for DTC snapshots)";
CM_ SG_ 133 Checksum_0x85 "Checksum";
CM_ SG_ 133 Rolling_Counter_0x85 "Rolling Counter";
CM_ SG_ 133 ACM_Crash_Sts "Crash status";
CM_ SG_ 133 ACM_Airbag_Deployment_Status "Signal to indicate if airbag/pretensioner/pyrofuse is deployed";
CM_ SG_ 133 ACM_Crash_Intensity "Indicate crash intensity level";
CM_ SG_ 133 ACM_Front_Crash "Output information for direction of crash";
CM_ SG_ 133 ACM_DriverSide_Crash "Output information for direction of crash";
CM_ SG_ 133 ACM_PassSide_Crash "Output information for direction of crash";
CM_ SG_ 133 ACM_Rear_Crash "Output information for direction of crash";
CM_ SG_ 133 ACM_Rollover_Crash "Output information for direction of crash";
CM_ SG_ 834 Checksum_0x342 "Check sum";
CM_ SG_ 834 Rolling_Counter_0x342 "Rolling Counter";
CM_ SG_ 834 ABS_LRWhlSpdRaw "Current Raw wheel speed information of rear left wheel.";
CM_ SG_ 834 ABS_LRWhlSpdRawValid "Current Raw wheel speed information valid flag of rear left wheel.";
CM_ SG_ 834 ABS_RRWhlSpdRaw "Current Raw wheel speed information of rear right wheel.,";
CM_ SG_ 834 ABS_RRWhlSpdRawValid "Current Raw wheel speed information valid flag of rear right wheel";
CM_ SG_ 834 ABS_VehSpd "Current Longitudinal Vehicle Speed";
CM_ SG_ 834 ABS_VehSpdValid "Speed Valid Flag";
CM_ SG_ 149 Checksum_0x95 "Checksum";
CM_ SG_ 149 RollingCounter_0x95 "Alive counter";
CM_ SG_ 149 ABS_Active "ABS function active.";
CM_ SG_ 149 ASR_Active "ASR Traction Control active";
CM_ SG_ 1299 BMS_sourceID "source ID";
CM_ SG_ 1299 BMS_CBV "CBV";
CM_ SG_ 1299 BMS_Data0 "Data0";
CM_ SG_ 1299 BMS_Data1 "Data1";
CM_ SG_ 1299 BMS_Data2 "Data2";
CM_ SG_ 1299 BMS_Data3 "Data3";
CM_ SG_ 1299 BMS_Data4 "Data4";
CM_ SG_ 1299 BMS_Data5 "Data5";
CM_ SG_ 1324 VCU_sourceID "source ID";
CM_ SG_ 1324 VCU_CBV "CBV";
CM_ SG_ 1324 VCU_Data0 "Data0";
CM_ SG_ 1324 VCU_Data1 "Data1";
CM_ SG_ 1324 VCU_Data2 "Data2";
CM_ SG_ 1324 VCU_Data3 "Data3";
CM_ SG_ 1324 VCU_Data4 "Data4";
CM_ SG_ 1324 VCU_Data5 "Data5";
CM_ SG_ 1341 PDU_DCDC_sourceID "source ID";
CM_ SG_ 1341 PDU_DCDC_CBV "CBV";
CM_ SG_ 1341 PDU_DCDC_Data0 "Data0";
CM_ SG_ 1341 PDU_DCDC_Data1 "Data1";
CM_ SG_ 1341 PDU_DCDC_Data2 "Data2";
CM_ SG_ 1341 PDU_DCDC_Data3 "Data3";
CM_ SG_ 1341 PDU_DCDC_Data4 "Data4";
CM_ SG_ 1341 PDU_DCDC_Data5 "Data5";
CM_ SG_ 1307 EDS_sourceID "source ID";
CM_ SG_ 1307 EDS_CBV "CBV";
CM_ SG_ 1307 EDS_Data0 "Data0";
CM_ SG_ 1307 EDS_Data1 "Data1";
CM_ SG_ 1307 EDS_Data2 "Data2";
CM_ SG_ 1307 EDS_Data3 "Data3";
CM_ SG_ 1307 EDS_Data4 "Data4";
CM_ SG_ 1307 EDS_Data5 "Data5";
CM_ SG_ 1311 EVCC_sourceID "source ID";
CM_ SG_ 1311 EVCC_CBV "CBV";
CM_ SG_ 1311 EVCC_Data0 "Data0";
CM_ SG_ 1311 EVCC_Data1 "Data1";
CM_ SG_ 1311 EVCC_Data2 "Data2";
CM_ SG_ 1311 EVCC_Data3 "Data3";
CM_ SG_ 1311 EVCC_Data4 "Data4";
CM_ SG_ 1311 EVCC_Data5 "Data5";
CM_ SG_ 1282 GW_sourceID "source ID";
CM_ SG_ 1282 GW_CBV "CBV";
CM_ SG_ 1282 GW_Data0 "Data0";
CM_ SG_ 1282 GW_Data1 "Data1";
CM_ SG_ 1282 GW_Data2 "Data2";
CM_ SG_ 1282 GW_Data3 "Data3";
CM_ SG_ 1282 GW_Data4 "Data4";
CM_ SG_ 1282 GW_Data5 "Data5";
CM_ SG_ 1683 BMS_DiagReqData0 "Data0";
CM_ SG_ 1683 BMS_DiagReqData1 "Data1";
CM_ SG_ 1683 BMS_DiagReqData2 "Data2";
CM_ SG_ 1683 BMS_DiagReqData3 "Data3";
CM_ SG_ 1683 BMS_DiagReqData4 "Data4";
CM_ SG_ 1683 BMS_DiagReqData5 "Data5";
CM_ SG_ 1683 BMS_DiagReqData6 "Data6";
CM_ SG_ 1683 BMS_DiagReqData7 "Data7";
CM_ SG_ 1555 BMS_DiagRespData0 "Data0";
CM_ SG_ 1555 BMS_DiagRespData1 "Data1";
CM_ SG_ 1555 BMS_DiagRespData2 "Data2";
CM_ SG_ 1555 BMS_DiagRespData3 "Data3";
CM_ SG_ 1555 BMS_DiagRespData4 "Data4";
CM_ SG_ 1555 BMS_DiagRespData5 "Data5";
CM_ SG_ 1555 BMS_DiagRespData6 "Data6";
CM_ SG_ 1555 BMS_DiagRespData7 "Data7";
CM_ SG_ 1708 VCU_DiagReqData0 "Data0";
CM_ SG_ 1708 VCU_DiagReqData1 "Data1";
CM_ SG_ 1708 VCU_DiagReqData2 "Data2";
CM_ SG_ 1708 VCU_DiagReqData3 "Data3";
CM_ SG_ 1708 VCU_DiagReqData4 "Data4";
CM_ SG_ 1708 VCU_DiagReqData5 "Data5";
CM_ SG_ 1708 VCU_DiagReqData6 "Data6";
CM_ SG_ 1708 VCU_DiagReqData7 "Data7";
CM_ SG_ 1580 VCU_DiagRespData0 "Data0";
CM_ SG_ 1580 VCU_DiagRespData1 "Data1";
CM_ SG_ 1580 VCU_DiagRespData2 "Data2";
CM_ SG_ 1580 VCU_DiagRespData3 "Data3";
CM_ SG_ 1580 VCU_DiagRespData4 "Data4";
CM_ SG_ 1580 VCU_DiagRespData5 "Data5";
CM_ SG_ 1580 VCU_DiagRespData6 "Data6";
CM_ SG_ 1580 VCU_DiagRespData7 "Data7";
CM_ SG_ 1725 PDU_DiagReqData0 "Data0";
CM_ SG_ 1725 PDU_DiagReqData1 "Data1";
CM_ SG_ 1725 PDU_DiagReqData2 "Data2";
CM_ SG_ 1725 PDU_DiagReqData3 "Data3";
CM_ SG_ 1725 PDU_DiagReqData4 "Data4";
CM_ SG_ 1725 PDU_DiagReqData5 "Data5";
CM_ SG_ 1725 PDU_DiagReqData6 "Data6";
CM_ SG_ 1725 PDU_DiagReqData7 "Data7";
CM_ SG_ 1597 PDU_DiagRespData0 "Data0";
CM_ SG_ 1597 PDU_DiagRespData1 "Data1";
CM_ SG_ 1597 PDU_DiagRespData2 "Data2";
CM_ SG_ 1597 PDU_DiagRespData3 "Data3";
CM_ SG_ 1597 PDU_DiagRespData4 "Data4";
CM_ SG_ 1597 PDU_DiagRespData5 "Data5";
CM_ SG_ 1597 PDU_DiagRespData6 "Data6";
CM_ SG_ 1597 PDU_DiagRespData7 "Data7";
CM_ SG_ 1691 EDS_DiagReqData0 "Data0";
CM_ SG_ 1691 EDS_DiagReqData1 "Data1";
CM_ SG_ 1691 EDS_DiagReqData2 "Data2";
CM_ SG_ 1691 EDS_DiagReqData3 "Data3";
CM_ SG_ 1691 EDS_DiagReqData4 "Data4";
CM_ SG_ 1691 EDS_DiagReqData5 "Data5";
CM_ SG_ 1691 EDS_DiagReqData6 "Data6";
CM_ SG_ 1691 EDS_DiagReqData7 "Data7";
CM_ SG_ 1563 EDS_DiagRespData0 "Data0";
CM_ SG_ 1563 EDS_DiagRespData1 "Data1";
CM_ SG_ 1563 EDS_DiagRespData2 "Data2";
CM_ SG_ 1563 EDS_DiagRespData3 "Data3";
CM_ SG_ 1563 EDS_DiagRespData4 "Data4";
CM_ SG_ 1563 EDS_DiagRespData5 "Data5";
CM_ SG_ 1563 EDS_DiagRespData6 "Data6";
CM_ SG_ 1563 EDS_DiagRespData7 "Data7";
CM_ SG_ 1781 EAC_DiagReqData0 "Data0";
CM_ SG_ 1781 EAC_DiagReqData1 "Data1";
CM_ SG_ 1781 EAC_DiagReqData2 "Data2";
CM_ SG_ 1781 EAC_DiagReqData3 "Data3";
CM_ SG_ 1781 EAC_DiagReqData4 "Data4";
CM_ SG_ 1781 EAC_DiagReqData5 "Data5";
CM_ SG_ 1781 EAC_DiagReqData6 "Data6";
CM_ SG_ 1781 EAC_DiagReqData7 "Data7";
CM_ SG_ 1653 EAC_DiagRespData0 "Data0";
CM_ SG_ 1653 EAC_DiagRespData1 "Data1";
CM_ SG_ 1653 EAC_DiagRespData2 "Data2";
CM_ SG_ 1653 EAC_DiagRespData3 "Data3";
CM_ SG_ 1653 EAC_DiagRespData4 "Data4";
CM_ SG_ 1653 EAC_DiagRespData5 "Data5";
CM_ SG_ 1653 EAC_DiagRespData6 "Data6";
CM_ SG_ 1653 EAC_DiagRespData7 "Data7";
CM_ SG_ 1695 EVCC_DiagReqData0 "Data0";
CM_ SG_ 1695 EVCC_DiagReqData1 "Data1";
CM_ SG_ 1695 EVCC_DiagReqData2 "Data2";
CM_ SG_ 1695 EVCC_DiagReqData3 "Data3";
CM_ SG_ 1695 EVCC_DiagReqData4 "Data4";
CM_ SG_ 1695 EVCC_DiagReqData5 "Data5";
CM_ SG_ 1695 EVCC_DiagReqData6 "Data6";
CM_ SG_ 1695 EVCC_DiagReqData7 "Data7";
CM_ SG_ 1567 EVCC_DiagRespData0 "Data0";
CM_ SG_ 1567 EVCC_DiagRespData1 "Data1";
CM_ SG_ 1567 EVCC_DiagRespData2 "Data2";
CM_ SG_ 1567 EVCC_DiagRespData3 "Data3";
CM_ SG_ 1567 EVCC_DiagRespData4 "Data4";
CM_ SG_ 1567 EVCC_DiagRespData5 "Data5";
CM_ SG_ 1567 EVCC_DiagRespData6 "Data6";
CM_ SG_ 1567 EVCC_DiagRespData7 "Data7";
CM_ SG_ 1791 GW_DiagFunctionalAddressingData0 "Data0";
CM_ SG_ 1791 GW_DiagFunctionalAddressingData1 "Data1";
CM_ SG_ 1791 GW_DiagFunctionalAddressingData2 "Data2";
CM_ SG_ 1791 GW_DiagFunctionalAddressingData3 "Data3";
CM_ SG_ 1791 GW_DiagFunctionalAddressingData4 "Data4";
CM_ SG_ 1791 GW_DiagFunctionalAddressingData5 "Data5";
CM_ SG_ 1791 GW_DiagFunctionalAddressingData6 "Data6";
CM_ SG_ 1791 GW_DiagFunctionalAddressingData7 "Data7";
BA_DEF_ BO_ "DiagRequest" ENUM "No","Yes";
BA_DEF_ BO_ "DiagResponse" ENUM "No","Yes";
BA_DEF_ BO_ "DiagState" ENUM "No","Yes";
BA_DEF_ BO_ "GenMsgCycleTime" INT 0 65535;
BA_DEF_ BO_ "GenMsgCycleTimeFast" INT 0 65535;
BA_DEF_ BO_ "GenMsgDelayTime" INT 0 65535;
BA_DEF_ BO_ "GenMsgILSupport" ENUM "No","Yes";
BA_DEF_ BO_ "GenMsgNrOfRepetition" INT 0 65535;
BA_DEF_ BO_ "GenMsgSendType" ENUM  "Cycle","Event","IfActive","CE","CA";
BA_DEF_ BO_ "NmAsrMessage" ENUM "No","Yes";
BA_DEF_ BO_ "NmMessage" ENUM "No","Yes";
BA_DEF_ SG_ "GenSigSendType" ENUM  "Cycle","OnWrite","OnWriteWithRepetition","OnChange","OnChangeWithRepetition","IfActive","IfActiveWithRepetition";
BA_DEF_ SG_ "GenSigStartValue" INT 0 2147483647;
BA_DEF_ SG_ "GenSigInvalidValue" INT 0 2147483647;
BA_DEF_ SG_ "GenSigInactiveValue" INT 0 2147483647;
BA_DEF_DEF_ "DiagRequest" "No";
BA_DEF_DEF_ "DiagResponse" "No";
BA_DEF_DEF_ "DiagState" "No";
BA_DEF_DEF_ "GenMsgCycleTime" 0;
BA_DEF_DEF_ "GenMsgCycleTimeFast" 0;
BA_DEF_DEF_ "GenMsgDelayTime" 0;
BA_DEF_DEF_ "GenMsgILSupport" "Yes";
BA_DEF_DEF_ "GenMsgNrOfRepetition" 0;
BA_DEF_DEF_ "GenMsgSendType" "NoMsgSendType";
BA_DEF_DEF_ "GenSigSendType" "NoSigSendType";
BA_DEF_DEF_ "GenSigStartValue" 0;
BA_DEF_DEF_  "GenSigInvalidValue" 0;
BA_DEF_DEF_ "GenSigInactiveValue" 0;
BA_DEF_DEF_ "NmAsrMessage" "No";
BA_DEF_DEF_ "NmMessage" "No";
BA_ "GenMsgSendType" BO_ 504 0;
BA_ "GenMsgCycleTime" BO_ 504 10;
BA_ "GenMsgSendType" BO_ 680 0;
BA_ "GenMsgCycleTime" BO_ 680 20;
BA_ "GenMsgSendType" BO_ 568 0;
BA_ "GenMsgCycleTime" BO_ 568 20;
BA_ "GenMsgSendType" BO_ 1080 0;
BA_ "GenMsgCycleTime" BO_ 1080 100;
BA_ "GenMsgSendType" BO_ 537 0;
BA_ "GenMsgCycleTime" BO_ 537 20;
BA_ "GenMsgSendType" BO_ 544 0;
BA_ "GenMsgCycleTime" BO_ 544 100;
BA_ "GenMsgSendType" BO_ 757 0;
BA_ "GenMsgCycleTime" BO_ 757 50;
BA_ "GenMsgSendType" BO_ 725 0;
BA_ "GenMsgCycleTime" BO_ 725 50;
BA_ "GenMsgSendType" BO_ 553 0;
BA_ "GenMsgCycleTime" BO_ 553 10;
BA_ "GenMsgSendType" BO_ 937 0;
BA_ "GenMsgCycleTime" BO_ 937 20;
BA_ "GenMsgSendType" BO_ 425 0;
BA_ "GenMsgCycleTime" BO_ 425 20;
BA_ "GenMsgSendType" BO_ 441 0;
BA_ "GenMsgCycleTime" BO_ 441 50;
BA_ "GenMsgSendType" BO_ 992 0;
BA_ "GenMsgCycleTime" BO_ 992 100;
BA_ "GenMsgSendType" BO_ 409 0;
BA_ "GenMsgCycleTime" BO_ 409 50;
BA_ "GenMsgSendType" BO_ 889 0;
BA_ "GenMsgCycleTime" BO_ 889 50;
BA_ "GenMsgSendType" BO_ 905 0;
BA_ "GenMsgCycleTime" BO_ 905 50;
BA_ "GenMsgSendType" BO_ 273 0;
BA_ "GenMsgCycleTime" BO_ 273 20;
BA_ "GenMsgSendType" BO_ 1145 0;
BA_ "GenMsgCycleTime" BO_ 1145 100;
BA_ "GenMsgSendType" BO_ 745 0;
BA_ "GenMsgCycleTime" BO_ 745 50;
BA_ "GenMsgSendType" BO_ 792 0;
BA_ "GenMsgCycleTime" BO_ 792 50;
BA_ "GenMsgSendType" BO_ 793 0;
BA_ "GenMsgCycleTime" BO_ 793 50;
BA_ "GenMsgSendType" BO_ 524 0;
BA_ "GenMsgCycleTime" BO_ 524 100;
BA_ "GenMsgSendType" BO_ 703 0;
BA_ "GenMsgCycleTime" BO_ 703 50;
BA_ "GenMsgSendType" BO_ 1087 0;
BA_ "GenMsgCycleTime" BO_ 1087 1000;
BA_ "GenMsgSendType" BO_ 1074 0;
BA_ "GenMsgDelayTime" BO_ 1074 50;
BA_ "GenMsgCycleTime" BO_ 1074 100;
BA_ "GenMsgSendType" BO_ 1027 3;
BA_ "GenMsgNrOfRepetition" BO_ 1027 5;
BA_ "GenMsgCycleTimeFast" BO_ 1027 20;
BA_ "GenMsgCycleTime" BO_ 1027 100;
BA_ "GenMsgSendType" BO_ 811 0;
BA_ "GenMsgCycleTime" BO_ 811 50;
BA_ "GenMsgSendType" BO_ 1015 3;
BA_ "GenMsgNrOfRepetition" BO_ 1015 5;
BA_ "GenMsgCycleTimeFast" BO_ 1015 50;
BA_ "GenMsgCycleTime" BO_ 1015 1000;
BA_ "GenMsgSendType" BO_ 920 1;
BA_ "GenMsgSendType" BO_ 921 1;
BA_ "GenMsgSendType" BO_ 929 1;
BA_ "GenMsgDelayTime" BO_ 929 10;
BA_ "GenMsgSendType" BO_ 930 1;
BA_ "GenMsgDelayTime" BO_ 930 10;
BA_ "GenMsgSendType" BO_ 274 0;
BA_ "GenMsgCycleTime" BO_ 274 100;
BA_ "GenMsgSendType" BO_ 976 0;
BA_ "GenMsgCycleTime" BO_ 976 50;
BA_ "GenMsgSendType" BO_ 283 0;
BA_ "GenMsgCycleTime" BO_ 283 20;
BA_ "GenMsgSendType" BO_ 266 0;
BA_ "GenMsgCycleTime" BO_ 266 100;
BA_ "GenMsgSendType" BO_ 769 0;
BA_ "GenMsgCycleTime" BO_ 769 200;
BA_ "GenMsgSendType" BO_ 133 0;
BA_ "GenMsgCycleTime" BO_ 133 20;
BA_ "GenMsgSendType" BO_ 834 0;
BA_ "GenMsgCycleTime" BO_ 834 10;
BA_ "GenMsgSendType" BO_ 149 0;
BA_ "GenMsgCycleTime" BO_ 149 100;
BA_ "GenMsgSendType" BO_ 1299 2;
BA_ "GenMsgCycleTime" BO_ 1299 640;
BA_ "NmAsrMessage" BO_ 1299 1;
BA_ "NmMessage" BO_ 1299 1;
BA_ "GenMsgSendType" BO_ 1324 2;
BA_ "GenMsgCycleTime" BO_ 1324 640;
BA_ "NmAsrMessage" BO_ 1324 1;
BA_ "NmMessage" BO_ 1324 1;
BA_ "GenMsgSendType" BO_ 1341 2;
BA_ "GenMsgCycleTime" BO_ 1341 640;
BA_ "NmAsrMessage" BO_ 1341 1;
BA_ "NmMessage" BO_ 1341 1;
BA_ "GenMsgSendType" BO_ 1307 2;
BA_ "GenMsgCycleTime" BO_ 1307 640;
BA_ "NmAsrMessage" BO_ 1307 1;
BA_ "NmMessage" BO_ 1307 1;
BA_ "GenMsgSendType" BO_ 1311 2;
BA_ "GenMsgCycleTime" BO_ 1311 640;
BA_ "NmAsrMessage" BO_ 1311 1;
BA_ "NmMessage" BO_ 1311 1;
BA_ "GenMsgSendType" BO_ 1282 2;
BA_ "GenMsgCycleTime" BO_ 1282 640;
BA_ "NmAsrMessage" BO_ 1282 1;
BA_ "NmMessage" BO_ 1282 1;
BA_ "GenMsgSendType" BO_ 1683 1;
BA_ "DiagRequest" BO_ 1683 1;
BA_ "GenMsgSendType" BO_ 1555 1;
BA_ "DiagResponse" BO_ 1555 1;
BA_ "GenMsgSendType" BO_ 1708 1;
BA_ "DiagRequest" BO_ 1708 1;
BA_ "GenMsgSendType" BO_ 1580 1;
BA_ "DiagResponse" BO_ 1580 1;
BA_ "GenMsgSendType" BO_ 1725 1;
BA_ "DiagRequest" BO_ 1725 1;
BA_ "GenMsgSendType" BO_ 1597 1;
BA_ "DiagResponse" BO_ 1597 1;
BA_ "GenMsgSendType" BO_ 1691 1;
BA_ "DiagRequest" BO_ 1691 1;
BA_ "GenMsgSendType" BO_ 1563 1;
BA_ "DiagResponse" BO_ 1563 1;
BA_ "GenMsgSendType" BO_ 1781 1;
BA_ "DiagRequest" BO_ 1781 1;
BA_ "GenMsgSendType" BO_ 1653 1;
BA_ "DiagResponse" BO_ 1653 1;
BA_ "GenMsgSendType" BO_ 1695 1;
BA_ "DiagRequest" BO_ 1695 1;
BA_ "GenMsgSendType" BO_ 1567 1;
BA_ "DiagResponse" BO_ 1567 1;
BA_ "GenMsgSendType" BO_ 1791 1;
BA_ "DiagState" BO_ 1791 1;
BA_ "GenSigSendType" SG_ 504 Checksum_0x1F8 0;
BA_ "GenSigSendType" SG_ 504 Rolling_Counter_0x1F8 0;
BA_ "GenSigInvalidValue" SG_ 504 Rolling_Counter_0x1F8 15;
BA_ "GenSigSendType" SG_ 504 EDS_output_trq_FR 0;
BA_ "GenSigInvalidValue" SG_ 504 EDS_output_trq_FR 65535;
BA_ "GenSigStartValue" SG_ 504 EDS_output_trq_FR 2000;
BA_ "GenSigSendType" SG_ 504 EDS_output_trqValid_FR 0;
BA_ "GenSigSendType" SG_ 504 EDS_Spd_FR 0;
BA_ "GenSigInvalidValue" SG_ 504 EDS_Spd_FR 65535;
BA_ "GenSigStartValue" SG_ 504 EDS_Spd_FR 20000;
BA_ "GenSigSendType" SG_ 504 EDS_SpdValid_FR 0;
BA_ "GenSigSendType" SG_ 504 EDS_MotorDriveSts_FR 0;
BA_ "GenSigInvalidValue" SG_ 504 EDS_MotorDriveSts_FR 3;
BA_ "GenSigSendType" SG_ 504 EDS_Work_STS_FR 0;
BA_ "GenSigInvalidValue" SG_ 504 EDS_Work_STS_FR 15;
BA_ "GenSigSendType" SG_ 504 EDS_powoff_req_FR 0;
BA_ "GenSigSendType" SG_ 680 Checksum_0x2A8 0;
BA_ "GenSigSendType" SG_ 680 Rolling_Counter_0x2A8 0;
BA_ "GenSigInvalidValue" SG_ 680 Rolling_Counter_0x2A8 15;
BA_ "GenSigSendType" SG_ 680 EDS_MotorSerialNum_FWD 0;
BA_ "GenSigStartValue" SG_ 680 EDS_MotorSerialNum_FWD 1;
BA_ "GenSigSendType" SG_ 680 EDS_MinTrq_FWD 0;
BA_ "GenSigInvalidValue" SG_ 680 EDS_MinTrq_FWD 65535;
BA_ "GenSigStartValue" SG_ 680 EDS_MinTrq_FWD 4000;
BA_ "GenSigSendType" SG_ 680 EDS_MaxTrq_FWD 0;
BA_ "GenSigInvalidValue" SG_ 680 EDS_MaxTrq_FWD 65535;
BA_ "GenSigStartValue" SG_ 680 EDS_MaxTrq_FWD 4000;
BA_ "GenSigSendType" SG_ 568 EDS_MotTemp_MEAS_EDS_FWD 0;
BA_ "GenSigInvalidValue" SG_ 568 EDS_MotTemp_MEAS_EDS_FWD 255;
BA_ "GenSigStartValue" SG_ 568 EDS_MotTemp_MEAS_EDS_FWD 80;
BA_ "GenSigSendType" SG_ 568 EDS_MotTemp_MEAS_EDS_valid_FWD 0;
BA_ "GenSigSendType" SG_ 568 EDS_temp_FWD 0;
BA_ "GenSigInvalidValue" SG_ 568 EDS_temp_FWD 255;
BA_ "GenSigStartValue" SG_ 568 EDS_temp_FWD 80;
BA_ "GenSigSendType" SG_ 568 EDS_tempValid_FWD 0;
BA_ "GenSigSendType" SG_ 568 EDS_disxhg_st_FWD 0;
BA_ "GenSigSendType" SG_ 568 EDS_IGBTState_FWD 0;
BA_ "GenSigSendType" SG_ 568 EDS_DampingState_FWD 0;
BA_ "GenSigSendType" SG_ 568 EDS_CoolFlowrate_DMD_FWD 0;
BA_ "GenSigInvalidValue" SG_ 568 EDS_CoolFlowrate_DMD_FWD 255;
BA_ "GenSigSendType" SG_ 1080 EDS_FailNum_ERR_FWD 0;
BA_ "GenSigSendType" SG_ 1080 EDS_FailGrade_ERR_FWD 0;
BA_ "GenSigSendType" SG_ 1080 EDS_MotOverTempAlarm_FWD 0;
BA_ "GenSigSendType" SG_ 1080 EDS_MotOverTempFault_FWD 0;
BA_ "GenSigSendType" SG_ 1080 EDS_MotTempSenFault_FWD 0;
BA_ "GenSigSendType" SG_ 1080 EDS_EDSOverTempUFault_FWD 0;
BA_ "GenSigSendType" SG_ 1080 EDS_EDSOverTempVFault_FWD 0;
BA_ "GenSigSendType" SG_ 1080 EDS_EDSOverTempWFault_FWD 0;
BA_ "GenSigSendType" SG_ 1080 EDS_EDSOverTempAlarm_FWD 0;
BA_ "GenSigSendType" SG_ 1080 EDS_TCoolantOvHi_FWD 0;
BA_ "GenSigSendType" SG_ 1080 EDS_EDSTempCmpAlarm_FWD 0;
BA_ "GenSigSendType" SG_ 1080 EDS_EDSPhaOvCurentHWFault_FWD 0;
BA_ "GenSigSendType" SG_ 1080 EDS_EDSphaOffCalFault_FWD 0;
BA_ "GenSigSendType" SG_ 1080 EDS_EDSOverIdcLnkAlarm_FWD 0;
BA_ "GenSigSendType" SG_ 1080 EDS_EDSHVOverVoltageAlarm_FWD 0;
BA_ "GenSigSendType" SG_ 1080 EDS_EDSHVOverVoltageFault_FWD 0;
BA_ "GenSigSendType" SG_ 1080 EDS_EDSHVUnderVoltageAlarm_FWD 0;
BA_ "GenSigSendType" SG_ 1080 EDS_EDSHVUnderVoltageFault_FWD 0;
BA_ "GenSigSendType" SG_ 1080 EDS_RunToDischaErr_FWD 0;
BA_ "GenSigSendType" SG_ 1080 EDS_12VOverVoltageAlarm_FWD 0;
BA_ "GenSigSendType" SG_ 1080 EDS_12VUnderVoltageAlarm_FWD 0;
BA_ "GenSigSendType" SG_ 1080 EDS_MotOverAlarm_FWD 0;
BA_ "GenSigSendType" SG_ 1080 EDS_MotOverFault_FWD 0;
BA_ "GenSigSendType" SG_ 1080 EDS_iDcLnkOvCLimFail_FWD 0;
BA_ "GenSigSendType" SG_ 1080 EDS_MotBlockedFault_FWD 0;
BA_ "GenSigSendType" SG_ 1080 EDS_RSLErr_FWD 0;
BA_ "GenSigSendType" SG_ 1080 EDS_MotTrqLimFault_FWD 0;
BA_ "GenSigSendType" SG_ 1080 EDS_ResolverOffsetAngle_FWD 0;
BA_ "GenSigSendType" SG_ 1080 EDS_EDSDisChgFault_FWD 0;
BA_ "GenSigSendType" SG_ 1080 EDS_IGBTFault_FWD 0;
BA_ "GenSigSendType" SG_ 1080 EDS_CANBusoffFault_FWD 0;
BA_ "GenSigSendType" SG_ 1080 EDS_TDrvBoardOvHiWarn_FWD 0;
BA_ "GenSigSendType" SG_ 1080 EDS_TIGBTOvHiFault_FWD 0;
BA_ "GenSigSendType" SG_ 1080 EDS_TIGBTOvHiWarn_FWD 0;
BA_ "GenSigSendType" SG_ 1080 EDS_IOHWABSampFail_FWD 0;
BA_ "GenSigSendType" SG_ 1080 EDS_EDSOpenFault_FWD 0;
BA_ "GenSigSendType" SG_ 1080 EDS_MotorOpenFault_FWD 0;
BA_ "GenSigSendType" SG_ 1080 EDS_EmacBlkdWarn_FWD 0;
BA_ "GenSigSendType" SG_ 1080 EDS_VerMatchFailureErr_FWD 0;
BA_ "GenSigSendType" SG_ 1080 EDS_DiashCirNoPsblErr_FWD 0;
BA_ "GenSigSendType" SG_ 1080 EDS_OperOutdRngErr_FWD 0;
BA_ "GenSigSendType" SG_ 1080 EDS_PhaseLossFaultErr_FWD 0;
BA_ "GenSigSendType" SG_ 1080 EDS_CPLDFault_FWD 0;
BA_ "GenSigSendType" SG_ 1080 EDS_CPLDFaultBaseSpd_FWD 0;
BA_ "GenSigSendType" SG_ 1080 EDS_IOHWABNen33Fail_FWD 0;
BA_ "GenSigSendType" SG_ 1080 EDS_HvMcuSlightFault_RWD 0;
BA_ "GenSigSendType" SG_ 1080 EDS_HvMcuSevFault_FWD 0;
BA_ "GenSigSendType" SG_ 1080 EDS_EDSPhaSampHWFault_FWD 0;
BA_ "GenSigSendType" SG_ 1080 EDS_IsOvHiErr_FWD 0;
BA_ "GenSigSendType" SG_ 1080 EDS_CanRollingCounterErr_FWD 0;
BA_ "GenSigSendType" SG_ 1080 EDS_CanTimeoutErr_FWD 0;
BA_ "GenSigSendType" SG_ 1080 EDS_CrashFault_FWD 0;
BA_ "GenSigSendType" SG_ 537 Checksum_0x219 0;
BA_ "GenSigSendType" SG_ 537 Rolling_Counter_0x219 0;
BA_ "GenSigInvalidValue" SG_ 537 Rolling_Counter_0x219 15;
BA_ "GenSigSendType" SG_ 537 VCU_VehicleDischargePower 0;
BA_ "GenSigInvalidValue" SG_ 537 VCU_VehicleDischargePower 127;
BA_ "GenSigSendType" SG_ 537 VCU_VehicleChargePower 0;
BA_ "GenSigInvalidValue" SG_ 537 VCU_VehicleChargePower 127;
BA_ "GenSigSendType" SG_ 537 VCU_ChargeAllow 0;
BA_ "GenSigSendType" SG_ 544 Checksum_0x220 0;
BA_ "GenSigSendType" SG_ 544 Rolling_Counter_0x220 0;
BA_ "GenSigInvalidValue" SG_ 544 Rolling_Counter_0x220 15;
BA_ "GenSigSendType" SG_ 544 VCU_BMS_PTCOnOff_Sts 0;
BA_ "GenSigSendType" SG_ 544 VCU_BMS_ValveOnOff_Sts 0;
BA_ "GenSigSendType" SG_ 544 VCU_BMS_PumpFB 0;
BA_ "GenSigSendType" SG_ 757 VCU_Charge_Control 0;
BA_ "GenSigSendType" SG_ 757 VCU_AC_chargeSock_temp1 0;
BA_ "GenSigInvalidValue" SG_ 757 VCU_AC_chargeSock_temp1 2047;
BA_ "GenSigSendType" SG_ 757 VCU_DC_chargeSock_temp1 0;
BA_ "GenSigInvalidValue" SG_ 757 VCU_DC_chargeSock_temp1 2047;
BA_ "GenSigSendType" SG_ 757 VCU_DC_chargeSock_temp2 0;
BA_ "GenSigInvalidValue" SG_ 757 VCU_DC_chargeSock_temp2 2047;
BA_ "GenSigSendType" SG_ 725 VCU_DCDC_Output_REQ 0;
BA_ "GenSigSendType" SG_ 725 VCU_DCDC_OutVoltage_REQ 0;
BA_ "GenSigInvalidValue" SG_ 725 VCU_DCDC_OutVoltage_REQ 511;
BA_ "GenSigSendType" SG_ 725 VCU_DCDCAllowedPower 0;
BA_ "GenSigInvalidValue" SG_ 725 VCU_DCDCAllowedPower 511;
BA_ "GenSigSendType" SG_ 553 Checksum_0x229 0;
BA_ "GenSigSendType" SG_ 553 Rolling_Counter_0x229 0;
BA_ "GenSigInvalidValue" SG_ 553 Rolling_Counter_0x229 15;
BA_ "GenSigSendType" SG_ 553 VCU_EDS_TargetTqMin_FWD 0;
BA_ "GenSigInvalidValue" SG_ 553 VCU_EDS_TargetTqMin_FWD 1023;
BA_ "GenSigStartValue" SG_ 553 VCU_EDS_TargetTqMin_FWD 500;
BA_ "GenSigSendType" SG_ 553 VCU_EDS_StsModeReq_FWD 0;
BA_ "GenSigInvalidValue" SG_ 553 VCU_EDS_StsModeReq_FWD 15;
BA_ "GenSigSendType" SG_ 553 VCU_EDS_demtrq_FWD 0;
BA_ "GenSigInvalidValue" SG_ 553 VCU_EDS_demtrq_FWD 4095;
BA_ "GenSigStartValue" SG_ 553 VCU_EDS_demtrq_FWD 1000;
BA_ "GenSigSendType" SG_ 553 VCU_EDS_demtrqValid_FWD 0;
BA_ "GenSigSendType" SG_ 553 VCU_EDS_TargetTqMax_FWD 0;
BA_ "GenSigInvalidValue" SG_ 553 VCU_EDS_TargetTqMax_FWD 1023;
BA_ "GenSigSendType" SG_ 553 VCU_EDS_CreepFlg_FWD 0;
BA_ "GenSigSendType" SG_ 553 VCU_EDS_HILLHoldFlg_FWD 0;
BA_ "GenSigSendType" SG_ 937 VCU_PTC_RelaySts 0;
BA_ "GenSigSendType" SG_ 937 VCU_EACEnbReq 0;
BA_ "GenSigSendType" SG_ 937 VCU_EACAllowedPower 0;
BA_ "GenSigInvalidValue" SG_ 937 VCU_EACAllowedPower 1023;
BA_ "GenSigSendType" SG_ 937 VCU_EAC_CompSpdReq 0;
BA_ "GenSigInvalidValue" SG_ 937 VCU_EAC_CompSpdReq 16383;
BA_ "GenSigSendType" SG_ 937 VCU_DriveCoolWaterFlowRate 0;
BA_ "GenSigSendType" SG_ 937 VCU_DriveCoolInletWaterTemp 0;
BA_ "GenSigSendType" SG_ 425 VCU_RegenLevel_Feed 0;
BA_ "GenSigStartValue" SG_ 425 VCU_RegenLevel_Feed 2;
BA_ "GenSigSendType" SG_ 425 VCU_RBCSts 0;
BA_ "GenSigSendType" SG_ 425 VCU_RDCSts 0;
BA_ "GenSigSendType" SG_ 425 VCU_Veh_ERR 0;
BA_ "GenSigSendType" SG_ 425 VCU_DrvSys_ERR 0;
BA_ "GenSigSendType" SG_ 425 VCU_PackSys_ERR 0;
BA_ "GenSigSendType" SG_ 425 VCU_TBOX_Veh_STS_Reserved 0;
BA_ "GenSigSendType" SG_ 425 VCU_VehChg_STS 0;
BA_ "GenSigSendType" SG_ 425 VCU_BatterVoltage_Reserved 0;
BA_ "GenSigInvalidValue" SG_ 425 VCU_BatterVoltage_Reserved 255;
BA_ "GenSigStartValue" SG_ 425 VCU_BatterVoltage_Reserved 171;
BA_ "GenSigSendType" SG_ 425 VCU_BatteryVoltErr_Reserved 0;
BA_ "GenSigSendType" SG_ 425 VCU_MotorCoolingCircuitErr_Reserved 0;
BA_ "GenSigSendType" SG_ 425 VCU_PackCoolingCircuitErr_Reserved 0;
BA_ "GenSigSendType" SG_ 425 VCU_VehicleHVStatus 0;
BA_ "GenSigInvalidValue" SG_ 425 VCU_VehicleHVStatus 3;
BA_ "GenSigSendType" SG_ 425 VCU_InstantPowerConsump 0;
BA_ "GenSigInvalidValue" SG_ 425 VCU_InstantPowerConsump 1023;
BA_ "GenSigSendType" SG_ 425 VCU_AveragePowerConsump 0;
BA_ "GenSigInvalidValue" SG_ 425 VCU_AveragePowerConsump 1023;
BA_ "GenSigSendType" SG_ 425 VCU_BrakePedalSts 0;
BA_ "GenSigSendType" SG_ 441 VCU_MCUConsumepower 0;
BA_ "GenSigSendType" SG_ 441 VCU_EACConsumepower 0;
BA_ "GenSigSendType" SG_ 441 VCU_DCDCConsumepower 0;
BA_ "GenSigSendType" SG_ 441 VCU_PTCConsumepower 0;
BA_ "GenSigSendType" SG_ 992 Checksum_0x3E0 0;
BA_ "GenSigSendType" SG_ 992 Rolling_Counter_0x3E0 0;
BA_ "GenSigInvalidValue" SG_ 992 Rolling_Counter_0x3E0 15;
BA_ "GenSigSendType" SG_ 992 VCU_RunningRange 0;
BA_ "GenSigSendType" SG_ 992 VCU_MHU_Ack_ChgSche_stt 0;
BA_ "GenSigSendType" SG_ 992 VCU_MHU_GuestMode_sts 0;
BA_ "GenSigSendType" SG_ 992 VCU_MHU_Ack_TargetSOC 0;
BA_ "GenSigStartValue" SG_ 992 VCU_MHU_Ack_TargetSOC 100;
BA_ "GenSigSendType" SG_ 992 VCU_ValetMode_sts 0;
BA_ "GenSigSendType" SG_ 992 VCU_ValetMode_MaxSpeedSts 0;
BA_ "GenSigInvalidValue" SG_ 992 VCU_ValetMode_MaxSpeedSts 2;
BA_ "GenSigInactiveValue" SG_ 992 VCU_ValetMode_MaxSpeedSts 255;
BA_ "GenSigSendType" SG_ 992 VCU_CreepDisable_stt 0;
BA_ "GenSigSendType" SG_ 409 Checksum_0x199 0;
BA_ "GenSigSendType" SG_ 409 Rolling_Counter_0x199 0;
BA_ "GenSigInvalidValue" SG_ 409 Rolling_Counter_0x199 15;
BA_ "GenSigSendType" SG_ 409 VCU_VehFailGrade_ERR 0;
BA_ "GenSigSendType" SG_ 409 VCU_BMS_HVOnOff_REQ 0;
BA_ "GenSigSendType" SG_ 409 VCU_Vehicle_Mode 0;
BA_ "GenSigSendType" SG_ 889 VCU_DriveCoolWaterPumpSts 0;
BA_ "GenSigSendType" SG_ 889 VCU_DriveCoolWaterDuty 0;
BA_ "GenSigInvalidValue" SG_ 889 VCU_DriveCoolWaterDuty 127;
BA_ "GenSigSendType" SG_ 889 VCU_BatteryWaterPumpSts_reserved 0;
BA_ "GenSigSendType" SG_ 889 VCU_BatteryWaterPumpDuty_reserved 0;
BA_ "GenSigInvalidValue" SG_ 889 VCU_BatteryWaterPumpDuty_reserved 127;
BA_ "GenSigSendType" SG_ 889 VCU_DriveMode 0;
BA_ "GenSigInvalidValue" SG_ 889 VCU_DriveMode 7;
BA_ "GenSigStartValue" SG_ 889 VCU_DriveMode 1;
BA_ "GenSigSendType" SG_ 889 VCU_ActualGear 0;
BA_ "GenSigInvalidValue" SG_ 889 VCU_ActualGear 7;
BA_ "GenSigStartValue" SG_ 889 VCU_ActualGear 2;
BA_ "GenSigSendType" SG_ 889 VCU_ACTGearValid 0;
BA_ "GenSigInvalidValue" SG_ 889 VCU_ACTGearValid 1;
BA_ "GenSigSendType" SG_ 889 VCU_AccPedal1OutRange 0;
BA_ "GenSigSendType" SG_ 889 VCU_AccPedal2OutRange 0;
BA_ "GenSigSendType" SG_ 889 VCU_BrkPedal1OutRange 0;
BA_ "GenSigSendType" SG_ 889 VCU_BrkPedal2OutRange 0;
BA_ "GenSigSendType" SG_ 889 VCU_BrkPedalPct 0;
BA_ "GenSigInvalidValue" SG_ 889 VCU_BrkPedalPct 255;
BA_ "GenSigSendType" SG_ 889 VCU_AccPedalPosition 0;
BA_ "GenSigInvalidValue" SG_ 889 VCU_AccPedalPosition 255;
BA_ "GenSigSendType" SG_ 889 VCU_AccPedalPositionValid 0;
BA_ "GenSigInvalidValue" SG_ 889 VCU_AccPedalPositionValid 1;
BA_ "GenSigStartValue" SG_ 889 VCU_AccPedalPositionValid 1;
BA_ "GenSigSendType" SG_ 889 VCU_SocDisplay_EST 0;
BA_ "GenSigInvalidValue" SG_ 889 VCU_SocDisplay_EST 127;
BA_ "GenSigSendType" SG_ 889 VCU_PowerLimit 0;
BA_ "GenSigSendType" SG_ 889 VCU_CruiseCtrlSts 0;
BA_ "GenSigSendType" SG_ 889 VCU_LowSOC_ERR 0;
BA_ "GenSigSendType" SG_ 905 VCU_FanControl_Sts 0;
BA_ "GenSigSendType" SG_ 905 VCU_HVACInletWateTemp 0;
BA_ "GenSigInvalidValue" SG_ 905 VCU_HVACInletWateTemp 255;
BA_ "GenSigStartValue" SG_ 905 VCU_HVACInletWateTemp 40;
BA_ "GenSigSendType" SG_ 905 VCU_IMMO_Sts 0;
BA_ "GenSigInvalidValue" SG_ 905 VCU_IMMO_Sts 2;
BA_ "GenSigSendType" SG_ 905 VCU_VacuumSts_reserved 0;
BA_ "GenSigInvalidValue" SG_ 905 VCU_VacuumSts_reserved 3;
BA_ "GenSigSendType" SG_ 905 VCU_VacuumPresWrn 0;
BA_ "GenSigInvalidValue" SG_ 905 VCU_VacuumPresWrn 3;
BA_ "GenSigSendType" SG_ 273 VCU_Sts 0;
BA_ "GenSigSendType" SG_ 1145 VCU_OtherFaultNum_Reserved 0;
BA_ "GenSigSendType" SG_ 1145 VCU_EDSCAN_ERR 0;
BA_ "GenSigSendType" SG_ 1145 VCU_BmsCAN_ERR 0;
BA_ "GenSigSendType" SG_ 1145 VCU_DcdcCAN_ERR 0;
BA_ "GenSigSendType" SG_ 1145 VCU_AbsCAN_ERR 0;
BA_ "GenSigSendType" SG_ 1145 VCU_AcmCAN_ERR 0;
BA_ "GenSigSendType" SG_ 1145 VCU_XgwCAN_ERR 0;
BA_ "GenSigSendType" SG_ 1145 VCU_ObcCAN_ERR 0;
BA_ "GenSigSendType" SG_ 1145 VCU_BcmCAN_ERR_reserved 0;
BA_ "GenSigSendType" SG_ 1145 VCU_WaterPump_ERR 0;
BA_ "GenSigSendType" SG_ 1145 VCU_BrakeSys_Err 0;
BA_ "GenSigSendType" SG_ 1145 VCU_PreChgFail_ERR_Reserved 0;
BA_ "GenSigSendType" SG_ 1145 VCU_LowBattery_ERR 0;
BA_ "GenSigSendType" SG_ 1145 VCU_AccPed_ERR 0;
BA_ "GenSigSendType" SG_ 1145 VCU_BrkPed_ERR 0;
BA_ "GenSigSendType" SG_ 1145 VCU_EPSCAN_ERR 0;
BA_ "GenSigSendType" SG_ 1145 VCU_PtcModu_ERR_Reserved 0;
BA_ "GenSigSendType" SG_ 1145 VCU_Shift_ERR 0;
BA_ "GenSigSendType" SG_ 1145 VCU_FlgHVIL_ERR 0;
BA_ "GenSigSendType" SG_ 1145 VCU_EKSCAN_ERR 0;
BA_ "GenSigSendType" SG_ 1145 VCU_VehLvInit_ERR_Reserved 0;
BA_ "GenSigSendType" SG_ 1145 VCU_EacCAN_ERR 0;
BA_ "GenSigSendType" SG_ 1145 VCU_EAC_CompFltStat_ERR 0;
BA_ "GenSigSendType" SG_ 745 Checksum_0x2E9 0;
BA_ "GenSigSendType" SG_ 745 Rolling_Counter_0x2E9 0;
BA_ "GenSigInvalidValue" SG_ 745 Rolling_Counter_0x2E9 15;
BA_ "GenSigSendType" SG_ 745 VCU_RemainingMileage 0;
BA_ "GenSigInvalidValue" SG_ 745 VCU_RemainingMileage 4294967295;
BA_ "GenSigSendType" SG_ 745 VCU_SetCruiseSpd 0;
BA_ "GenSigInvalidValue" SG_ 745 VCU_SetCruiseSpd 255;
BA_ "GenSigSendType" SG_ 792 EAC_CompElecCurrV 0;
BA_ "GenSigInvalidValue" SG_ 792 EAC_CompElecCurrV 1;
BA_ "GenSigSendType" SG_ 792 EAC_CompStat 0;
BA_ "GenSigInvalidValue" SG_ 792 EAC_CompStat 15;
BA_ "GenSigStartValue" SG_ 792 EAC_CompStat 2;
BA_ "GenSigSendType" SG_ 792 EAC_CompElecPwrV 0;
BA_ "GenSigInvalidValue" SG_ 792 EAC_CompElecPwrV 1;
BA_ "GenSigSendType" SG_ 792 EAC_CompSpdIncrReq 0;
BA_ "GenSigSendType" SG_ 792 EAC_CompSpdV 0;
BA_ "GenSigInvalidValue" SG_ 792 EAC_CompSpdV 1;
BA_ "GenSigSendType" SG_ 792 EAC_CompElecPwr 0;
BA_ "GenSigInvalidValue" SG_ 792 EAC_CompElecPwr 255;
BA_ "GenSigSendType" SG_ 792 EAC_CompSpd 0;
BA_ "GenSigInvalidValue" SG_ 792 EAC_CompSpd 16383;
BA_ "GenSigSendType" SG_ 792 EAC_CompElecCurr 0;
BA_ "GenSigInvalidValue" SG_ 792 EAC_CompElecCurr 255;
BA_ "GenSigSendType" SG_ 792 EAC_CompFltStat 0;
BA_ "GenSigInvalidValue" SG_ 792 EAC_CompFltStat 15;
BA_ "GenSigSendType" SG_ 793 EAC_CompPhaseCurr 0;
BA_ "GenSigInvalidValue" SG_ 793 EAC_CompPhaseCurr 255;
BA_ "GenSigSendType" SG_ 793 EAC_CompIGBTTempV 0;
BA_ "GenSigInvalidValue" SG_ 793 EAC_CompIGBTTempV 1;
BA_ "GenSigStartValue" SG_ 793 EAC_CompIGBTTempV 1;
BA_ "GenSigSendType" SG_ 793 EAC_CompHVInputV 0;
BA_ "GenSigInvalidValue" SG_ 793 EAC_CompHVInputV 1;
BA_ "GenSigStartValue" SG_ 793 EAC_CompHVInputV 1;
BA_ "GenSigSendType" SG_ 793 EAC_CompBoardTempV 0;
BA_ "GenSigInvalidValue" SG_ 793 EAC_CompBoardTempV 1;
BA_ "GenSigStartValue" SG_ 793 EAC_CompBoardTempV 1;
BA_ "GenSigSendType" SG_ 793 EAC_CompBoardTemp 0;
BA_ "GenSigInvalidValue" SG_ 793 EAC_CompBoardTemp 40;
BA_ "GenSigSendType" SG_ 793 EAC_CompHVInput 0;
BA_ "GenSigSendType" SG_ 793 EAC_CompIGBTTemp 0;
BA_ "GenSigInvalidValue" SG_ 793 EAC_CompIGBTTemp 40;
BA_ "GenSigSendType" SG_ 524 Checksum_0x20C 0;
BA_ "GenSigSendType" SG_ 524 Rolling_Counter_0x20C 0;
BA_ "GenSigInvalidValue" SG_ 524 Rolling_Counter_0x20C 15;
BA_ "GenSigSendType" SG_ 524 IPC_ODO 0;
BA_ "GenSigInvalidValue" SG_ 524 IPC_ODO 1048575;
BA_ "GenSigSendType" SG_ 703 IPC_TripA 0;
BA_ "GenSigInvalidValue" SG_ 703 IPC_TripA 65535;
BA_ "GenSigSendType" SG_ 703 IPC_AverageSpeedTripA 0;
BA_ "GenSigInvalidValue" SG_ 703 IPC_AverageSpeedTripA 4095;
BA_ "GenSigSendType" SG_ 703 IPC_AverageConsumptionTripA 0;
BA_ "GenSigInvalidValue" SG_ 703 IPC_AverageConsumptionTripA 1023;
BA_ "GenSigSendType" SG_ 703 IPC_ParkBrakeSts 0;
BA_ "GenSigInvalidValue" SG_ 703 IPC_ParkBrakeSts 3;
BA_ "GenSigSendType" SG_ 703 IPC_VehSpd 0;
BA_ "GenSigInvalidValue" SG_ 703 IPC_VehSpd 32767;
BA_ "GenSigSendType" SG_ 1087 IPC_Sec 0;
BA_ "GenSigInvalidValue" SG_ 1087 IPC_Sec 63;
BA_ "GenSigSendType" SG_ 1087 IPC_Min 0;
BA_ "GenSigInvalidValue" SG_ 1087 IPC_Min 63;
BA_ "GenSigSendType" SG_ 1087 IPC_Hour 0;
BA_ "GenSigInvalidValue" SG_ 1087 IPC_Hour 31;
BA_ "GenSigSendType" SG_ 1087 IPC_Day 0;
BA_ "GenSigInvalidValue" SG_ 1087 IPC_Day 31;
BA_ "GenSigStartValue" SG_ 1087 IPC_Day 1;
BA_ "GenSigSendType" SG_ 1087 IPC_Month 0;
BA_ "GenSigInvalidValue" SG_ 1087 IPC_Month 15;
BA_ "GenSigStartValue" SG_ 1087 IPC_Month 1;
BA_ "GenSigSendType" SG_ 1087 IPC_Year 0;
BA_ "GenSigInvalidValue" SG_ 1087 IPC_Year 255;
BA_ "GenSigSendType" SG_ 1087 IPC_SelfCheckStatus 0;
BA_ "GenSigSendType" SG_ 1074 Checksum_0x432 0;
BA_ "GenSigSendType" SG_ 1074 Rolling_Counter_0x432 0;
BA_ "GenSigInvalidValue" SG_ 1074 Rolling_Counter_0x432 15;
BA_ "GenSigSendType" SG_ 1074 MHU_FOTA_State 0;
BA_ "GenSigSendType" SG_ 1074 MHU_FOTA_Error_Code 0;
BA_ "GenSigSendType" SG_ 1027 Checksum_0x403 0;
BA_ "GenSigSendType" SG_ 1027 Rolling_Counter_0x403 0;
BA_ "GenSigInvalidValue" SG_ 1027 Rolling_Counter_0x403 15;
BA_ "GenSigSendType" SG_ 1027 MHU_SET_TCS_OnOff 2;
BA_ "GenSigInvalidValue" SG_ 1027 MHU_SET_TCS_OnOff 3;
BA_ "GenSigStartValue" SG_ 1027 MHU_SET_TCS_OnOff 2;
BA_ "GenSigSendType" SG_ 1027 MHU_SET_DrivingModeSwitch 2;
BA_ "GenSigSendType" SG_ 1027 MHU_SET_RegenLevel 2;
BA_ "GenSigStartValue" SG_ 1027 MHU_SET_RegenLevel 3;
BA_ "GenSigSendType" SG_ 1027 MHU_VCU_CreepDisable_stt 2;
BA_ "GenSigInvalidValue" SG_ 1027 MHU_VCU_CreepDisable_stt 3;
BA_ "GenSigStartValue" SG_ 1027 MHU_VCU_CreepDisable_stt 2;
BA_ "GenSigSendType" SG_ 1027 MHU_ChargeSetTargetSOC 2;
BA_ "GenSigInvalidValue" SG_ 1027 MHU_ChargeSetTargetSOC 127;
BA_ "GenSigStartValue" SG_ 1027 MHU_ChargeSetTargetSOC 100;
BA_ "GenSigSendType" SG_ 1027 MHU_HVACTurnON 2;
BA_ "GenSigInvalidValue" SG_ 1027 MHU_HVACTurnON 3;
BA_ "GenSigSendType" SG_ 1027 MHU_ChargeScheduleSet 2;
BA_ "GenSigStartValue" SG_ 1027 MHU_ChargeScheduleSet 2;
BA_ "GenSigSendType" SG_ 1027 MHU_ChargingRequest 2;
BA_ "GenSigStartValue" SG_ 1027 MHU_ChargingRequest 3;
BA_ "GenSigSendType" SG_ 1027 MHU_ValetMode_Activation 2;
BA_ "GenSigInvalidValue" SG_ 1027 MHU_ValetMode_Activation 254;
BA_ "GenSigInactiveValue" SG_ 1027 MHU_ValetMode_Activation 255;
BA_ "GenSigSendType" SG_ 1027 MHU_ValetMode_MaxSpeed 2;
BA_ "GenSigInvalidValue" SG_ 1027 MHU_ValetMode_MaxSpeed 2;
BA_ "GenSigInactiveValue" SG_ 1027 MHU_ValetMode_MaxSpeed 255;
BA_ "GenSigSendType" SG_ 811 CCU_TemperatureGearSts 0;
BA_ "GenSigInvalidValue" SG_ 811 CCU_TemperatureGearSts 63;
BA_ "GenSigStartValue" SG_ 811 CCU_TemperatureGearSts 7;
BA_ "GenSigSendType" SG_ 811 CCU_BlowMode_Sts 0;
BA_ "GenSigInvalidValue" SG_ 811 CCU_BlowMode_Sts 7;
BA_ "GenSigStartValue" SG_ 811 CCU_BlowMode_Sts 2;
BA_ "GenSigSendType" SG_ 811 CCU_Circulation_Sts 0;
BA_ "GenSigSendType" SG_ 811 CCU_AC_Req 0;
BA_ "GenSigInvalidValue" SG_ 811 CCU_AC_Req 3;
BA_ "GenSigSendType" SG_ 811 CCU_AC_Sts 0;
BA_ "GenSigSendType" SG_ 811 CCU_BlowerLevelSts 0;
BA_ "GenSigStartValue" SG_ 811 CCU_BlowerLevelSts 1;
BA_ "GenSigSendType" SG_ 811 CCU_FrontDefrostSts 0;
BA_ "GenSigSendType" SG_ 811 CCU_PTC_Req 0;
BA_ "GenSigInvalidValue" SG_ 811 CCU_PTC_Req 3;
BA_ "GenSigSendType" SG_ 811 CCU_PTC_Temperature 0;
BA_ "GenSigInvalidValue" SG_ 811 CCU_PTC_Temperature 1023;
BA_ "GenSigSendType" SG_ 811 CCU_CompSpdMEAS_Comp 0;
BA_ "GenSigInvalidValue" SG_ 811 CCU_CompSpdMEAS_Comp 8191;
BA_ "GenSigSendType" SG_ 811 CCU_PollutionSts 0;
BA_ "GenSigSendType" SG_ 811 CCU_ExternalTemperature 0;
BA_ "GenSigInvalidValue" SG_ 811 CCU_ExternalTemperature 255;
BA_ "GenSigStartValue" SG_ 811 CCU_ExternalTemperature 80;
BA_ "GenSigSendType" SG_ 811 CCU_evaporator_Temperature 0;
BA_ "GenSigInvalidValue" SG_ 811 CCU_evaporator_Temperature 31;
BA_ "GenSigStartValue" SG_ 811 CCU_evaporator_Temperature 10;
BA_ "GenSigSendType" SG_ 811 CCU_ExternalTemperatureFailSts 0;
BA_ "GenSigInvalidValue" SG_ 811 CCU_ExternalTemperatureFailSts 1;
BA_ "GenSigStartValue" SG_ 811 CCU_ExternalTemperatureFailSts 1;
BA_ "GenSigSendType" SG_ 1015 MFS_OK_Control 4;
BA_ "GenSigSendType" SG_ 1015 MFS_SourseControl 4;
BA_ "GenSigSendType" SG_ 1015 MFS_VoiceRecognitionOn_Off 4;
BA_ "GenSigSendType" SG_ 1015 MFS_TelephoneCall_EndCall 4;
BA_ "GenSigSendType" SG_ 1015 MFS_DownControl 4;
BA_ "GenSigSendType" SG_ 1015 MFS_UpControl 4;
BA_ "GenSigSendType" SG_ 1015 MFS_RightControl 4;
BA_ "GenSigSendType" SG_ 1015 MFS_LeftControl 4;
BA_ "GenSigSendType" SG_ 1015 MFS_CruiseOn_Off 4;
BA_ "GenSigSendType" SG_ 1015 MFS_Failure 4;
BA_ "GenSigSendType" SG_ 1015 MFS_ISAControl 4;
BA_ "GenSigSendType" SG_ 1015 MFS_LKAControl 4;
BA_ "GenSigSendType" SG_ 1015 MFS_CruiseGapDecrease 4;
BA_ "GenSigSendType" SG_ 1015 MFS_CruiseSpeedDecrease 4;
BA_ "GenSigSendType" SG_ 1015 MFS_CruiseSpeedIncrease 4;
BA_ "GenSigSendType" SG_ 1015 MFS_CruiseCancel 4;
BA_ "GenSigSendType" SG_ 1015 MFS_CruiseGapIncrease 4;
BA_ "GenSigSendType" SG_ 920 BCM_Immo_Byte_0 1;
BA_ "GenSigSendType" SG_ 920 BCM_Immo_Byte_1 1;
BA_ "GenSigSendType" SG_ 920 BCM_Immo_Byte_2 1;
BA_ "GenSigSendType" SG_ 920 BCM_Immo_Byte_3 1;
BA_ "GenSigSendType" SG_ 920 BCM_Immo_Byte_4 1;
BA_ "GenSigSendType" SG_ 920 BCM_Immo_Byte_5 1;
BA_ "GenSigSendType" SG_ 920 BCM_Immo_Byte_6 1;
BA_ "GenSigSendType" SG_ 920 BCM_Immo_Byte_7 1;
BA_ "GenSigSendType" SG_ 921 VCU_Immo_Byte_0 1;
BA_ "GenSigSendType" SG_ 921 VCU_Immo_Byte_1 1;
BA_ "GenSigSendType" SG_ 921 VCU_Immo_Byte_2 1;
BA_ "GenSigSendType" SG_ 921 VCU_Immo_Byte_3 1;
BA_ "GenSigSendType" SG_ 921 VCU_Immo_Byte_4 1;
BA_ "GenSigSendType" SG_ 921 VCU_Immo_Byte_5 1;
BA_ "GenSigSendType" SG_ 921 VCU_Immo_Byte_6 1;
BA_ "GenSigSendType" SG_ 921 VCU_Immo_Byte_7 1;
BA_ "GenSigSendType" SG_ 929 BMS_MHU_Rand_Num_Byte_0 1;
BA_ "GenSigSendType" SG_ 929 BMS_MHU_Rand_Num_Byte_1 1;
BA_ "GenSigSendType" SG_ 929 BMS_MHU_Rand_Num_Byte_2 1;
BA_ "GenSigSendType" SG_ 929 BMS_MHU_Rand_Num_Byte_3 1;
BA_ "GenSigSendType" SG_ 929 BMS_MHU_Rand_Num_Byte_4 1;
BA_ "GenSigSendType" SG_ 929 BMS_MHU_Rand_Num_Byte_5 1;
BA_ "GenSigSendType" SG_ 929 BMS_MHU_Rand_Num_Byte_6 1;
BA_ "GenSigSendType" SG_ 929 BMS_MHU_Rand_Num_Byte_7 1;
BA_ "GenSigSendType" SG_ 930 MHU_BMS_Enc_Result_Byte_0 1;
BA_ "GenSigSendType" SG_ 930 MHU_BMS_Enc_Result_Byte_1 1;
BA_ "GenSigSendType" SG_ 930 MHU_BMS_Enc_Result_Byte_2 1;
BA_ "GenSigSendType" SG_ 930 MHU_BMS_Enc_Result_Byte_3 1;
BA_ "GenSigSendType" SG_ 930 MHU_BMS_Enc_Result_Byte_4 1;
BA_ "GenSigSendType" SG_ 930 MHU_BMS_Enc_Result_Byte_5 1;
BA_ "GenSigSendType" SG_ 930 MHU_BMS_Enc_Result_Byte_6 1;
BA_ "GenSigSendType" SG_ 930 MHU_BMS_Enc_Result_Byte_7 1;
BA_ "GenSigSendType" SG_ 274 Checksum_0x112 0;
BA_ "GenSigSendType" SG_ 274 Rolling_Counter_0x112 0;
BA_ "GenSigInvalidValue" SG_ 274 Rolling_Counter_0x112 15;
BA_ "GenSigSendType" SG_ 274 STAT_Terminal 0;
BA_ "GenSigSendType" SG_ 274 STAT_CL30s_L_Reserved 0;
BA_ "GenSigStartValue" SG_ 274 STAT_CL30s_L_Reserved 3;
BA_ "GenSigSendType" SG_ 976 BCM_STAT_DoorAjarDriver 0;
BA_ "GenSigSendType" SG_ 976 STAT_DoorLockDriver 0;
BA_ "GenSigSendType" SG_ 283 BCM_ACCRelayOutputSts 0;
BA_ "GenSigSendType" SG_ 283 BCM_IGN1RelayOutputSts 0;
BA_ "GenSigSendType" SG_ 283 BCM_ACCRelayFalutSts 0;
BA_ "GenSigSendType" SG_ 283 BCM_IGN1RelayFalutSts 0;
BA_ "GenSigSendType" SG_ 283 BCM_KEY_MatchSts 0;
BA_ "GenSigSendType" SG_ 266 Checksum_0x10a 0;
BA_ "GenSigSendType" SG_ 266 Rolling_Counter_0x10a 0;
BA_ "GenSigInvalidValue" SG_ 266 Rolling_Counter_0x10a 15;
BA_ "GenSigSendType" SG_ 266 BCM_LVTop_up 0;
BA_ "GenSigSendType" SG_ 266 Ubatt_Reserved 0;
BA_ "GenSigInvalidValue" SG_ 266 Ubatt_Reserved 16383;
BA_ "GenSigStartValue" SG_ 266 Ubatt_Reserved 9000;
BA_ "GenSigSendType" SG_ 769 VOD_Block 0;
BA_ "GenSigSendType" SG_ 769 VOD_UpdateFlag 0;
BA_ "GenSigSendType" SG_ 769 VOD_Byte1 0;
BA_ "GenSigStartValue" SG_ 769 VOD_Byte1 255;
BA_ "GenSigSendType" SG_ 769 VOD_Byte2 0;
BA_ "GenSigStartValue" SG_ 769 VOD_Byte2 255;
BA_ "GenSigSendType" SG_ 769 VOD_Byte3 0;
BA_ "GenSigStartValue" SG_ 769 VOD_Byte3 255;
BA_ "GenSigSendType" SG_ 769 VOD_Byte4 0;
BA_ "GenSigStartValue" SG_ 769 VOD_Byte4 255;
BA_ "GenSigSendType" SG_ 769 VOD_Byte5 0;
BA_ "GenSigStartValue" SG_ 769 VOD_Byte5 255;
BA_ "GenSigSendType" SG_ 769 VOD_Byte6 0;
BA_ "GenSigStartValue" SG_ 769 VOD_Byte6 255;
BA_ "GenSigSendType" SG_ 769 VOD_Byte7 0;
BA_ "GenSigStartValue" SG_ 769 VOD_Byte7 255;
BA_ "GenSigSendType" SG_ 133 Checksum_0x85 0;
BA_ "GenSigSendType" SG_ 133 Rolling_Counter_0x85 0;
BA_ "GenSigInvalidValue" SG_ 133 Rolling_Counter_0x85 15;
BA_ "GenSigSendType" SG_ 133 ACM_Crash_Sts 0;
BA_ "GenSigSendType" SG_ 133 ACM_Airbag_Deployment_Status 0;
BA_ "GenSigSendType" SG_ 133 ACM_Crash_Intensity 0;
BA_ "GenSigSendType" SG_ 133 ACM_Front_Crash 0;
BA_ "GenSigSendType" SG_ 133 ACM_DriverSide_Crash 0;
BA_ "GenSigSendType" SG_ 133 ACM_PassSide_Crash 0;
BA_ "GenSigSendType" SG_ 133 ACM_Rear_Crash 0;
BA_ "GenSigSendType" SG_ 133 ACM_Rollover_Crash 0;
BA_ "GenSigSendType" SG_ 834 Checksum_0x342 0;
BA_ "GenSigSendType" SG_ 834 Rolling_Counter_0x342 0;
BA_ "GenSigInvalidValue" SG_ 834 Rolling_Counter_0x342 15;
BA_ "GenSigSendType" SG_ 834 ABS_LRWhlSpdRaw 0;
BA_ "GenSigInvalidValue" SG_ 834 ABS_LRWhlSpdRaw 32767;
BA_ "GenSigSendType" SG_ 834 ABS_LRWhlSpdRawValid 0;
BA_ "GenSigSendType" SG_ 834 ABS_RRWhlSpdRaw 0;
BA_ "GenSigInvalidValue" SG_ 834 ABS_RRWhlSpdRaw 32767;
BA_ "GenSigSendType" SG_ 834 ABS_RRWhlSpdRawValid 0;
BA_ "GenSigSendType" SG_ 834 ABS_VehSpd 0;
BA_ "GenSigInvalidValue" SG_ 834 ABS_VehSpd 32767;
BA_ "GenSigSendType" SG_ 834 ABS_VehSpdValid 0;
BA_ "GenSigSendType" SG_ 149 Checksum_0x95 0;
BA_ "GenSigSendType" SG_ 149 RollingCounter_0x95 0;
BA_ "GenSigInvalidValue" SG_ 149 RollingCounter_0x95 15;
BA_ "GenSigSendType" SG_ 149 ABS_Active 0;
BA_ "GenSigInvalidValue" SG_ 149 ABS_Active 3;
BA_ "GenSigSendType" SG_ 149 ASR_Active 0;
BA_ "GenSigInvalidValue" SG_ 149 ASR_Active 3;
BA_ "GenSigSendType" SG_ 1299 BMS_sourceID 0;
BA_ "GenSigSendType" SG_ 1299 BMS_CBV 0;
BA_ "GenSigSendType" SG_ 1299 BMS_Data0 0;
BA_ "GenSigSendType" SG_ 1299 BMS_Data1 0;
BA_ "GenSigSendType" SG_ 1299 BMS_Data2 0;
BA_ "GenSigSendType" SG_ 1299 BMS_Data3 0;
BA_ "GenSigSendType" SG_ 1299 BMS_Data4 0;
BA_ "GenSigSendType" SG_ 1299 BMS_Data5 0;
BA_ "GenSigSendType" SG_ 1324 VCU_sourceID 0;
BA_ "GenSigSendType" SG_ 1324 VCU_CBV 0;
BA_ "GenSigSendType" SG_ 1324 VCU_Data0 0;
BA_ "GenSigSendType" SG_ 1324 VCU_Data1 0;
BA_ "GenSigSendType" SG_ 1324 VCU_Data2 0;
BA_ "GenSigSendType" SG_ 1324 VCU_Data3 0;
BA_ "GenSigSendType" SG_ 1324 VCU_Data4 0;
BA_ "GenSigSendType" SG_ 1324 VCU_Data5 0;
BA_ "GenSigSendType" SG_ 1341 PDU_DCDC_sourceID 0;
BA_ "GenSigSendType" SG_ 1341 PDU_DCDC_CBV 0;
BA_ "GenSigSendType" SG_ 1341 PDU_DCDC_Data0 0;
BA_ "GenSigSendType" SG_ 1341 PDU_DCDC_Data1 0;
BA_ "GenSigSendType" SG_ 1341 PDU_DCDC_Data2 0;
BA_ "GenSigSendType" SG_ 1341 PDU_DCDC_Data3 0;
BA_ "GenSigSendType" SG_ 1341 PDU_DCDC_Data4 0;
BA_ "GenSigSendType" SG_ 1341 PDU_DCDC_Data5 0;
BA_ "GenSigSendType" SG_ 1307 EDS_sourceID 0;
BA_ "GenSigSendType" SG_ 1307 EDS_CBV 0;
BA_ "GenSigSendType" SG_ 1307 EDS_Data0 0;
BA_ "GenSigSendType" SG_ 1307 EDS_Data1 0;
BA_ "GenSigSendType" SG_ 1307 EDS_Data2 0;
BA_ "GenSigSendType" SG_ 1307 EDS_Data3 0;
BA_ "GenSigSendType" SG_ 1307 EDS_Data4 0;
BA_ "GenSigSendType" SG_ 1307 EDS_Data5 0;
BA_ "GenSigSendType" SG_ 1311 EVCC_sourceID 0;
BA_ "GenSigSendType" SG_ 1311 EVCC_CBV 0;
BA_ "GenSigSendType" SG_ 1311 EVCC_Data0 0;
BA_ "GenSigSendType" SG_ 1311 EVCC_Data1 0;
BA_ "GenSigSendType" SG_ 1311 EVCC_Data2 0;
BA_ "GenSigSendType" SG_ 1311 EVCC_Data3 0;
BA_ "GenSigSendType" SG_ 1311 EVCC_Data4 0;
BA_ "GenSigSendType" SG_ 1311 EVCC_Data5 0;
BA_ "GenSigSendType" SG_ 1282 GW_sourceID 0;
BA_ "GenSigSendType" SG_ 1282 GW_CBV 0;
BA_ "GenSigSendType" SG_ 1282 GW_Data0 0;
BA_ "GenSigSendType" SG_ 1282 GW_Data1 0;
BA_ "GenSigSendType" SG_ 1282 GW_Data2 0;
BA_ "GenSigSendType" SG_ 1282 GW_Data3 0;
BA_ "GenSigSendType" SG_ 1282 GW_Data4 0;
BA_ "GenSigSendType" SG_ 1282 GW_Data5 0;
BA_ "GenSigSendType" SG_ 1683 BMS_DiagReqData0 0;
BA_ "GenSigSendType" SG_ 1683 BMS_DiagReqData1 0;
BA_ "GenSigSendType" SG_ 1683 BMS_DiagReqData2 0;
BA_ "GenSigSendType" SG_ 1683 BMS_DiagReqData3 0;
BA_ "GenSigSendType" SG_ 1683 BMS_DiagReqData4 0;
BA_ "GenSigSendType" SG_ 1683 BMS_DiagReqData5 0;
BA_ "GenSigSendType" SG_ 1683 BMS_DiagReqData6 0;
BA_ "GenSigSendType" SG_ 1683 BMS_DiagReqData7 0;
BA_ "GenSigSendType" SG_ 1555 BMS_DiagRespData0 0;
BA_ "GenSigSendType" SG_ 1555 BMS_DiagRespData1 0;
BA_ "GenSigSendType" SG_ 1555 BMS_DiagRespData2 0;
BA_ "GenSigSendType" SG_ 1555 BMS_DiagRespData3 0;
BA_ "GenSigSendType" SG_ 1555 BMS_DiagRespData4 0;
BA_ "GenSigSendType" SG_ 1555 BMS_DiagRespData5 0;
BA_ "GenSigSendType" SG_ 1555 BMS_DiagRespData6 0;
BA_ "GenSigSendType" SG_ 1555 BMS_DiagRespData7 0;
BA_ "GenSigSendType" SG_ 1708 VCU_DiagReqData0 0;
BA_ "GenSigSendType" SG_ 1708 VCU_DiagReqData1 0;
BA_ "GenSigSendType" SG_ 1708 VCU_DiagReqData2 0;
BA_ "GenSigSendType" SG_ 1708 VCU_DiagReqData3 0;
BA_ "GenSigSendType" SG_ 1708 VCU_DiagReqData4 0;
BA_ "GenSigSendType" SG_ 1708 VCU_DiagReqData5 0;
BA_ "GenSigSendType" SG_ 1708 VCU_DiagReqData6 0;
BA_ "GenSigSendType" SG_ 1708 VCU_DiagReqData7 0;
BA_ "GenSigSendType" SG_ 1580 VCU_DiagRespData0 0;
BA_ "GenSigSendType" SG_ 1580 VCU_DiagRespData1 0;
BA_ "GenSigSendType" SG_ 1580 VCU_DiagRespData2 0;
BA_ "GenSigSendType" SG_ 1580 VCU_DiagRespData3 0;
BA_ "GenSigSendType" SG_ 1580 VCU_DiagRespData4 0;
BA_ "GenSigSendType" SG_ 1580 VCU_DiagRespData5 0;
BA_ "GenSigSendType" SG_ 1580 VCU_DiagRespData6 0;
BA_ "GenSigSendType" SG_ 1580 VCU_DiagRespData7 0;
BA_ "GenSigSendType" SG_ 1725 PDU_DiagReqData0 0;
BA_ "GenSigSendType" SG_ 1725 PDU_DiagReqData1 0;
BA_ "GenSigSendType" SG_ 1725 PDU_DiagReqData2 0;
BA_ "GenSigSendType" SG_ 1725 PDU_DiagReqData3 0;
BA_ "GenSigSendType" SG_ 1725 PDU_DiagReqData4 0;
BA_ "GenSigSendType" SG_ 1725 PDU_DiagReqData5 0;
BA_ "GenSigSendType" SG_ 1725 PDU_DiagReqData6 0;
BA_ "GenSigSendType" SG_ 1725 PDU_DiagReqData7 0;
BA_ "GenSigSendType" SG_ 1597 PDU_DiagRespData0 0;
BA_ "GenSigSendType" SG_ 1597 PDU_DiagRespData1 0;
BA_ "GenSigSendType" SG_ 1597 PDU_DiagRespData2 0;
BA_ "GenSigSendType" SG_ 1597 PDU_DiagRespData3 0;
BA_ "GenSigSendType" SG_ 1597 PDU_DiagRespData4 0;
BA_ "GenSigSendType" SG_ 1597 PDU_DiagRespData5 0;
BA_ "GenSigSendType" SG_ 1597 PDU_DiagRespData6 0;
BA_ "GenSigSendType" SG_ 1597 PDU_DiagRespData7 0;
BA_ "GenSigSendType" SG_ 1691 EDS_DiagReqData0 0;
BA_ "GenSigSendType" SG_ 1691 EDS_DiagReqData1 0;
BA_ "GenSigSendType" SG_ 1691 EDS_DiagReqData2 0;
BA_ "GenSigSendType" SG_ 1691 EDS_DiagReqData3 0;
BA_ "GenSigSendType" SG_ 1691 EDS_DiagReqData4 0;
BA_ "GenSigSendType" SG_ 1691 EDS_DiagReqData5 0;
BA_ "GenSigSendType" SG_ 1691 EDS_DiagReqData6 0;
BA_ "GenSigSendType" SG_ 1691 EDS_DiagReqData7 0;
BA_ "GenSigSendType" SG_ 1563 EDS_DiagRespData0 0;
BA_ "GenSigSendType" SG_ 1563 EDS_DiagRespData1 0;
BA_ "GenSigSendType" SG_ 1563 EDS_DiagRespData2 0;
BA_ "GenSigSendType" SG_ 1563 EDS_DiagRespData3 0;
BA_ "GenSigSendType" SG_ 1563 EDS_DiagRespData4 0;
BA_ "GenSigSendType" SG_ 1563 EDS_DiagRespData5 0;
BA_ "GenSigSendType" SG_ 1563 EDS_DiagRespData6 0;
BA_ "GenSigSendType" SG_ 1563 EDS_DiagRespData7 0;
BA_ "GenSigSendType" SG_ 1781 EAC_DiagReqData0 0;
BA_ "GenSigSendType" SG_ 1781 EAC_DiagReqData1 0;
BA_ "GenSigSendType" SG_ 1781 EAC_DiagReqData2 0;
BA_ "GenSigSendType" SG_ 1781 EAC_DiagReqData3 0;
BA_ "GenSigSendType" SG_ 1781 EAC_DiagReqData4 0;
BA_ "GenSigSendType" SG_ 1781 EAC_DiagReqData5 0;
BA_ "GenSigSendType" SG_ 1781 EAC_DiagReqData6 0;
BA_ "GenSigSendType" SG_ 1781 EAC_DiagReqData7 0;
BA_ "GenSigSendType" SG_ 1653 EAC_DiagRespData0 0;
BA_ "GenSigSendType" SG_ 1653 EAC_DiagRespData1 0;
BA_ "GenSigSendType" SG_ 1653 EAC_DiagRespData2 0;
BA_ "GenSigSendType" SG_ 1653 EAC_DiagRespData3 0;
BA_ "GenSigSendType" SG_ 1653 EAC_DiagRespData4 0;
BA_ "GenSigSendType" SG_ 1653 EAC_DiagRespData5 0;
BA_ "GenSigSendType" SG_ 1653 EAC_DiagRespData6 0;
BA_ "GenSigSendType" SG_ 1653 EAC_DiagRespData7 0;
BA_ "GenSigSendType" SG_ 1695 EVCC_DiagReqData0 0;
BA_ "GenSigSendType" SG_ 1695 EVCC_DiagReqData1 0;
BA_ "GenSigSendType" SG_ 1695 EVCC_DiagReqData2 0;
BA_ "GenSigSendType" SG_ 1695 EVCC_DiagReqData3 0;
BA_ "GenSigSendType" SG_ 1695 EVCC_DiagReqData4 0;
BA_ "GenSigSendType" SG_ 1695 EVCC_DiagReqData5 0;
BA_ "GenSigSendType" SG_ 1695 EVCC_DiagReqData6 0;
BA_ "GenSigSendType" SG_ 1695 EVCC_DiagReqData7 0;
BA_ "GenSigSendType" SG_ 1567 EVCC_DiagRespData0 0;
BA_ "GenSigSendType" SG_ 1567 EVCC_DiagRespData1 0;
BA_ "GenSigSendType" SG_ 1567 EVCC_DiagRespData2 0;
BA_ "GenSigSendType" SG_ 1567 EVCC_DiagRespData3 0;
BA_ "GenSigSendType" SG_ 1567 EVCC_DiagRespData4 0;
BA_ "GenSigSendType" SG_ 1567 EVCC_DiagRespData5 0;
BA_ "GenSigSendType" SG_ 1567 EVCC_DiagRespData6 0;
BA_ "GenSigSendType" SG_ 1567 EVCC_DiagRespData7 0;
BA_ "GenSigSendType" SG_ 1791 GW_DiagFunctionalAddressingData0 0;
BA_ "GenSigSendType" SG_ 1791 GW_DiagFunctionalAddressingData1 0;
BA_ "GenSigSendType" SG_ 1791 GW_DiagFunctionalAddressingData2 0;
BA_ "GenSigSendType" SG_ 1791 GW_DiagFunctionalAddressingData3 0;
BA_ "GenSigSendType" SG_ 1791 GW_DiagFunctionalAddressingData4 0;
BA_ "GenSigSendType" SG_ 1791 GW_DiagFunctionalAddressingData5 0;
BA_ "GenSigSendType" SG_ 1791 GW_DiagFunctionalAddressingData6 0;
BA_ "GenSigSendType" SG_ 1791 GW_DiagFunctionalAddressingData7 0;
VAL_ 504 Rolling_Counter_0x1F8 15 "Invalid";
VAL_ 504 EDS_output_trq_FR 65535 "Invalid";
VAL_ 504 EDS_output_trqValid_FR 1 "valid" 0 "invalid";
VAL_ 504 EDS_Spd_FR 65535 "Invalid";
VAL_ 504 EDS_SpdValid_FR 1 "valid" 0 "invalid";
VAL_ 504 EDS_MotorDriveSts_FR 3 "Invaild" 2 "regen control" 1 "Drive control" 0 "Zero control";
VAL_ 504 EDS_Work_STS_FR 15 "invaild" 14 "power off" 13 "Failure" 12 "after run" 11 "shut down" 5 "HVReady" 4 "normal" 3 "precharge" 2 "standby" 1 "init" 0 "default";
VAL_ 504 EDS_powoff_req_FR 1 "(Request high voltage power down)" 0 "(No request)";
VAL_ 680 Rolling_Counter_0x2A8 15 "Invalid";
VAL_ 680 EDS_MotorSerialNum_FWD 0 "Invalid";
VAL_ 680 EDS_MinTrq_FWD 65535 "Invalid";
VAL_ 680 EDS_MaxTrq_FWD 65535 "Invalid";
VAL_ 568 EDS_MotTemp_MEAS_EDS_FWD 255 "Invalid";
VAL_ 568 EDS_MotTemp_MEAS_EDS_valid_FWD 1 "valid" 0 "invalid";
VAL_ 568 EDS_temp_FWD 255 "Invalid";
VAL_ 568 EDS_tempValid_FWD 1 "valid" 0 "invalid";
VAL_ 568 EDS_disxhg_st_FWD 3 "Finished Active Discharge" 2 "Failed Active Discharge" 1 "Active Discharge" 0 "No Active Discharge";
VAL_ 568 EDS_IGBTState_FWD 0 "FreeWheel" 1 "Up Bridge ASC" 2 "Down Bridge ASC" 3 "Normal Run";
VAL_ 568 EDS_DampingState_FWD 0 "Damping disable" 1 "Damping active";
VAL_ 568 EDS_CoolFlowrate_DMD_FWD 255 "Invalid";
VAL_ 1080 EDS_FailGrade_ERR_FWD 7 "Invaild" 6 "Invaild" 5 "Fifth Fault,Delayed power off" 4 "Forth Fault,ZeroTorque" 3 "Third Fault,Limp" 2 "Second Fault，Limited power" 1 "First-Level warning" 0 "No fault";
VAL_ 1080 EDS_MotOverTempAlarm_FWD 1 "Error" 0 "Normal";
VAL_ 1080 EDS_MotOverTempFault_FWD 1 "Error" 0 "Normal";
VAL_ 1080 EDS_MotTempSenFault_FWD 1 "Error" 0 "Normal";
VAL_ 1080 EDS_EDSOverTempUFault_FWD 1 "Error" 0 "Normal";
VAL_ 1080 EDS_EDSOverTempVFault_FWD 1 "Error" 0 "Normal";
VAL_ 1080 EDS_EDSOverTempWFault_FWD 1 "Error" 0 "Normal";
VAL_ 1080 EDS_EDSOverTempAlarm_FWD 1 "Error" 0 "Normal";
VAL_ 1080 EDS_TCoolantOvHi_FWD 1 "Error" 0 "Normal";
VAL_ 1080 EDS_EDSTempCmpAlarm_FWD 1 "Error" 0 "Normal";
VAL_ 1080 EDS_EDSPhaOvCurentHWFault_FWD 1 "Error" 0 "Normal";
VAL_ 1080 EDS_EDSphaOffCalFault_FWD 1 "Error" 0 "Normal";
VAL_ 1080 EDS_EDSOverIdcLnkAlarm_FWD 1 "Error" 0 "Normal";
VAL_ 1080 EDS_EDSHVOverVoltageAlarm_FWD 1 "Error" 0 "Normal";
VAL_ 1080 EDS_EDSHVOverVoltageFault_FWD 1 "Error" 0 "Normal";
VAL_ 1080 EDS_EDSHVUnderVoltageAlarm_FWD 1 "Error" 0 "Normal";
VAL_ 1080 EDS_EDSHVUnderVoltageFault_FWD 1 "Error" 0 "Normal";
VAL_ 1080 EDS_RunToDischaErr_FWD 1 "Error" 0 "Normal";
VAL_ 1080 EDS_12VOverVoltageAlarm_FWD 1 "Error" 0 "Normal";
VAL_ 1080 EDS_12VUnderVoltageAlarm_FWD 1 "Error" 0 "Normal";
VAL_ 1080 EDS_MotOverAlarm_FWD 1 "Error" 0 "Normal";
VAL_ 1080 EDS_MotOverFault_FWD 1 "Error" 0 "Normal";
VAL_ 1080 EDS_iDcLnkOvCLimFail_FWD 1 "Error" 0 "Normal";
VAL_ 1080 EDS_MotBlockedFault_FWD 1 "Error" 0 "Normal";
VAL_ 1080 EDS_RSLErr_FWD 1 "Error" 0 "Normal";
VAL_ 1080 EDS_MotTrqLimFault_FWD 1 "Error" 0 "Normal";
VAL_ 1080 EDS_ResolverOffsetAngle_FWD 1 "Error" 0 "Normal";
VAL_ 1080 EDS_EDSDisChgFault_FWD 1 "Error" 0 "Normal";
VAL_ 1080 EDS_IGBTFault_FWD 1 "Error" 0 "Normal";
VAL_ 1080 EDS_CANBusoffFault_FWD 1 "Error" 0 "Normal";
VAL_ 1080 EDS_TDrvBoardOvHiWarn_FWD 1 "Error" 0 "Normal";
VAL_ 1080 EDS_TIGBTOvHiFault_FWD 1 "Error" 0 "Normal";
VAL_ 1080 EDS_TIGBTOvHiWarn_FWD 1 "Error" 0 "Normal";
VAL_ 1080 EDS_IOHWABSampFail_FWD 1 "Error" 0 "Normal";
VAL_ 1080 EDS_EDSOpenFault_FWD 1 "Error" 0 "Normal";
VAL_ 1080 EDS_MotorOpenFault_FWD 1 "Error" 0 "Normal";
VAL_ 1080 EDS_EmacBlkdWarn_FWD 1 "Error" 0 "Normal";
VAL_ 1080 EDS_VerMatchFailureErr_FWD 1 "Error" 0 "Normal";
VAL_ 1080 EDS_DiashCirNoPsblErr_FWD 1 "Error" 0 "Normal";
VAL_ 1080 EDS_OperOutdRngErr_FWD 1 "Error" 0 "Normal";
VAL_ 1080 EDS_PhaseLossFaultErr_FWD 1 "Error" 0 "Normal";
VAL_ 1080 EDS_CPLDFault_FWD 1 "Error" 0 "Normal";
VAL_ 1080 EDS_CPLDFaultBaseSpd_FWD 1 "Error" 0 "Normal";
VAL_ 1080 EDS_IOHWABNen33Fail_FWD 1 "Error" 0 "Normal";
VAL_ 1080 EDS_HvMcuSlightFault_RWD 1 "Error" 0 "Normal";
VAL_ 1080 EDS_HvMcuSevFault_FWD 1 "Error" 0 "Normal";
VAL_ 1080 EDS_EDSPhaSampHWFault_FWD 1 "Error" 0 "Normal";
VAL_ 1080 EDS_IsOvHiErr_FWD 1 "Error" 0 "Normal";
VAL_ 1080 EDS_CanRollingCounterErr_FWD 1 "Error" 0 "Normal";
VAL_ 1080 EDS_CanTimeoutErr_FWD 1 "Error" 0 "Normal";
VAL_ 1080 EDS_CrashFault_FWD 1 "Error" 0 "Normal";
VAL_ 537 Rolling_Counter_0x219 15 "Invalid";
VAL_ 537 VCU_ChargeAllow 1 "Allow " 0 "Not allow";
VAL_ 544 Rolling_Counter_0x220 15 "Invalid";
VAL_ 544 VCU_BMS_PTCOnOff_Sts 1 "on " 0 "off";
VAL_ 544 VCU_BMS_ValveOnOff_Sts 1 "open " 0 "close";
VAL_ 544 VCU_BMS_PumpFB 3 "Reserve" 2 "Fault" 1 "ON" 0 "OFF";
VAL_ 757 VCU_Charge_Control 2 "Forbid" 1 "Allowed" 0 "Default";
VAL_ 757 VCU_AC_chargeSock_temp1 2047 "Invaild";
VAL_ 757 VCU_DC_chargeSock_temp1 2047 "Invaild";
VAL_ 757 VCU_DC_chargeSock_temp2 2047 "Invaild";
VAL_ 725 VCU_DCDC_Output_REQ 1 "enable" 0 "disable";
VAL_ 725 VCU_DCDC_OutVoltage_REQ 511 "Invalid";
VAL_ 725 VCU_DCDCAllowedPower 511 "Invalid";
VAL_ 553 Rolling_Counter_0x229 15 "Invalid";
VAL_ 553 VCU_EDS_TargetTqMin_FWD 1023 "Invalid";
VAL_ 553 VCU_EDS_StsModeReq_FWD 15 "invaild" 14 "power off" 13 "Failure" 12 "after run" 11 "shut down" 5 "HVReady" 4 "normal" 3 "precharge" 2 "standby" 1 "init" 0 "default";
VAL_ 553 VCU_EDS_demtrq_FWD 4095 "Invalid";
VAL_ 553 VCU_EDS_demtrqValid_FWD 0 "Valid" 1 "Invalid";
VAL_ 553 VCU_EDS_TargetTqMax_FWD 1023 "Invalid";
VAL_ 553 VCU_EDS_CreepFlg_FWD 1 "Enable" 0 "Disable";
VAL_ 553 VCU_EDS_HILLHoldFlg_FWD 1 "Enable" 0 "Disable";
VAL_ 937 VCU_PTC_RelaySts 1 "close" 0 "open";
VAL_ 937 VCU_EACEnbReq 1 "Enable" 0 "Disable";
VAL_ 937 VCU_EACAllowedPower 1023 "Invalid";
VAL_ 937 VCU_EAC_CompSpdReq 16383 "Invaild";
VAL_ 425 VCU_RegenLevel_Feed 3 "invalid" 2 "High" 1 "Low" 0 "none";
VAL_ 425 VCU_RBCSts 1 "active" 0 "incative";
VAL_ 425 VCU_RDCSts 1 "active" 0 "incative";
VAL_ 425 VCU_Veh_ERR 1 "Error" 0 "Normal";
VAL_ 425 VCU_DrvSys_ERR 1 "Error" 0 "Normal";
VAL_ 425 VCU_PackSys_ERR 1 "Error" 0 "Normal";
VAL_ 425 VCU_TBOX_Veh_STS_Reserved 3 "Other" 2 "Off" 1 "Start" 0 "Invalid";
VAL_ 425 VCU_VehChg_STS 3 "Charge fault" 2 "Charging complete" 1 "Charging in progress" 0 "Charging not in progress";
VAL_ 425 VCU_BatterVoltage_Reserved 255 "Invalid";
VAL_ 425 VCU_BatteryVoltErr_Reserved 1 "warning" 0 "no warning";
VAL_ 425 VCU_MotorCoolingCircuitErr_Reserved 1 "Error" 0 "Normal";
VAL_ 425 VCU_PackCoolingCircuitErr_Reserved 1 "Error" 0 "Normal";
VAL_ 425 VCU_VehicleHVStatus 3 "Reserved" 2 "ReadyToDrive" 1 "HV On" 0 "Not ready";
VAL_ 425 VCU_InstantPowerConsump 1023 "Invalid";
VAL_ 425 VCU_AveragePowerConsump 1023 "Invalid";
VAL_ 425 VCU_BrakePedalSts 3 "Invalid" 2 "Reserved" 1 "pressed" 0 "Not pressed";
VAL_ 992 Rolling_Counter_0x3E0 15 "Invalid";
VAL_ 992 VCU_MHU_Ack_ChgSche_stt 0 "Disabled" 1 "Enabled" 2 "Reserved" 3 "Invalid";
VAL_ 992 VCU_MHU_GuestMode_sts 0 "OFF" 1 "ON" 2 "Reserved" 3 "Reserved";
VAL_ 992 VCU_ValetMode_sts 0 "Inactive" 1 "Active" 255 "Invalid";
VAL_ 992 VCU_CreepDisable_stt 0 "Enable" 1"Disable";
VAL_ 409 Rolling_Counter_0x199 15 "Invalid";
VAL_ 409 VCU_VehFailGrade_ERR 5 "Level5" 4 "Level4" 3 "Level3" 2 "Level2" 1 "Level1" 0 "Normal";
VAL_ 409 VCU_BMS_HVOnOff_REQ 1 "allow" 0 "forbid";
VAL_ 409 VCU_Vehicle_Mode 9 "Reserved " 8 "Emer Driving Mode " 7 "Reserved" 6 "Charging Mode " 5 "HV-Termination Mode " 4 "Driving Mode " 3 "HV-Activation Mode" 2 "Vehicle Reset Mode " 1 "StandBy IG OFF Mode " 0 "Reserved";
VAL_ 889 VCU_DriveCoolWaterPumpSts 5 "Reserved" 4 "Other error" 3 "Overtemperature" 2 "Locked-rotor" 1 "Idle" 0 "Normal";
VAL_ 889 VCU_DriveCoolWaterDuty 127 "Invalid";
VAL_ 889 VCU_BatteryWaterPumpSts_reserved 5 "Reserved" 4 "Other error" 3 "Overtemperature" 2 "Locked-rotor" 1 "Idle" 0 "Normal";
VAL_ 889 VCU_BatteryWaterPumpDuty_reserved 127 "Invalid";
VAL_ 889 VCU_DriveMode 7 "Invalid" 6 "Reserved" 5 "Reserved" 4 "Reserved" 3 "Reserved" 2 "Sport mode" 1 "ECO mode" 0 "Normal mode";
VAL_ 889 VCU_ActualGear 7 "Fault" 6 "Reserved" 5 "Reserved" 4 "Reserved" 3 "D" 2 "N" 1 "R" 0 "P reserved";
VAL_ 889 VCU_ACTGearValid 1 "nvalid" 0 "Valid";
VAL_ 889 VCU_AccPedal1OutRange 1 "Error" 0 "Normal";
VAL_ 889 VCU_AccPedal2OutRange 1 "Error" 0 "Normal";
VAL_ 889 VCU_BrkPedal1OutRange 1 "Error" 0 "Normal";
VAL_ 889 VCU_BrkPedal2OutRange 1 "Error" 0 "Normal";
VAL_ 889 VCU_BrkPedalPct 255 "Invalid";
VAL_ 889 VCU_AccPedalPosition 255 "Invalid";
VAL_ 889 VCU_AccPedalPositionValid 1 "Invalid" 0 "Valid";
VAL_ 889 VCU_SocDisplay_EST 127 "Invalid";
VAL_ 889 VCU_PowerLimit 1 "Limit" 0 "No Limit";
VAL_ 889 VCU_CruiseCtrlSts 3 "takeover mode" 2 "Pre cruise(lamp flash)" 1 "Cruise on(lamp on)" 0 "Cruise off(lamp off)";
VAL_ 889 VCU_LowSOC_ERR 1 "Error" 0 "No Error";
VAL_ 905 VCU_FanControl_Sts 2 "FAN High " 1 "FAN Low " 0 " off";
VAL_ 905 VCU_IMMO_Sts 2 "failed " 1 "pass " 0 "init";
VAL_ 905 VCU_VacuumSts_reserved 3 "Invalid" 2 "quick leak " 1 "slow leak " 0 "Normal";
VAL_ 905 VCU_VacuumPresWrn 3 "Invalid" 2 "Serious Insufficient " 1 "Slight Insufficient " 0 "Normal";
VAL_ 1145 VCU_EDSCAN_ERR 1 "Error" 0 "Normal";
VAL_ 1145 VCU_BmsCAN_ERR 1 "Error" 0 "Normal";
VAL_ 1145 VCU_DcdcCAN_ERR 1 "Error" 0 "Normal";
VAL_ 1145 VCU_AbsCAN_ERR 1 "Error" 0 "Normal";
VAL_ 1145 VCU_AcmCAN_ERR 1 "Error" 0 "Normal";
VAL_ 1145 VCU_XgwCAN_ERR 1 "Error" 0 "Normal";
VAL_ 1145 VCU_ObcCAN_ERR 1 "Error" 0 "Normal";
VAL_ 1145 VCU_BcmCAN_ERR_reserved 1 "Error" 0 "Normal";
VAL_ 1145 VCU_WaterPump_ERR 1 "Error" 0 "Normal";
VAL_ 1145 VCU_BrakeSys_Err 1 "Error" 0 "Normal";
VAL_ 1145 VCU_PreChgFail_ERR_Reserved 1 "Error" 0 "Normal";
VAL_ 1145 VCU_LowBattery_ERR 1 "Error" 0 "Normal";
VAL_ 1145 VCU_AccPed_ERR 1 "Error" 0 "Normal";
VAL_ 1145 VCU_BrkPed_ERR 1 "Error" 0 "Normal";
VAL_ 1145 VCU_EPSCAN_ERR 1 "Error" 0 "Normal";
VAL_ 1145 VCU_PtcModu_ERR_Reserved 1 "Error" 0 "Normal";
VAL_ 1145 VCU_Shift_ERR 1 "Error" 0 "Normal";
VAL_ 1145 VCU_FlgHVIL_ERR 1 "Error" 0 "Normal";
VAL_ 1145 VCU_EKSCAN_ERR 1 "Error" 0 "Normal";
VAL_ 1145 VCU_VehLvInit_ERR_Reserved 1 "Error" 0 "Normal";
VAL_ 1145 VCU_EacCAN_ERR 1 "Error" 0 "Normal";
VAL_ 1145 VCU_EAC_CompFltStat_ERR 1 "Error" 0 "Normal";
VAL_ 745 Rolling_Counter_0x2E9 15 "Invalid";
VAL_ 745 VCU_SetCruiseSpd 255 "Invalid";
VAL_ 792 EAC_CompElecCurrV 0 "Valid" 1 "Invalid";
VAL_ 792 EAC_CompStat 0 "Normal Operation" 1 "Degraded Operation" 2 "Inoperative" 15 "Invalid";
VAL_ 792 EAC_CompElecPwrV 0 "Valid" 1 "Invalid";
VAL_ 792 EAC_CompSpdIncrReq 0 "False" 1 "True";
VAL_ 792 EAC_CompSpdV 0 "Valid" 1 "Invalid";
VAL_ 792 EAC_CompElecPwr 255 "Invaild";
VAL_ 792 EAC_CompSpd 16383 "Invaild";
VAL_ 792 EAC_CompElecCurr 255 "Invaild";
VAL_ 792 EAC_CompFltStat 0 "No Fault" 1 "Under Voltage" 2 "Over Voltage" 3 "Over Temperature" 4 "Input Control" 5 "Current Fault" 6 "Internal Fault" 8 "Motor slip protection" 9 "HVDC input voltage drop protection" 10 "Inside the controller 15V control power supply output undervoltage protection" 11 "Overcurrent frequency limitation and frequency reduction" 15 "Invalid";
VAL_ 793 EAC_CompPhaseCurr 255 "Invaild";
VAL_ 793 EAC_CompIGBTTempV 0 "Valid" 1 "Invalid";
VAL_ 793 EAC_CompHVInputV 0 "Valid" 1 "Invalid";
VAL_ 793 EAC_CompBoardTempV 0 "Valid" 1 "Invalid";
VAL_ 524 Rolling_Counter_0x20C 15 "Invalid";
VAL_ 524 IPC_ODO 1048575 "Invalid";
VAL_ 703 IPC_TripA 65535 "Invalid";
VAL_ 703 IPC_AverageSpeedTripA 4095 "Invalid";
VAL_ 703 IPC_AverageConsumptionTripA 1023 "Invalid";
VAL_ 703 IPC_ParkBrakeSts 3 "Invalid" 2 "Reserved" 1 "Applied" 0 "Released";
VAL_ 703 IPC_VehSpd 32767 "Invalid";
VAL_ 1087 IPC_Sec 63 "Invalid";
VAL_ 1087 IPC_Min 63 "Invalid";
VAL_ 1087 IPC_Hour 31 "Invalid";
VAL_ 1087 IPC_Day 31 "Invalid";
VAL_ 1087 IPC_Month 15 "Invalid";
VAL_ 1087 IPC_Year 255 "Invalid";
VAL_ 1087 IPC_SelfCheckStatus 1 "self-check finish" 0 "self-checking";
VAL_ 1074 Rolling_Counter_0x432 15 "Invalid";
VAL_ 1074 MHU_FOTA_State 0 "INIT" 1 "NORMAL" 2 "FOTA FLASHING" 3 "FOTA-SUSPENDED" 4 "FAIL-SAFE-ERROR" 5 "SHUTDOWN" 6 "REMOTE DIAGNOSTICS" 7 "Invalid";
VAL_ 1027 Rolling_Counter_0x403 15 "Invalid";
VAL_ 1027 MHU_SET_TCS_OnOff 0 "OFF (keep sending for 2 seconds)" 1 "ON (keep sending for 2 seconds)" 2 "No action" 3 "Invalid";
VAL_ 1027 MHU_SET_DrivingModeSwitch 3 "sport mode (should be hold during 1 second)" 2 "normal mode (should be hold during 1 second)" 1 "eco mode (should be hold during 1 second)" 0 "no change request";
VAL_ 1027 MHU_SET_RegenLevel 3 "No action" 2 "High" 1 "Low" 0 "none";
VAL_ 1027 MHU_VCU_CreepDisable_stt 0 "No request" 1 "Creep Disable request" 2 "Reserved" 3 "Invalid";
VAL_ 1027 MHU_HVACTurnON 0 "No request" 1 "ON" 2 "Reserved" 3 "Invalid";
VAL_ 1027 MHU_ChargeScheduleSet 0 "Disabled" 1 "Enabled" 2 "No Action" 3 "Reserved";
VAL_ 1027 MHU_ChargingRequest 0 "Reserved" 1 "Request scheduled start charging" 2 "Request stop" 3 "No effect";
VAL_ 1027 MHU_ValetMode_Activation 0 "Inactive" 1 "Active" 254 "Reserved" 255 "Invalid";
VAL_ 811 CCU_TemperatureGearSts 63 "Invalid" 16 "level 8" 15 "level 7" 14 "level 6" 13 "level 5" 12 "level 4" 11 "level 3" 10 "level 2" 9 "level 1" 8 "level 8" 7 "level 7" 6 "level 6" 5 "level 5" 4 "level 4" 3 "level 3" 2 "level 2" 1 "level 1" 0 "Inactive";
VAL_ 811 CCU_BlowMode_Sts 7 "Invalid" 6 "Reserve" 4 "Foot and window" 3 "Foot" 2 "Foot and Face" 1 "Face" 0 "OFF";
VAL_ 811 CCU_Circulation_Sts 1 "Internal circulation" 0 "Outer circulation";
VAL_ 811 CCU_AC_Req 3 "Invalid" 2 "Reserved" 1 "Requset" 0 "No requset";
VAL_ 811 CCU_AC_Sts 1 "ON" 0 "OFF";
VAL_ 811 CCU_BlowerLevelSts 8 "level 8" 7 "level 7" 6 "level 6" 5 "level 5" 4 "level 4" 3 "level 3" 2 "level 2" 1 "level 1" 0 "OFF";
VAL_ 811 CCU_FrontDefrostSts 1 "On" 0 "Off";
VAL_ 811 CCU_PTC_Req 3 "Invalid" 2 "Reserved" 1 "Requset" 0 "No requset";
VAL_ 811 CCU_PTC_Temperature 1023 "Invaild";
VAL_ 811 CCU_CompSpdMEAS_Comp 8191 "Invalid";
VAL_ 811 CCU_PollutionSts 1 "ON" 0 "OFF";
VAL_ 811 CCU_ExternalTemperature 255 "Invaild";
VAL_ 811 CCU_evaporator_Temperature 31 "Invalid";
VAL_ 811 CCU_ExternalTemperatureFailSts 1 "invalid" 0 "valid";
VAL_ 1015 MFS_OK_Control 0 "Button not Pressed" 1 "Short Press" 2 "Long Press" 3 "Signal invalid";
VAL_ 1015 MFS_SourseControl 0 "Button not Pressed" 1 "Short Press" 2 "Long Press" 3 "Signal invalid";
VAL_ 1015 MFS_VoiceRecognitionOn_Off 0 "Button not Pressed" 1 "Short Press" 2 "Long Press" 3 "Signal invalid";
VAL_ 1015 MFS_TelephoneCall_EndCall 0 "Button not Pressed" 1 "Short Press" 2 "Long Press" 3 "Signal invalid";
VAL_ 1015 MFS_DownControl 0 "Button not Pressed" 1 "Short Press" 2 "Long Press" 3 "Signal invalid";
VAL_ 1015 MFS_UpControl 0 "Button not Pressed" 1 "Short Press" 2 "Long Press" 3 "Signal invalid";
VAL_ 1015 MFS_RightControl 0 "Button not Pressed" 1 "Short Press" 2 "Long Press" 3 "Signal invalid";
VAL_ 1015 MFS_LeftControl 0 "Button not Pressed" 1 "Short Press" 2 "Long Press" 3 "Signal invalid";
VAL_ 1015 MFS_CruiseOn_Off 0 "Button not Pressed" 1 "Short Press" 2 "Long Press" 3 "Signal invalid";
VAL_ 1015 MFS_Failure 0 "No Error" 1 "Error";
VAL_ 1015 MFS_ISAControl 0 "Button not Pressed" 1 "Button Pressed";
VAL_ 1015 MFS_LKAControl 0 "Button not Pressed" 1 "Button Pressed";
VAL_ 1015 MFS_CruiseGapDecrease 0 "Button not Pressed" 1 "Short Press" 2 "Long Press" 3 "Signal invalid";
VAL_ 1015 MFS_CruiseSpeedDecrease 0 "Button not Pressed" 1 "Short Press" 2 "Long Press" 3 "Signal invalid";
VAL_ 1015 MFS_CruiseSpeedIncrease 0 "Button not Pressed" 1 "Short Press" 2 "Long Press" 3 "Signal invalid";
VAL_ 1015 MFS_CruiseCancel 0 " Button not Pressed " 1 "No Action" 2 "Cruise Cancel " 3 "Reserved";
VAL_ 1015 MFS_CruiseGapIncrease 0 "Button not Pressed" 1 "Short Press" 2 "Long Press" 3 "Signal invalid";
VAL_ 274 Rolling_Counter_0x112 15 "Invalid";
VAL_ 274 STAT_Terminal 7 "Signal invalid" 6 "Reserved" 5 "Reserved" 4 "SW update OTA (Not used in VFe34)" 3 "Engine start (eMotor running)" 2 "ON (Driver Present)" 1 "ACC (Park)" 0 "OFF(Comfort Enable)";
VAL_ 274 STAT_CL30s_L_Reserved 3 "Signal invalid" 2 "Failure" 1 "ON" 0 "OFF";
VAL_ 976 BCM_STAT_DoorAjarDriver 3 "Signal invalid" 2 "Reserved" 1 "Opened" 0 "Closed";
VAL_ 976 STAT_DoorLockDriver 3 "Signal invalid" 2 "Reserved" 1 "Locked" 0 "Unlocked";
VAL_ 283 BCM_ACCRelayOutputSts 0 "Inactive" 1 "Active" 2 "Reserved" 3 "Signal Invalid";
VAL_ 283 BCM_IGN1RelayOutputSts 0 "Inactive" 1 "Active" 2 "Reserved" 3 "Signal Invalid";
VAL_ 283 BCM_ACCRelayFalutSts 0 "No Fault" 1 "Fault" 2 "Reserved" 3 "Signal Invalid";
VAL_ 283 BCM_IGN1RelayFalutSts 0 "No Fault" 1 "Fault" 2 "Reserved" 3 "Signal Invalid";
VAL_ 283 BCM_KEY_MatchSts 0 "No Match" 1 "Match Success" 2 "Match Failed" 3 "Matching";
VAL_ 266 Rolling_Counter_0x10a 15 "Invalid";
VAL_ 266 BCM_LVTop_up 1 "start Top up" 0 "stop Top up";
VAL_ 133 Rolling_Counter_0x85 15 "Invalid";
VAL_ 133 ACM_Crash_Sts 3 "Invalid Value" 2 "Invalid Value" 1 "Crash_Detected" 0 "No_Event";
VAL_ 133 ACM_Airbag_Deployment_Status 3 "Invalid Value" 2 "Invalid Value" 1 "Airbag_Deployment" 0 "No_Airbag_Deployment";
VAL_ 133 ACM_Crash_Intensity 7 "Invalid_Value" 6 "Invalid_Value" 5 "Invalid_Value" 4 "Invalid_Value" 3 "Crash_Intensity_3" 2 "Crash_Intensity_2" 1 "Crash_Intensity_1" 0 "No_Crash";
VAL_ 133 ACM_Front_Crash 3 "Invalid Value" 2 "Invalid Value" 1 "Front_Crash_Detected" 0 "No_Event";
VAL_ 133 ACM_DriverSide_Crash 3 "Invalid Value" 2 "Invalid Value" 1 "Driverside_Crash_Detected" 0 "No_Event";
VAL_ 133 ACM_PassSide_Crash 3 "Invalid Value" 2 "Invalid Value" 1 "PassSide_Crash_Detected" 0 "No_Event";
VAL_ 133 ACM_Rear_Crash 3 "Invalid Value" 2 "Invalid Value" 1 "Rear_Crash_Detected" 0 "No_Event";
VAL_ 133 ACM_Rollover_Crash 3 "Invalid Value" 2 "Invalid Value" 1 "Rollover_Crash_Detected" 0 "No_Event";
VAL_ 834 Rolling_Counter_0x342 15 "Invalid";
VAL_ 834 ABS_LRWhlSpdRaw 32767 "Invalid";
VAL_ 834 ABS_LRWhlSpdRawValid 1 "Valid" 0 "Invalid";
VAL_ 834 ABS_RRWhlSpdRaw 32767 "Invalid";
VAL_ 834 ABS_RRWhlSpdRawValid 1 "Valid" 0 "Invalid";
VAL_ 834 ABS_VehSpd 32767 "Invalid";
VAL_ 834 ABS_VehSpdValid 1 "Valid" 0 "Invalid";
VAL_ 149 RollingCounter_0x95 15 "Invalid";
VAL_ 149 ABS_Active 3 "Signal invalid" 2 "Reserved" 1 "Active" 0 "Inactive";
VAL_ 149 ASR_Active 3 "Signal invalid" 2 "Reserved" 1 "Active" 0 "Inactive";
